VERSION ""

NS_ :

BS_:

BU_: MPAD CVADAS ADCAM ORC EVCU2 EPS ECM CVPAM CADM BSM2 BSM

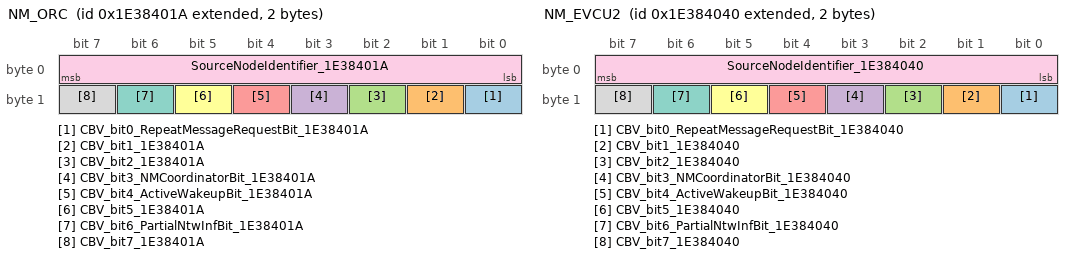
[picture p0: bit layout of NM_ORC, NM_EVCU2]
BO_ 2654486554 NM_ORC: 2 ORC
 SG_ CBV_bit0_RepeatMessageRequestBit_1E38401A : 8|1@0+ (1,0) [0|1] "" CVADAS,ADCAM,MPAD,EVCU2,BSM2,CVPAM,CADM,BSM,EPS,ECM
 SG_ CBV_bit1_1E38401A : 9|1@0+ (1,0) [0|1] "" CVADAS,ADCAM,MPAD,EVCU2,BSM2,CVPAM,CADM,BSM,EPS,ECM
 SG_ CBV_bit2_1E38401A : 10|1@0+ (1,0) [0|1] "" CVADAS,ADCAM,MPAD,EVCU2,BSM2,CVPAM,CADM,BSM,EPS,ECM
 SG_ CBV_bit3_NMCoordinatorBit_1E38401A : 11|1@0+ (1,0) [0|1] "" CVADAS,ADCAM,MPAD,EVCU2,BSM2,CVPAM,CADM,BSM,EPS,ECM
 SG_ CBV_bit4_ActiveWakeupBit_1E38401A : 12|1@0+ (1,0) [0|1] "" CVADAS,ADCAM,MPAD,EVCU2,BSM2,CVPAM,CADM,BSM,EPS,ECM
 SG_ CBV_bit5_1E38401A : 13|1@0+ (1,0) [0|1] "" CVADAS,ADCAM,MPAD,EVCU2,BSM2,CVPAM,CADM,BSM,EPS,ECM
 SG_ CBV_bit6_PartialNtwInfBit_1E38401A : 14|1@0+ (1,0) [0|1] "" CVADAS,ADCAM,MPAD,EVCU2,BSM2,CVPAM,CADM,BSM,EPS,ECM
 SG_ CBV_bit7_1E38401A : 15|1@0+ (1,0) [0|1] "" CVADAS,ADCAM,MPAD,EVCU2,BSM2,CVPAM,CADM,BSM,EPS,ECM
 SG_ SourceNodeIdentifier_1E38401A : 7|8@0+ (1,0) [0|255] "-"  CVADAS,ADCAM,MPAD,EVCU2,BSM2,CVPAM,CADM,BSM,EPS,ECM

BO_ 292 BATTERY_HV_STATUS1: 64 EVCU2
 SG_ BPCM_HV_Trac_Bus_Sts : 36|3@0+ (1,0) [0|7] "" ORC
 SG_ BPCM_HV_Trac_Main_Contac_Sts : 181|3@0+ (1,0) [0|7] "" Vector__XXX
 SG_ BPCM_HV_InternalVoltage : 133|14@0+ (0.1,90.9) [90.9|1729.2] "V"  ORC
 SG_ BPCM_HV_SOC : 33|10@0+ (0.1,0) [0|102.3] "%"  BSM

BO_ 204 AXLE_TORQUE_FD_1: 48 EVCU2
 SG_ Front_AxleTorque_Max : 71|16@0+ (2,-65534) [-65534|65536] "Nm"  BSM
 SG_ Front_AxleTorque_Min : 87|16@0+ (2,-65534) [-65534|65536] "Nm"  BSM
 SG_ Axle_Torque_DrvReqMod : 55|16@0+ (2,-65534) [-65534|65536] "Nm"  ADCAM,MPAD,CADM,BSM
 SG_ Axle_TorqueStatic_D_TTC : 39|16@0+ (2,-65534) [-65534|65536] "Nm"  ADCAM,MPAD,CADM,BSM
 SG_ Total_AxleTorque_Max : 7|16@0+ (2,-65534) [-65534|65536] "Nm"  ADCAM,MPAD,CADM
 SG_ Total_AxleTorque_Min : 23|16@0+ (2,-65534) [-65534|65536] "Nm"  ADCAM,MPAD,CADM,BSM
 SG_ Front_Axle_Est_Regen_Torq : 149|14@0+ (2,0) [0|32764] "Nm"  BSM
 SG_ CRC_AXLE_TORQUE_FD_1 : 319|8@0+ (1,0) [0|255] "-"  ADCAM,CADM,BSM
 SG_ MessageCounter_AXLE_TORQUE_FD_1 : 307|4@0+ (1,0) [0|15] "-"  ADCAM,CADM,BSM
 SG_ Rear_AxleTorque_Min : 119|16@0+ (2,-65534) [-65534|65536] "Nm"  BSM
 SG_ Rear_AxleTorque_Max : 103|16@0+ (2,-65534) [-65534|65536] "Nm"  BSM
 SG_ Rear_Axle_Regen_Capacity : 197|14@0+ (2,0) [0|32764] "Nm"  BSM
 SG_ Rear_Axle_Est_Regen_Torq : 181|14@0+ (2,0) [0|32764] "Nm"  BSM
 SG_ Front_Axle_Regen_Capacity : 165|14@0+ (2,0) [0|32764] "Nm"  BSM

BO_ 205 BRAKE_FD_6: 64 BSM
 SG_ FrontAxle_Rq_BSM : 63|16@0+ (2,-65534) [-65534|65536] "Nm"  EVCU2
 SG_ DriverRequested_AxleTrq_BSM : 159|16@0+ (2,-65534) [-65534|65536] "Nm"  EVCU2,CVPAM,ECM
 SG_ TotalAxle_Rq_BSM : 95|16@0+ (2,-65534) [-65534|65536] "Nm"  ECM
 SG_ Cmnd_TotBrkFrict_AxleTorq : 126|15@0+ (2,0) [0|65532] "Nm"  EVCU2
 SG_ DriverReq_AxleTrq_Enabled_BSM : 175|4@0+ (1,0) [0|15] "" CVADAS,EVCU2,ECM
 SG_ DrvrIntd_TotalBrk_AxleTorq : 142|15@0+ (2,0) [0|65532] "Nm"  EVCU2
 SG_ TotalAxle_Max_Rq_BSM : 51|1@0+ (1,0) [0|1] "" ECM
 SG_ TotalAxle_Min_Rq_BSM : 50|1@0+ (1,0) [0|1] "" ECM
 SG_ FrontAxle_Max_Rq_BSM : 55|1@0+ (1,0) [0|1] "" EVCU2
 SG_ FrontAxle_Min_Rq_BSM : 54|1@0+ (1,0) [0|1] "" EVCU2
 SG_ MessageCounter_BRAKE_FD_6 : 435|4@0+ (1,0) [0|15] "-"  EVCU2,ECM
 SG_ CRC_BRAKE_FD_6 : 447|8@0+ (1,0) [0|255] "-"  EVCU2,ECM
 SG_ RearAxle_Rq_BSM : 79|16@0+ (2,-65534) [-65534|65536] "Nm"  EVCU2
 SG_ RearAxle_Min_Rq_BSM : 52|1@0+ (1,0) [0|1] "" EVCU2
 SG_ RearAxle_Max_Rq_BSM : 53|1@0+ (1,0) [0|1] "" EVCU2

BO_ 1472 TRSCM_FD_1: 32 CVADAS
 SG_ CRC_TRSCM1 : 191|8@0+ (1,0) [0|255] "-"  BSM,EPS,ECM
 SG_ MessageCounter_TRSCM1 : 179|4@0+ (1,0) [0|15] "-"  BSM,EPS,ECM
 SG_ THA_EPB_Req : 95|2@0+ (1,0) [0|3] "" BSM
 SG_ THA_Speed_Limit : 85|5@0+ (1,0) [0|31] "" EVCU2,BSM,EPS,ECM
 SG_ THA_SpeedLimit_Req : 52|2@0+ (1,0) [0|3] "" EVCU2,BSM,ECM
 SG_ THA_STAT : 55|3@0+ (1,0) [0|6] "" EVCU2,BSM,EPS,ECM
 SG_ TRSC_SpeedLimit_Req : 15|4@0+ (1,0) [0|14] "" BSM,ECM
 SG_ TRSC_STAT : 7|3@0+ (1,0) [0|6] "" BSM,EPS,ECM
 SG_ TRSC_VehicleStop_Req : 36|2@0+ (1,0) [0|2] "" BSM
 SG_ TRSC_SteeringTorqueReq : 11|2@0+ (1,0) [0|2] "" EPS
 SG_ TRSC_SteeringTorqueInfo : 31|11@0+ (0.0078125,-8) [-8|7.9921875] "" EPS
 SG_ TRSC_SteeringDamping : 23|8@0+ (0.78125,0) [0|199.21875] "%"  EPS
 SG_ THA_SteeringTorqueReq : 87|2@0+ (1,0) [0|3] "" EPS
 SG_ THA_SteeringTorqueInfo : 63|11@0+ (0.0078125,-8) [-8|7.9921875] "" EPS
 SG_ THA_SteeringDamping : 79|8@0+ (0.78125,0) [0|199.21875] "%"  EPS

BO_ 2654486592 NM_EVCU2: 2 EVCU2
 SG_ CBV_bit0_RepeatMessageRequestBit_1E384040 : 8|1@0+ (1,0) [0|1] "" CVADAS,ADCAM,MPAD,BSM2,CVPAM,CADM,BSM,ORC,EPS,ECM
 SG_ CBV_bit1_1E384040 : 9|1@0+ (1,0) [0|1] "" CVADAS,ADCAM,MPAD,BSM2,CVPAM,CADM,BSM,ORC,EPS,ECM
 SG_ CBV_bit2_1E384040 : 10|1@0+ (1,0) [0|1] "" CVADAS,ADCAM,MPAD,BSM2,CVPAM,CADM,BSM,ORC,EPS,ECM
 SG_ CBV_bit3_NMCoordinatorBit_1E384040 : 11|1@0+ (1,0) [0|1] "" CVADAS,ADCAM,MPAD,BSM2,CVPAM,CADM,BSM,ORC,EPS,ECM
 SG_ CBV_bit4_ActiveWakeupBit_1E384040 : 12|1@0+ (1,0) [0|1] "" CVADAS,ADCAM,MPAD,BSM2,CVPAM,CADM,BSM,ORC,EPS,ECM
 SG_ CBV_bit5_1E384040 : 13|1@0+ (1,0) [0|1] "" CVADAS,ADCAM,MPAD,BSM2,CVPAM,CADM,BSM,ORC,EPS,ECM
 SG_ CBV_bit6_PartialNtwInfBit_1E384040 : 14|1@0+ (1,0) [0|1] "" CVADAS,ADCAM,MPAD,BSM2,CVPAM,CADM,BSM,ORC,EPS,ECM
 SG_ CBV_bit7_1E384040 : 15|1@0+ (1,0) [0|1] "" CVADAS,ADCAM,MPAD,BSM2,CVPAM,CADM,BSM,ORC,EPS,ECM
 SG_ SourceNodeIdentifier_1E384040 : 7|8@0+ (1,0) [0|255] "-"  CVADAS,ADCAM,MPAD,BSM2,CVPAM,CADM,BSM,ORC,EPS,ECM

BO_ 263 PT_SYSTEM_FD_1: 64 EVCU2
 SG_ CRC_PT_SYSTEM_FD_1 : 447|8@0+ (1,0) [0|255] "-"  ADCAM,MPAD,CADM,BSM,EPS,ECM
 SG_ GasPedalPosition_PT : 31|8@0+ (0.392,0) [0|99.96] "%"  BSM
 SG_ GasPedalPositionFailSts_PT : 145|1@0+ (1,0) [0|1] "" ADCAM,CADM,BSM
 SG_ MessageCounter_PT_SYSTEM_FD_1 : 435|4@0+ (1,0) [0|15] "-"  ADCAM,MPAD,CADM,BSM,EPS,ECM
 SG_ DriveReady_PT : 166|1@0+ (1,0) [0|1] "" BSM,EPS
 SG_ GearEngaged_PT : 132|4@0+ (1,0) [0|15] "" ADCAM,BSM2,BSM,EPS
 SG_ GearEngagedForDisplay_PT : 12|5@0+ (1,0) [0|31] "" CVADAS,ADCAM,EPS
 SG_ PowertrainPrplsnActv_PT : 146|1@0+ (1,0) [0|1] "" CVADAS,ADCAM,MPAD,CADM,BSM,EPS
 SG_ TargetGear_PT : 55|4@0+ (1,0) [0|15] "" EPS
 SG_ ShiftLeverPosition_PT : 51|4@0+ (1,0) [0|15] "" ADCAM,CVPAM,BSM,EPS
 SG_ PdlPosActual_PT : 39|8@0+ (0.4,0) [0|102] "%"  CVADAS,ADCAM,MPAD,BSM2,CVPAM,CADM,BSM
 SG_ SpeedLimitSts_PT : 140|3@0+ (1,0) [0|7] "" Vector__XXX
 SG_ ISASts_PT : 149|1@0+ (1,0) [0|1] "" Vector__XXX
 SG_ EVCU2_THA_Resp : 220|2@0+ (1,0) [0|3] "" CVADAS

BO_ 1580 HYBRID_POWERTRAIN6: 32 EVCU2
 SG_ Motor2_RPM : 23|16@0+ (1,-32768) [-32768|32767] "RPM"  ORC
 SG_ Motor1_RPM : 7|16@0+ (1,-32768) [-32768|32767] "RPM"  ORC

BO_ 299 ADAS_FD_INFO3: 32 ADCAM
 SG_ ACC_Axle_Torque_Enabled : 180|1@0+ (1,0) [0|1] "" BSM
 SG_ ACC_Axle_Torque : 7|16@0+ (2,-65534) [-65534|65536] "Nm"  BSM
 SG_ MessageCounter_ADAS_FD_INFO3 : 179|4@0+ (1,0) [0|15] "-"  MPAD,BSM
 SG_ CRC_ADAS_FD_INFO3 : 191|8@0+ (1,0) [0|255] "-"  MPAD,BSM

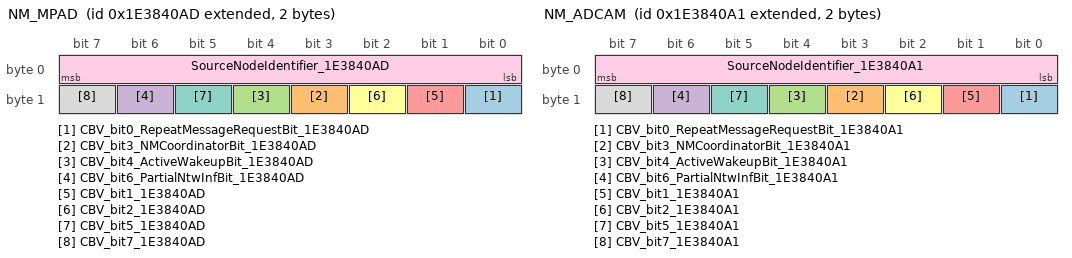
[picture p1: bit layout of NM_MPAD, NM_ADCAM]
BO_ 2654486701 NM_MPAD: 2 MPAD
 SG_ CBV_bit0_RepeatMessageRequestBit_1E3840AD : 8|1@0+ (1,0) [0|1] "-"  CVADAS,ADCAM,EVCU2,BSM2,BSM,ORC,EPS
 SG_ CBV_bit3_NMCoordinatorBit_1E3840AD : 11|1@0+ (1,0) [0|1] "-"  CVADAS,ADCAM,EVCU2,BSM2,BSM,ORC,EPS
 SG_ CBV_bit4_ActiveWakeupBit_1E3840AD : 12|1@0+ (1,0) [0|1] "-"  CVADAS,ADCAM,EVCU2,BSM2,BSM,ORC,EPS
 SG_ CBV_bit6_PartialNtwInfBit_1E3840AD : 14|1@0+ (1,0) [0|1] "-"  CVADAS,ADCAM,EVCU2,BSM2,BSM,ORC,EPS
 SG_ CBV_bit1_1E3840AD : 9|1@0+ (1,0) [0|1] "" CVADAS,ADCAM,EVCU2,BSM2,BSM,ORC,EPS
 SG_ CBV_bit2_1E3840AD : 10|1@0+ (1,0) [0|1] "" CVADAS,ADCAM,EVCU2,BSM2,BSM,ORC,EPS
 SG_ CBV_bit5_1E3840AD : 13|1@0+ (1,0) [0|1] "" CVADAS,ADCAM,EVCU2,BSM2,BSM,ORC,EPS
 SG_ CBV_bit7_1E3840AD : 15|1@0+ (1,0) [0|1] "" CVADAS,ADCAM,EVCU2,BSM2,BSM,ORC,EPS
 SG_ SourceNodeIdentifier_1E3840AD : 7|8@0+ (1,0) [0|255] "-"  CVADAS,ADCAM,EVCU2,BSM2,BSM,ORC,EPS

BO_ 2654486689 NM_ADCAM: 2 ADCAM
 SG_ CBV_bit0_RepeatMessageRequestBit_1E3840A1 : 8|1@0+ (1,0) [0|1] "-"  CVADAS,MPAD,EVCU2,BSM2,BSM,ORC,EPS,ECM
 SG_ CBV_bit3_NMCoordinatorBit_1E3840A1 : 11|1@0+ (1,0) [0|1] "-"  CVADAS,MPAD,EVCU2,BSM2,BSM,ORC,EPS,ECM
 SG_ CBV_bit4_ActiveWakeupBit_1E3840A1 : 12|1@0+ (1,0) [0|1] "-"  CVADAS,MPAD,EVCU2,BSM2,BSM,ORC,EPS,ECM
 SG_ CBV_bit6_PartialNtwInfBit_1E3840A1 : 14|1@0+ (1,0) [0|1] "-"  CVADAS,MPAD,EVCU2,BSM2,BSM,ORC,EPS,ECM
 SG_ CBV_bit1_1E3840A1 : 9|1@0+ (1,0) [0|1] "" CVADAS,MPAD,EVCU2,BSM2,BSM,ORC,EPS,ECM
 SG_ CBV_bit2_1E3840A1 : 10|1@0+ (1,0) [0|1] "" CVADAS,MPAD,EVCU2,BSM2,BSM,ORC,EPS,ECM
 SG_ CBV_bit5_1E3840A1 : 13|1@0+ (1,0) [0|1] "" CVADAS,MPAD,EVCU2,BSM2,BSM,ORC,EPS,ECM
 SG_ CBV_bit7_1E3840A1 : 15|1@0+ (1,0) [0|1] "" CVADAS,MPAD,EVCU2,BSM2,BSM,ORC,EPS,ECM
 SG_ SourceNodeIdentifier_1E3840A1 : 7|8@0+ (1,0) [0|255] "-"  CVADAS,MPAD,EVCU2,BSM2,BSM,ORC,EPS,ECM

BO_ 210 ADAS_FD_INFO3_VIP: 32 ADCAM
 SG_ ACC_Axle_Torque_VIP : 7|16@0+ (2,-65534) [-65534|65536] "Nm"  MPAD

BO_ 209 ADAS_FD_INFO_VIP: 32 ADCAM
 SG_ Intervention_VIP : 163|12@0+ (0.01,-16) [-16|24.95] "m/s2"  MPAD
 SG_ AEB_Type_VIP : 167|4@0+ (1,0) [0|15] "No_Unit"  MPAD
 SG_ ACC_Systemsts_VIP : 183|4@0+ (1,0) [0|15] "No_Unit"  MPAD
 SG_ ACC_Engine_Torque_Enabled_VIP : 111|1@0+ (1,0) [0|1] "No_Unit"  MPAD
 SG_ TorqueOverlaySteeringReq_VIP : 130|11@0+ (0.0048828125,-5) [-5|4.9951171875] "No_Unit"  MPAD
 SG_ SteeringVibration_Type_VIP : 67|4@0+ (1,0) [0|15] "No_Unit"  MPAD
 SG_ SteeringVibration_Rq_VIP : 135|1@0+ (1,0) [0|1] "No_Unit"  MPAD
 SG_ Prefill_Req_VIP : 91|1@0+ (1,0) [0|1] "No_Unit"  MPAD
 SG_ PEB_SystemSts_VIP : 90|1@0+ (1,0) [0|1] "No_Unit"  MPAD
 SG_ Object_Dist_VIP : 127|8@0+ (1,0) [0|255] "m"  MPAD
 SG_ LKA_LAT_CTRL_RequestSts_VIP : 108|2@0+ (1,0) [0|3] "No_Unit"  MPAD
 SG_ LC_Jerk_VIP : 104|1@0+ (1,0) [0|1] "No_Unit"  MPAD
 SG_ GrMax_Rq_ACC_VIP : 150|4@0+ (1,0) [0|15] "No_Unit"  MPAD
 SG_ DDD_SystemSts_VIP : 103|1@0+ (1,0) [0|1] "No_Unit"  MPAD
 SG_ DDD_Setting_Avail_VIP : 102|1@0+ (1,0) [0|1] "No_Unit"  MPAD
 SG_ CIPV_Fused_VIP : 101|1@0+ (1,0) [0|1] "No_Unit"  MPAD
 SG_ Brake_Jerk_Req_VIP : 100|1@0+ (1,0) [0|1] "No_Unit"  MPAD
 SG_ AEB_Systemsts_VIP : 99|2@0+ (1,0) [0|3] "No_Unit"  MPAD
 SG_ AEB_Sensitivity_Setting_VIP : 1|2@0+ (1,0) [0|3] "No_Unit"  MPAD
 SG_ ACC_DsrSpeedKPH_VIP : 119|8@0+ (1,0) [0|255] "km/h"  MPAD
 SG_ MessageCounter_ADAS_FD_INFO_VIP : 179|4@0+ (1,0) [0|15] "No_Unit"  MPAD
 SG_ CRC_ADAS_FD_INFO_VIP : 191|8@0+ (1,0) [0|255] "No_Unit"  MPAD

BO_ 616 ADAS_FD_HMI_VIP: 32 ADCAM
 SG_ Set_Speed_MPH_VIP : 15|8@0+ (1,0) [0|255] "mph"  MPAD
 SG_ Set_Speed_KPH_VIP : 7|8@0+ (1,0) [0|255] "kph"  MPAD
 SG_ RR_Chime_RqSts_VIP : 99|1@0+ (1,0) [0|1] "No_Unit"  MPAD
 SG_ PEB_Setting_Avail_VIP : 78|1@0+ (1,0) [0|1] "No_Unit"  MPAD
 SG_ LR_Chime_RqSts_VIP : 100|1@0+ (1,0) [0|1] "No_Unit"  MPAD
 SG_ LKA_FailSts_VIP : 84|1@0+ (1,0) [0|1] "No_Unit"  MPAD
 SG_ LKA_Blind_VIP : 86|1@0+ (1,0) [0|1] "No_Unit"  MPAD
 SG_ ICA_Blind_VIP : 55|1@0+ (1,0) [0|1] "No_Unit"  MPAD
 SG_ FCW_Setting_Avail_VIP : 77|1@0+ (1,0) [0|1] "No_Unit"  MPAD
 SG_ DDD_FailSts_VIP : 96|1@0+ (1,0) [0|1] "No_Unit"  MPAD
 SG_ DDD_DispPopupSts_VIP : 39|2@0+ (1,0) [0|3] "No_Unit"  MPAD
 SG_ BSS_TrailerSts_VIP : 175|3@0+ (1,0) [0|7] "No_Unit"  MPAD
 SG_ BSS_SRV_RQSts_VIP : 88|1@0+ (1,0) [0|1] "No_Unit"  MPAD
 SG_ BSS_DispPopoupSts_VIP : 132|3@0+ (1,0) [0|7] "No_Unit"  MPAD
 SG_ BSS_CFG_STATSts_VIP : 103|2@0+ (1,0) [0|3] "No_Unit"  MPAD
 SG_ BSS_Blind_RQSts_VIP : 101|1@0+ (1,0) [0|1] "No_Unit"  MPAD
 SG_ BlindSpotRightWarn_VIP : 171|2@0+ (1,0) [0|3] "No_Unit"  MPAD
 SG_ BlindSpotLeftWarn_VIP : 105|2@0+ (1,0) [0|3] "No_unit"  MPAD
 SG_ AEB_Limited_VIP : 72|1@0+ (1,0) [0|1] "No_Unit"  MPAD
 SG_ AEB_Limit_Fail_VIP : 74|1@0+ (1,0) [0|1] "No_Unit"  MPAD
 SG_ AEB_FailSts_VIP : 83|1@0+ (1,0) [0|1] "No_Unit"  MPAD
 SG_ AEB_DispPopupSts_VIP : 37|6@0+ (1,0) [0|63] "No_Unit"  MPAD
 SG_ AEB_Blind_VIP : 76|1@0+ (1,0) [0|1] "No_Unit"  MPAD
 SG_ MessageCounter_ADAS_FD_HMI_VIP : 179|4@0+ (1,0) [0|15] "No_Unit"  MPAD
 SG_ CRC_ADAS_FD_HMI_VIP : 191|8@0+ (1,0) [0|255] "No_Unit"  MPAD

BO_ 213 VIP_INFO_FD: 32 MPAD
 SG_ ACCFSafe_D5 : 7|8@0+ (1,0) [0|255] "No_Unit"  ADCAM
 SG_ AEB_Type_Brk_D5 : 11|4@0+ (1,0) [0|15] "No_Unit"  ADCAM
 SG_ DASEngReqPos_D5 : 20|1@0+ (1,0) [0|1] "No_Unit"  ADCAM
 SG_ LKA_LAT_CTRL_ResponseSts_D5 : 13|2@0+ (1,0) [0|3] "No_Unit"  ADCAM
 SG_ RRCC_Cancel_Req_D5 : 15|2@0+ (1,0) [0|3] "No_Unit"  ADCAM
 SG_ MessageCounter_VIP_INFO_FD : 179|4@0+ (1,0) [0|15] "No_Unit"  ADCAM
 SG_ CRC_VIP_INFO_FD : 191|8@0+ (1,0) [0|255] "No_Unit"  ADCAM

BO_ 97 GT_MASTER_FD: 16 MPAD
 SG_ SyncTime : 39|32@0+ (1,0) [0|0] "" CVADAS,BSM2,BSM,ORC
 SG_ OfsTimeSec : 71|32@0+ (1,0) [0|0] "sec"  CVADAS,BSM2,BSM,ORC
 SG_ OfsTimeNSec : 103|32@0+ (1,0) [0|0] "" CVADAS,BSM2,BSM,ORC
 SG_ GTS_Type : 7|8@0+ (1,0) [0|255] "" CVADAS,BSM2,BSM,ORC
 SG_ GTS_SC : 19|4@0+ (1,0) [0|15] "" CVADAS,BSM2,BSM,ORC
 SG_ GTS_D : 23|4@0+ (1,0) [0|16] "" CVADAS,BSM2,BSM,ORC
 SG_ GTS_CRC : 15|8@0+ (1,0) [0|255] "" CVADAS,BSM2,BSM,ORC
 SG_ GTS_Byte3 : 31|8@0+ (1,0) [0|255] "" CVADAS,BSM2,BSM,ORC

BO_ 734 ADAS_FD_LANES_2: 64 CVADAS
 SG_ Segment_8_Y2 : 369|10@0+ (0.01,-5) [-5|5.23] "m"  CADM
 SG_ Segment_8_Y1 : 201|10@0+ (0.01,-5) [-5|5.23] "m"  CADM
 SG_ Segment_8_X2 : 290|11@0+ (0.03,-21) [-21|40.41] "m"  CADM
 SG_ Segment_8_X1 : 122|11@0+ (0.03,-21) [-21|40.41] "m"  CADM
 SG_ Segment_8_ID : 43|4@0+ (1,0) [0|15] "" CADM
 SG_ Segment_8_Confidence : 411|4@0+ (0.1,0) [0|1.5] "" CADM
 SG_ Segment_7_Y2 : 363|10@0+ (0.01,-5) [-5|5.23] "m"  CADM
 SG_ Segment_7_Y1 : 195|10@0+ (0.01,-5) [-5|5.23] "m"  CADM
 SG_ Segment_7_X2 : 285|11@0+ (0.03,-21) [-21|40.41] "m"  CADM
 SG_ Segment_7_X1 : 117|11@0+ (0.03,-21) [-21|40.41] "m"  CADM
 SG_ Segment_7_ID : 47|4@0+ (1,0) [0|15] "" CADM
 SG_ Segment_7_Confidence : 415|4@0+ (0.1,0) [0|1.5] "" CADM
 SG_ Segment_6_Y2 : 357|10@0+ (0.01,-5) [-5|5.23] "m"  CADM
 SG_ Segment_6_Y1 : 189|10@0+ (0.01,-5) [-5|5.23] "m"  CADM
 SG_ Segment_6_X2 : 264|11@0+ (0.03,-21) [-21|40.41] "m"  CADM
 SG_ Segment_6_X1 : 96|11@0+ (0.03,-21) [-21|40.41] "m"  CADM
 SG_ Segment_6_ID : 35|4@0+ (1,0) [0|15] "" CADM
 SG_ Segment_6_Confidence : 403|4@0+ (0.1,0) [0|1.5] "" CADM
 SG_ Segment_5_Y2 : 351|10@0+ (0.01,-5) [-5|5.23] "m"  CADM
 SG_ Segment_5_Y1 : 183|10@0+ (0.01,-5) [-5|5.23] "m"  CADM
 SG_ Segment_5_X2 : 259|11@0+ (0.03,-21) [-21|40.41] "m"  CADM
 SG_ Segment_5_X1 : 91|11@0+ (0.03,-21) [-21|40.41] "m"  CADM
 SG_ Segment_5_ID : 39|4@0+ (1,0) [0|15] "" CADM
 SG_ Segment_5_Confidence : 407|4@0+ (0.1,0) [0|1.5] "" CADM
 SG_ Segment_4_Y2 : 329|10@0+ (0.01,-5) [-5|5.23] "m"  CADM
 SG_ Segment_4_Y1 : 161|10@0+ (0.01,-5) [-5|5.23] "m"  CADM
 SG_ Segment_4_X2 : 254|11@0+ (0.03,-21) [-21|40.41] "m"  CADM
 SG_ Segment_4_X1 : 86|11@0+ (0.03,-21) [-21|40.41] "m"  CADM
 SG_ Segment_4_ID : 27|4@0+ (1,0) [0|15] "" CADM
 SG_ Segment_4_Confidence : 395|4@0+ (0.1,0) [0|1.5] "" CADM
 SG_ Segment_3_Y2 : 323|10@0+ (0.01,-5) [-5|5.23] "m"  CADM
 SG_ Segment_3_Y1 : 155|10@0+ (0.01,-5) [-5|5.23] "m"  CADM
 SG_ Segment_3_X2 : 233|11@0+ (0.03,-21) [-21|40.41] "m"  CADM
 SG_ Segment_3_X1 : 65|11@0+ (0.03,-21) [-21|40.41] "m"  CADM
 SG_ Segment_3_ID : 31|4@0+ (1,0) [0|15] "" CADM
 SG_ Segment_3_Confidence : 399|4@0+ (0.1,0) [0|1.5] "" CADM
 SG_ Segment_2_Y2 : 317|10@0+ (0.01,-5) [-5|5.23] "m"  CADM
 SG_ Segment_2_Y1 : 149|10@0+ (0.01,-5) [-5|5.23] "m"  CADM
 SG_ Segment_2_X2 : 228|11@0+ (0.03,-21) [-21|40.41] "m"  CADM
 SG_ Segment_2_X1 : 60|11@0+ (0.03,-21) [-21|40.41] "m"  CADM
 SG_ Segment_2_ID : 19|4@0+ (1,0) [0|15] "" CADM
 SG_ Segment_2_Confidence : 387|4@0+ (0.1,0) [0|1.5] "" CADM
 SG_ Segment_1_Y2 : 311|10@0+ (0.01,-5) [-5|5.23] "m"  CADM
 SG_ Segment_1_Y1 : 143|10@0+ (0.01,-5) [-5|5.23] "m"  CADM
 SG_ Segment_1_X2 : 223|11@0+ (0.03,-21) [-21|40.41] "m"  CADM
 SG_ Segment_1_X1 : 55|11@0+ (0.03,-21) [-21|40.41] "m"  CADM
 SG_ Segment_1_ID : 23|4@0+ (1,0) [0|15] "" CADM
 SG_ Segment_1_Confidence : 391|4@0+ (0.1,0) [0|1.5] "" CADM
 SG_ MessageCounter_ADAS_FD_LANES_2 : 435|4@0+ (1,0) [0|15] "-"  CADM
 SG_ MAC_ADAS_FD_LANES_2 : 471|48@0+ (1,0) [0|0] "-"  CADM
 SG_ Frame_Index_Lanes_2 : 7|16@0+ (1,0) [0|65535] "" CADM
 SG_ CRC_ADAS_FD_LANES_2 : 447|8@0+ (1,0) [0|255] "-"  CADM
 SG_ Cntr_ADAS_FD_LANES_2 : 455|16@0+ (1,0) [0|65535] "-"  CADM
 SG_ Reserved_for_functional_safety_2DE : 431|12@0+ (0,0) [0|0] "" CADM

BO_ 730 ADAS_FD_LANES_1: 64 CVADAS
 SG_ MessageCounter_ADAS_FD_LANES_1 : 435|4@0+ (1,0) [0|15] "-"  CADM
 SG_ MAC_ADAS_FD_LANES_1 : 471|48@0+ (1,0) [0|0] "-"  CADM
 SG_ Line_4_Type : 179|4@0+ (1,0) [0|15] "" CADM
 SG_ Line_4_Start_Range : 294|7@0+ (0.5,-25) [-25|38.5] "m"  CADM
 SG_ Line_4_Offset : 209|10@0+ (0.01,-5) [-5|5.23] "m"  CADM
 SG_ Line_4_Heading : 249|10@0+ (0.0009765625,-0.357) [-0.357|0.6420234375] "rad"  CADM
 SG_ Line_4_End_Range : 326|7@0+ (0.5,-25) [-25|38.5] "m"  CADM
 SG_ Line_4_Curvature_Rate : 143|16@0+ (3.7252902985E-09,-0.000122) [-0.000122|0.0001221368997121975] "" CADM
 SG_ Line_4_Curvature : 79|16@0+ (9.77E-07,-0.032) [-0.032|0.032027694999999995] "" CADM
 SG_ Line_4_Confidence : 163|4@0+ (0.1,0) [0|1.5] "" CADM
 SG_ Line_3_Type : 183|4@0+ (1,0) [0|15] "" CADM
 SG_ Line_3_Start_Range : 287|7@0+ (0.5,-25) [-25|38.5] "m"  CADM
 SG_ Line_3_Offset : 203|10@0+ (0.01,-5) [-5|5.23] "m"  CADM
 SG_ Line_3_Heading : 243|10@0+ (0.0009765625,-0.357) [-0.357|0.6420234375] "rad"  CADM
 SG_ Line_3_End_Range : 319|7@0+ (0.5,-25) [-25|38.5] "m"  CADM
 SG_ Line_3_Curvature_Rate : 127|16@0+ (3.7252902985E-09,-0.000122) [-0.000122|0.0001221368997121975] "" CADM
 SG_ Line_3_Curvature : 63|16@0+ (9.77E-07,-0.032) [-0.032|0.032027694999999995] "" CADM
 SG_ Line_3_Confidence : 167|4@0+ (0.1,0) [0|1.5] "" CADM
 SG_ Line_2_Type : 171|4@0+ (1,0) [0|15] "" CADM
 SG_ Line_2_Start_Range : 278|7@0+ (0.5,-25) [-25|38.5] "m"  CADM
 SG_ Line_2_Offset : 197|10@0+ (0.01,-5) [-5|5.23] "m"  CADM
 SG_ Line_2_Heading : 237|10@0+ (0.0009765625,-0.357) [-0.357|0.6420234375] "rad"  CADM
 SG_ Line_2_End_Range : 310|7@0+ (0.5,-25) [-25|38.5] "m"  CADM
 SG_ Line_2_Curvature_Rate : 111|16@0+ (3.7252902985E-09,-0.000122) [-0.000122|0.0001221368997121975] "" CADM
 SG_ Line_2_Curvature : 47|16@0+ (9.77E-07,-0.032) [-0.032|0.032027694999999995] "" CADM
 SG_ Line_2_Confidence : 155|4@0+ (0.1,0) [0|1.5] "" CADM
 SG_ Line_1_Type : 175|4@0+ (1,0) [0|15] "" CADM
 SG_ Line_1_Start_Range : 271|7@0+ (0.5,-25) [-25|38.5] "m"  CADM
 SG_ Line_1_Offset : 191|10@0+ (0.01,-5) [-5|5.23] "m"  CADM
 SG_ Line_1_Heading : 231|10@0+ (0.0009765625,-0.357) [-0.357|0.6420234375] "rad"  CADM
 SG_ Line_1_End_Range : 303|7@0+ (0.5,-25) [-25|38.5] "m"  CADM
 SG_ Line_1_Curvature_Rate : 95|16@0+ (3.7252902985E-09,-0.000122) [-0.000122|0.0001221368997121975] "" CADM
 SG_ Line_1_Curvature : 31|16@0+ (9.77E-07,-0.032) [-0.032|0.032027694999999995] "" CADM
 SG_ Line_1_Confidence : 159|4@0+ (0.1,0) [0|1.5] "" CADM
 SG_ Health_Lane_Detection : 19|2@0+ (1,0) [0|3] "" CADM
 SG_ Health_Front_Object_Detection : 17|2@0+ (1,0) [0|3] "" CADM
 SG_ Frame_Index_Lanes_1 : 7|16@0+ (1,0) [0|65535] "" CADM
 SG_ FOD_Confidence : 335|2@0+ (1,0) [0|3] "" CADM
 SG_ CRC_ADAS_FD_LANES_1 : 447|8@0+ (1,0) [0|255] "-"  CADM
 SG_ Cntr_ADAS_FD_LANES_1 : 455|16@0+ (1,0) [0|65535] "-"  CADM
 SG_ Camera_Status : 23|4@0+ (1,0) [0|15] "" CADM
 SG_ Reserved_for_functional_safety_2DA : 431|12@0+ (0,0) [0|0] "" CADM

BO_TX_BU_ 1472 : CVADAS,CVPAM;
BO_TX_BU_ 299 : ADCAM,MPAD,CADM;
CM_ SG_ 292 BPCM_HV_Trac_Main_Contac_Sts "Traction main contactor physical relay status";
CM_ SG_ 204 Front_AxleTorque_Max "Maximum front Axle torque";
CM_ SG_ 204 Front_AxleTorque_Min "Minimum front Axle torque";
CM_ SG_ 204 Axle_Torque_DrvReqMod "Driver requested Axle torque raw (no torque shaping)";
CM_ SG_ 204 Axle_TorqueStatic_D_TTC "Driver requested Axle torque (filtered/ torque shaped)";
CM_ SG_ 204 Total_AxleTorque_Max "Maximum total Axle torque";
CM_ SG_ 204 Total_AxleTorque_Min "Minimum total Axle torque";
CM_ SG_ 204 Front_Axle_Est_Regen_Torq "Estimated regen Braking Torque at the Front axle";
CM_ SG_ 204 CRC_AXLE_TORQUE_FD_1 "CRC according to SAE J1850 standard at each frame transmission.";
CM_ SG_ 204 MessageCounter_AXLE_TORQUE_FD_1 "This signal is a counter used for safety checks strategies. This counter is incremented of 1 (one) unit at each frame transmission.";
CM_ SG_ 205 FrontAxle_Rq_BSM "Front axle traction control torque request";
CM_ SG_ 205 DriverRequested_AxleTrq_BSM "Virtual driver torque request from BSM";
CM_ SG_ 205 TotalAxle_Rq_BSM "Combined axle traction torque request";
CM_ SG_ 205 Cmnd_TotBrkFrict_AxleTorq "Commanded Total Brake Friction torque in Axle domain";
CM_ SG_ 205 DriverReq_AxleTrq_Enabled_BSM "It indicates the request to enable virtual driver torque interface for BSM driver functions";
CM_ SG_ 205 DrvrIntd_TotalBrk_AxleTorq "Total Brake Torque in Axle domain";
CM_ SG_ 205 TotalAxle_Max_Rq_BSM "Combined axle traction torque max limit flag. Active = [1]";
CM_ SG_ 205 TotalAxle_Min_Rq_BSM "Combined axle traction torque min limit flag. Active = [1]";
CM_ SG_ 205 FrontAxle_Max_Rq_BSM "Front axle traction torque max limit flag. Active = [1]";
CM_ SG_ 205 FrontAxle_Min_Rq_BSM "Front axle traction torque min limit flag. Active = [1]";
CM_ SG_ 205 MessageCounter_BRAKE_FD_6 "This signal is a counter used for safety checks strategies. This counter is incremented of 1 (one) unit at each frame transmission.";
CM_ SG_ 205 CRC_BRAKE_FD_6 "CRC according to SAE J1850 standard at each frame transmission.";
CM_ SG_ 1472 CRC_TRSCM1 "CRC according to SAE J1850 standard at each frame transmission.";
CM_ SG_ 1472 MessageCounter_TRSCM1 "This signal is a counter used for safety checks strategies. This counter is incremented of 1 (one) unit at each frame transmission.";
CM_ SG_ 1472 THA_EPB_Req "THA EPB securement request";
CM_ SG_ 1472 THA_Speed_Limit "THA Speed Limiter Threshold";
CM_ SG_ 1472 THA_SpeedLimit_Req "THA requested speed limit";
CM_ SG_ 1472 THA_STAT "Current trailer hitch assist maneuver state";
CM_ SG_ 1472 TRSC_SpeedLimit_Req "TRSC ECM Speed limit request";
CM_ SG_ 1472 TRSC_STAT "Trailer Reverse steering status signal";
CM_ SG_ 1472 TRSC_VehicleStop_Req "TRSC break activation request";
CM_ SG_ 263 CRC_PT_SYSTEM_FD_1 "CRC according to SAE J1850 standard at each frame transmission.";
CM_ SG_ 263 GasPedalPosition_PT "Gas Pedal Position in percentage";
CM_ SG_ 263 GasPedalPositionFailSts_PT "Gas Pedal Position Failure Status";
CM_ SG_ 263 MessageCounter_PT_SYSTEM_FD_1 "This signal is a counter used for safety checks strategies. This counter is incremented of 1 (one) unit at each frame transmission.";
CM_ SG_ 263 DriveReady_PT "Drive Ready allowed status";
CM_ SG_ 263 GearEngaged_PT "Current engaged gear";
CM_ SG_ 263 GearEngagedForDisplay_PT "Transmission Gear Engaged signal for the instrument cluster display";
CM_ SG_ 263 PowertrainPrplsnActv_PT "Powertrain Propulsion System Status";
CM_ SG_ 292 BPCM_HV_InternalVoltage "Battery internal voltage.";
CM_ SG_ 292 BPCM_HV_SOC "State of Charge";
CM_ SG_ 263 TargetGear_PT "Intended Gear that the transmission will shift to.";
CM_ SG_ 263 ShiftLeverPosition_PT "Shift Lever Position";
CM_ SG_ 263 PdlPosActual_PT "Actual Pedal Position";
CM_ SG_ 205 RearAxle_Rq_BSM "Rear axle traction control torque request";
CM_ SG_ 205 RearAxle_Min_Rq_BSM "Rear axle traction torque min limit  flag. Active = [1]";
CM_ SG_ 205 RearAxle_Max_Rq_BSM "Rear axle traction torque max limit  flag. Active = [1]";
CM_ SG_ 204 Rear_AxleTorque_Min "Minimum rear Axle torque";
CM_ SG_ 204 Rear_AxleTorque_Max "Maximum rear Axle torque";
CM_ SG_ 204 Rear_Axle_Regen_Capacity "Regenerative Braking rear Axle Torque Capability";
CM_ SG_ 204 Rear_Axle_Est_Regen_Torq "Estimated regen Braking Torque at the Rear axle";
CM_ SG_ 299 ACC_Axle_Torque_Enabled "An enable bit that axle torque commands should be followed";
CM_ SG_ 299 ACC_Axle_Torque "ACC requested Axle Torque";
CM_ SG_ 263 SpeedLimitSts_PT "Speed limiter status";
CM_ SG_ 263 ISASts_PT "Intelligent Speed Assist status";
CM_ SG_ 210 ACC_Axle_Torque_VIP "ACC requested Axle Torque";
CM_ SG_ 209 Intervention_VIP "Request to set target acceleration/deceleration for any feature";
CM_ SG_ 209 AEB_Type_VIP "AEB Type";
CM_ SG_ 209 ACC_Systemsts_VIP "ACC System Status";
CM_ SG_ 209 ACC_Engine_Torque_Enabled_VIP "An enable bit that Torque commands should be followed";
CM_ SG_ 616 Set_Speed_MPH_VIP "Speed shown by IPC, which ACC is controlling in MPH";
CM_ SG_ 616 Set_Speed_KPH_VIP "Speed shown by IPC, which ACC is controlling in KPH";
CM_ SG_ 1472 TRSC_SteeringTorqueReq "TRSC steering torque overlay activation request";
CM_ SG_ 1472 TRSC_SteeringTorqueInfo "TRSC Steering Torque";
CM_ SG_ 1472 TRSC_SteeringDamping "TRSC Steering damping percentage";
CM_ SG_ 1472 THA_SteeringTorqueReq "Trailer Hitch Assist steering torque request";
CM_ SG_ 1472 THA_SteeringTorqueInfo "THA Steering Torque";
CM_ SG_ 1472 THA_SteeringDamping "THA Steering Damping";
CM_ SG_ 1580 Motor2_RPM "Motor 2 speed";
CM_ SG_ 1580 Motor1_RPM "Motor 1 speed";
CM_ SG_ 299 MessageCounter_ADAS_FD_INFO3 "This signal is a counter used for safety checks strategies. This counter is incremented of 1 (one) unit at each frame transmission.";
CM_ SG_ 299 CRC_ADAS_FD_INFO3 "CRC according to SAE J1850 standard at each frame transmission.";
CM_ SG_ 97 GTS_Type "Global Time Sync type of frame";
CM_ SG_ 97 GTS_SC "Sequence Counter";
CM_ SG_ 97 GTS_CRC "Global Time Sync CRC";
CM_ SG_ 209 TorqueOverlaySteeringReq_VIP "TorqueOverlaySteeringReq";
CM_ SG_ 209 SteeringVibration_Type_VIP "Type of Steering Wheel Vibration Request";
CM_ SG_ 209 SteeringVibration_Rq_VIP "Request to activate Steering Wheel Vibration";
CM_ SG_ 209 Prefill_Req_VIP "Prefill command of Brake System by DASM";
CM_ SG_ 209 PEB_SystemSts_VIP "PEB System Status";
CM_ SG_ 209 Object_Dist_VIP "It indicates the distance to the recognized object";
CM_ SG_ 209 LKA_LAT_CTRL_RequestSts_VIP "LKA_LAT_CTRL_RequestSts";
CM_ SG_ 209 LC_Jerk_VIP "Lane Centering request for brake jerk";
CM_ SG_ 209 GrMax_Rq_ACC_VIP "Used to request Max Gear from TCM";
CM_ SG_ 209 DDD_SystemSts_VIP "DDD System Status";
CM_ SG_ 209 DDD_Setting_Avail_VIP "DDD_Setting Av Status";
CM_ SG_ 209 CIPV_Fused_VIP "Closest in-path vehicle is fused True = 1";
CM_ SG_ 209 Brake_Jerk_Req_VIP "Request from DASM to perform Jerk Warning";
CM_ SG_ 209 AEB_Systemsts_VIP "AEB System Status";
CM_ SG_ 209 AEB_Sensitivity_Setting_VIP "AEB sensitivity status";
CM_ SG_ 209 ACC_DsrSpeedKPH_VIP "Desired speed in kilometers per hour";
CM_ SG_ 616 RR_Chime_RqSts_VIP "BSM right rear chime on request";
CM_ SG_ 616 PEB_Setting_Avail_VIP "PEB setting availability";
CM_ SG_ 616 LR_Chime_RqSts_VIP "BSM Left rear chime on request";
CM_ SG_ 616 LKA_FailSts_VIP "LKA_FailSts";
CM_ SG_ 616 LKA_Blind_VIP "LKA_Blind";
CM_ SG_ 616 ICA_Blind_VIP "This signal is used to indicate the presence of an occlusion of the ICA feature";
CM_ SG_ 616 FCW_Setting_Avail_VIP "FCW setting availability";
CM_ SG_ 616 DDD_FailSts_VIP "DDD Fail Sts CADM2";
CM_ SG_ 616 DDD_DispPopupSts_VIP "DDD Disp Pop Up";
CM_ SG_ 616 BSS_SRV_RQSts_VIP "BSS service warning request";
CM_ SG_ 616 BSS_CFG_STATSts_VIP "Blind Spot configuration status";
CM_ SG_ 616 BSS_Blind_RQSts_VIP "Sensor blinded request from BSS";
CM_ SG_ 616 BlindSpotRightWarn_VIP "BlindSpotRightWarn";
CM_ SG_ 616 BlindSpotLeftWarn_VIP "BlindSpotLeftWarn";
CM_ SG_ 616 AEB_Limited_VIP "AEB_Limited";
CM_ SG_ 616 AEB_Limit_Fail_VIP "AEB_Limit_Fail";
CM_ SG_ 616 AEB_FailSts_VIP "AEB_FailSts";
CM_ SG_ 616 AEB_DispPopupSts_VIP "AEB Dips Pop Up";
CM_ SG_ 616 AEB_Blind_VIP "AEB_Blind";
CM_ SG_ 213 ACCFSafe_D5 "0";
CM_ SG_ 213 AEB_Type_Brk_D5 "AEB type brake signal";
CM_ SG_ 213 DASEngReqPos_D5 "ACC allowed to request engine torque";
CM_ SG_ 213 LKA_LAT_CTRL_ResponseSts_D5 "LKA LAT CTRL Response Sts";
CM_ SG_ 2654486554 CBV_bit0_RepeatMessageRequestBit_1E38401A "Repeat Message Request Bit";
CM_ SG_ 2654486554 CBV_bit3_NMCoordinatorBit_1E38401A "NM Coordinator Sleep Bit";
CM_ SG_ 2654486554 CBV_bit4_ActiveWakeupBit_1E38401A "Active Wakeup Bit";
CM_ SG_ 2654486554 CBV_bit6_PartialNtwInfBit_1E38401A "Partial Network Information Bit (PNI)";
CM_ SG_ 2654486554 SourceNodeIdentifier_1E38401A "Source Node Identifier";
CM_ SG_ 2654486701 CBV_bit0_RepeatMessageRequestBit_1E3840AD "Repeat Message Request Bit";
CM_ SG_ 2654486701 CBV_bit3_NMCoordinatorBit_1E3840AD "NM Coordinator Sleep Bit";
CM_ SG_ 2654486701 CBV_bit4_ActiveWakeupBit_1E3840AD "Active Wakeup Bit";
CM_ SG_ 2654486701 CBV_bit6_PartialNtwInfBit_1E3840AD "Partial Network Information Bit (PNI)";
CM_ SG_ 2654486701 SourceNodeIdentifier_1E3840AD "Source Node Identifier";
CM_ SG_ 2654486689 CBV_bit0_RepeatMessageRequestBit_1E3840A1 "Repeat Message Request Bit";
CM_ SG_ 2654486689 CBV_bit3_NMCoordinatorBit_1E3840A1 "NM Coordinator Sleep Bit";
CM_ SG_ 2654486689 CBV_bit4_ActiveWakeupBit_1E3840A1 "Active Wakeup Bit";
CM_ SG_ 2654486689 CBV_bit6_PartialNtwInfBit_1E3840A1 "Partial Network Information Bit (PNI)";
CM_ SG_ 2654486689 SourceNodeIdentifier_1E3840A1 "Source Node Identifier";
CM_ SG_ 204 Front_Axle_Regen_Capacity "Regenerative Braking front Axle Torque Capability";
CM_ SG_ 263 EVCU2_THA_Resp "EVCU2 speed limiting availability response for trailer hitch assist";
CM_ SG_ 734 Segment_8_Y2 "Line segment 8 end point lateral position";
CM_ SG_ 734 Segment_8_Y1 "Line segment 8 start point lateral position";
CM_ SG_ 734 Segment_8_X2 "Line segment 8 end point longitudinal position";
CM_ SG_ 734 Segment_8_X1 "Line segment 8 start point longitudinal position";
CM_ SG_ 734 Segment_8_ID "ID value of line segment 8";
CM_ SG_ 734 Segment_8_Confidence "Line segment 8 confidence";
CM_ SG_ 734 Segment_7_Y2 "Line segment 7 end point lateral position";
CM_ SG_ 734 Segment_7_Y1 "Line segment 7 start point lateral position";
CM_ SG_ 734 Segment_7_X2 "Line segment 7 end point longitudinal position";
CM_ SG_ 734 Segment_7_X1 "Line segment 7 start point longitudinal position";
CM_ SG_ 734 Segment_7_ID "ID value of line segment 7";
CM_ SG_ 734 Segment_7_Confidence "Line segment 7 confidence";
CM_ SG_ 734 Segment_6_Y2 "Line segment 6 end point lateral position";
CM_ SG_ 734 Segment_6_Y1 "Line segment 6 start point lateral position";
CM_ SG_ 734 Segment_6_X2 "Line segment 6 end point longitudinal position";
CM_ SG_ 734 Segment_6_X1 "Line segment 6 start point longitudinal position";
CM_ SG_ 734 Segment_6_ID "ID value of line segment 6";
CM_ SG_ 734 Segment_6_Confidence "Line segment 6 confidence";
CM_ SG_ 734 Segment_5_Y2 "Line segment 5 end point lateral position";
CM_ SG_ 734 Segment_5_Y1 "Line segment 5 start point lateral position";
CM_ SG_ 734 Segment_5_X2 "Line segment 5 end point longitudinal position";
CM_ SG_ 734 Segment_5_X1 "Line segment 5 start point longitudinal position";
CM_ SG_ 734 Segment_5_ID "ID value of line segment 5";
CM_ SG_ 734 Segment_5_Confidence "Line segment 5 confidence";
CM_ SG_ 734 Segment_4_Y2 "Line segment 4 end point lateral position";
CM_ SG_ 734 Segment_4_Y1 "Line segment 4 start point lateral position";
CM_ SG_ 734 Segment_4_X2 "Line segment 4 end point longitudinal position";
CM_ SG_ 734 Segment_4_X1 "Line segment 4 start point longitudinal position";
CM_ SG_ 734 Segment_4_ID "ID value of line segment 4";
CM_ SG_ 734 Segment_4_Confidence "Line segment 4 confidence";
CM_ SG_ 734 Segment_3_Y2 "Line segment 3 end point lateral position";
CM_ SG_ 734 Segment_3_Y1 "Line segment 3 start point lateral position";
CM_ SG_ 734 Segment_3_X2 "Line segment 3 end point longitudinal position";
CM_ SG_ 734 Segment_3_X1 "Line segment 3 start point longitudinal position";
CM_ SG_ 734 Segment_3_ID "ID value of line segment 3";
CM_ SG_ 734 Segment_3_Confidence "Line segment 3 confidence";
CM_ SG_ 734 Segment_2_Y2 "Line segment 2 end point lateral position";
CM_ SG_ 734 Segment_2_Y1 "Line segment 2 start point lateral position";
CM_ SG_ 734 Segment_2_X2 "Line segment 2 end point longitudinal position";
CM_ SG_ 734 Segment_2_X1 "Line segment 2 start point longitudinal position";
CM_ SG_ 734 Segment_2_ID "ID value of line segment 2";
CM_ SG_ 734 Segment_2_Confidence "Line segment 2 confidence";
CM_ SG_ 734 Segment_1_Y2 "Line segment 1 end point lateral position";
CM_ SG_ 734 Segment_1_Y1 "Line segment 1 start point lateral position";
CM_ SG_ 734 Segment_1_X2 "Line segment 1 end point longitudinal position";
CM_ SG_ 734 Segment_1_X1 "Line segment 1 start point longitudinal position";
CM_ SG_ 734 Segment_1_ID "ID value of line segment 1";
CM_ SG_ 734 Segment_1_Confidence "Line segment 1 confidence";
CM_ SG_ 734 MessageCounter_ADAS_FD_LANES_2 "This signal is a counter used for safety checks strategies. This counter is incremented of 1 (one) unit at each frame transmission.";
CM_ SG_ 734 MAC_ADAS_FD_LANES_2 "-";
CM_ SG_ 734 Frame_Index_Lanes_2 "Frame index number for lanes_2 data";
CM_ SG_ 734 CRC_ADAS_FD_LANES_2 "CRC according to SAE J1850 standard at each frame transmission.";
CM_ SG_ 730 MessageCounter_ADAS_FD_LANES_1 "This signal is a counter used for safety checks strategies. This counter is incremented of 1 (one) unit at each frame transmission.";
CM_ SG_ 730 MAC_ADAS_FD_LANES_1 "-";
CM_ SG_ 730 Line_4_Type "Lane marker 4 type";
CM_ SG_ 730 Line_4_Start_Range "Lane marker 4 start range/view range";
CM_ SG_ 730 Line_4_Offset "Lane marker 4 offset distance";
CM_ SG_ 730 Line_4_Heading "Lane marker 4 heading angle (1st order)";
CM_ SG_ 730 Line_4_End_Range "Lane marker 4 end range/view range";
CM_ SG_ 730 Line_4_Curvature_Rate "Lane marker 4 curvature rate (3rd order)";
CM_ SG_ 730 Line_4_Curvature "Lane marker 4 curvature rate (2nd order)";
CM_ SG_ 730 Line_4_Confidence "Lane marker 4 confidence";
CM_ SG_ 730 Line_3_Type "Lane marker 3 type";
CM_ SG_ 730 Line_3_Start_Range "Lane marker 3 start range/view range";
CM_ SG_ 730 Line_3_Offset "Lane marker 3 offset distance";
CM_ SG_ 730 Line_3_Heading "Lane marker 3 heading angle (1st order)";
CM_ SG_ 730 Line_3_End_Range "Lane marker 3 end range/view range";
CM_ SG_ 730 Line_3_Curvature_Rate "Lane marker 3 curvature rate (3rd order)";
CM_ SG_ 730 Line_3_Curvature "Lane marker 3 curvature rate (2nd order)";
CM_ SG_ 730 Line_3_Confidence "Lane marker 3 confidence";
CM_ SG_ 730 Line_2_Type "Lane marker 2 type";
CM_ SG_ 730 Line_2_Start_Range "Lane marker 2 start range/view range";
CM_ SG_ 730 Line_2_Offset "Lane marker 2 offset distance";
CM_ SG_ 730 Line_2_Heading "Lane marker 2 heading angle (1st order)";
CM_ SG_ 730 Line_2_End_Range "Lane marker 2 end range/view range";
CM_ SG_ 730 Line_2_Curvature_Rate "Lane marker 2 curvature rate (3rd order)";
CM_ SG_ 730 Line_2_Curvature "Lane marker 2 curvature rate (2nd order)";
CM_ SG_ 730 Line_2_Confidence "Lane marker 2 confidence";
CM_ SG_ 730 Line_1_Type "Lane marker 1 type";
CM_ SG_ 730 Line_1_Start_Range "Lane marker 1 start range/view range";
CM_ SG_ 730 Line_1_Offset "Lane marker 1 offset distance";
CM_ SG_ 730 Line_1_Heading "Lane marker 1 heading angle (1st order)";
CM_ SG_ 730 Line_1_End_Range "Lane marker 1 end range/view range";
CM_ SG_ 730 Line_1_Curvature_Rate "Lane marker 1 curvature rate (3rd order)";
CM_ SG_ 730 Line_1_Curvature "Lane marker 1 curvature rate (2nd order)";
CM_ SG_ 730 Line_1_Confidence "Lane marker 1 confidence";
CM_ SG_ 730 Health_Lane_Detection "Health of the Lane Marker Detection system";
CM_ SG_ 730 Health_Front_Object_Detection "Health of the Front Object Detection system";
CM_ SG_ 730 Frame_Index_Lanes_1 "Frame index number for lanes_1 data";
CM_ SG_ 730 FOD_Confidence "Front Object Detection Confidence";
CM_ SG_ 730 CRC_ADAS_FD_LANES_1 "CRC according to SAE J1850 standard at each frame transmission.";
CM_ SG_ 730 Camera_Status "List of which cameras are active";
CM_ SG_ 616 MessageCounter_ADAS_FD_HMI_VIP "This signal is a counter used for safety checks strategies. This counter is incremented of 1 (one) unit at each frame transmission.";
CM_ SG_ 616 CRC_ADAS_FD_HMI_VIP "CRC according to SAE J1850 standard at each frame transmission.";
CM_ SG_ 213 MessageCounter_VIP_INFO_FD "This signal is a counter used for safety checks strategies. This counter is incremented of 1 (one) unit at each frame transmission.";
CM_ SG_ 213 CRC_VIP_INFO_FD "CRC according to SAE J1850 standard at each frame transmission.";
CM_ SG_ 209 MessageCounter_ADAS_FD_INFO_VIP "This signal is a counter used for safety checks strategies. This counter is incremented of 1 (one) unit at each frame transmission.";
CM_ SG_ 209 CRC_ADAS_FD_INFO_VIP "CRC according to SAE J1850 standard at each frame transmission.";
BA_DEF_ SG_ "GenSigTimeoutTime_MPAD" INT 0 65535;
BA_DEF_ SG_ "GenSigTimeoutTime_ADCAM" INT 0 65535;
BA_DEF_ SG_ "GenSigTimeoutTime_CVADAS" INT 0 65535;
BA_DEF_ SG_ "GenSigStartValue" INT 0 2147483647;
BA_DEF_ SG_ "GenSigInactiveValue" INT 0 2147483647;
BA_DEF_ SG_ "GenSigSendType" ENUM "NotUsed","OnWrite","OnWriteWithRepetition","OnChange","OnChangeWithRepetition","IfActive","IfActiveWithRepetition","NoSigSendType";
BA_DEF_ SG_ "SystemSignalLongSymbol" STRING ;
BA_DEF_ SG_ "GenSigTimeoutTime_BSM" INT 0 65535;
BA_DEF_ SG_ "GenSigTimeoutTime_BSM2" INT 0 65535;
BA_DEF_ SG_ "GenSigTimeoutTime_CADM" INT 0 65535;
BA_DEF_ SG_ "GenSigTimeoutTime_CVPAM" INT 0 65535;
BA_DEF_ SG_ "GenSigTimeoutTime_ECM" INT 0 65535;
BA_DEF_ SG_ "GenSigTimeoutTime_EPS" INT 0 65535;
BA_DEF_ SG_ "GenSigTimeoutTime_EVCU2" INT 0 65535;
BA_DEF_ SG_ "GenSigTimeoutTime_ORC" INT 0 65535;
BA_DEF_ BO_ "DiagRequest" ENUM "No","Yes";
BA_DEF_ BO_ "Type" ENUM "P","C","PE","COC","PE_Cntrl","E","E_Cntrl","OC","S","BAF","DC","EM","MM","ISO-TP","-";
BA_DEF_ BO_ "DiagResponse" ENUM "No","Yes";
BA_DEF_ BO_ "NmMessage" ENUM "No","Yes";
BA_DEF_ BO_ "GenMsgSendType" ENUM "Cyclic","NotUsed","NotUsed","NotUsed","NotUsed","NotUsed","NotUsed","NotUsed","NoMsgSendType";
BA_DEF_ BO_ "GenMsgNrOfRepetition" INT 0 255;
BA_DEF_ BO_ "GenMsgILSupport" ENUM "No","Yes";
BA_DEF_ BO_ "GenMsgStartDelayTime" INT 0 65535;
BA_DEF_ BO_ "GenMsgCycleTimeFast" INT 0 65535;
BA_DEF_ BO_ "GenMsgCycleTime" INT 0 65535;
BA_DEF_ BO_ "GenMsgDelayTime" INT 0 65535;
BA_DEF_ BO_ "NmAsrMessage" ENUM "No","Yes";
BA_DEF_ BO_ "DiagState" ENUM "No","Yes";
BA_DEF_ BO_ "DiagConnection" HEX 0 65535;
BA_DEF_ BO_ "VFrameFormat" ENUM "StandardCAN","ExtendedCAN","reserved","reserved","reserved","reserved","reserved","reserved","reserved","reserved","reserved","reserved","reserved","reserved","StandardCAN_FD","ExtendedCAN_FD";
BA_DEF_ BO_ "CANFD_BRS" ENUM "0","1";
BA_DEF_DEF_ "GenSigTimeoutTime_MPAD" 2500;
BA_DEF_DEF_ "GenSigTimeoutTime_ADCAM" 2500;
BA_DEF_DEF_ "GenSigTimeoutTime_CVADAS" 2500;
BA_DEF_DEF_ "GenSigStartValue" 0;
BA_DEF_DEF_ "GenSigInactiveValue" 0;
BA_DEF_DEF_ "GenSigSendType" "NoSigSendType";
BA_DEF_DEF_ "SystemSignalLongSymbol" "";
BA_DEF_DEF_ "GenSigTimeoutTime_BSM" 2500;
BA_DEF_DEF_ "GenSigTimeoutTime_BSM2" 2500;
BA_DEF_DEF_ "GenSigTimeoutTime_CADM" 2500;
BA_DEF_DEF_ "GenSigTimeoutTime_CVPAM" 2500;
BA_DEF_DEF_ "GenSigTimeoutTime_ECM" 2500;
BA_DEF_DEF_ "GenSigTimeoutTime_EPS" 2500;
BA_DEF_DEF_ "GenSigTimeoutTime_EVCU2" 2500;
BA_DEF_DEF_ "GenSigTimeoutTime_ORC" 2500;
BA_DEF_DEF_ "DiagRequest" "No";
BA_DEF_DEF_ "Type" "-";
BA_DEF_DEF_ "DiagResponse" "No";
BA_DEF_DEF_ "NmMessage" "No";
BA_DEF_DEF_ "GenMsgSendType" "NoMsgSendType";
BA_DEF_DEF_ "GenMsgNrOfRepetition" 0;
BA_DEF_DEF_ "GenMsgILSupport" "No";
BA_DEF_DEF_ "GenMsgStartDelayTime" 0;
BA_DEF_DEF_ "GenMsgCycleTimeFast" 0;
BA_DEF_DEF_ "GenMsgCycleTime" 0;
BA_DEF_DEF_ "GenMsgDelayTime" 0;
BA_DEF_DEF_ "NmAsrMessage" "No";
BA_DEF_DEF_ "DiagState" "No";
BA_DEF_DEF_ "DiagConnection" 0;
BA_DEF_DEF_ "VFrameFormat" "StandardCAN_FD";
BA_DEF_DEF_ "CANFD_BRS" "0";
BA_ "Type" BO_ 730 1;
BA_ "GenMsgSendType" BO_ 730 0;
BA_ "GenMsgILSupport" BO_ 730 1;
BA_ "GenMsgCycleTime" BO_ 730 40;
BA_ "CANFD_BRS" BO_ 730 1;
BA_ "Type" BO_ 734 1;
BA_ "GenMsgSendType" BO_ 734 0;
BA_ "GenMsgILSupport" BO_ 734 1;
BA_ "GenMsgCycleTime" BO_ 734 40;
BA_ "CANFD_BRS" BO_ 734 1;
BA_ "Type" BO_ 616 3;
BA_ "GenMsgSendType" BO_ 616 0;
BA_ "GenMsgILSupport" BO_ 616 1;
BA_ "GenMsgCycleTime" BO_ 616 100;
BA_ "GenMsgDelayTime" BO_ 616 20;
BA_ "CANFD_BRS" BO_ 616 1;
BA_ "Type" BO_ 209 1;
BA_ "GenMsgSendType" BO_ 209 0;
BA_ "GenMsgILSupport" BO_ 209 1;
BA_ "GenMsgCycleTime" BO_ 209 10;
BA_ "CANFD_BRS" BO_ 209 1;
BA_ "Type" BO_ 210 1;
BA_ "GenMsgSendType" BO_ 210 0;
BA_ "GenMsgILSupport" BO_ 210 1;
BA_ "GenMsgCycleTime" BO_ 210 10;
BA_ "CANFD_BRS" BO_ 210 1;
BA_ "Type" BO_ 97 8;
BA_ "GenMsgILSupport" BO_ 97 1;
BA_ "CANFD_BRS" BO_ 97 1;
BA_ "Type" BO_ 213 1;
BA_ "GenMsgSendType" BO_ 213 0;
BA_ "GenMsgILSupport" BO_ 213 1;
BA_ "GenMsgCycleTime" BO_ 213 10;
BA_ "CANFD_BRS" BO_ 213 1;
BA_ "Type" BO_ 2654486701 8;
BA_ "NmMessage" BO_ 2654486701 1;
BA_ "NmAsrMessage" BO_ 2654486701 1;
BA_ "VFrameFormat" BO_ 2654486701 15;
BA_ "CANFD_BRS" BO_ 2654486701 1;
BA_ "Type" BO_ 2654486689 8;
BA_ "NmMessage" BO_ 2654486689 1;
BA_ "NmAsrMessage" BO_ 2654486689 1;
BA_ "VFrameFormat" BO_ 2654486689 15;
BA_ "CANFD_BRS" BO_ 2654486689 1;
BA_ "Type" BO_ 204 1;
BA_ "GenMsgSendType" BO_ 204 0;
BA_ "GenMsgILSupport" BO_ 204 1;
BA_ "GenMsgCycleTime" BO_ 204 10;
BA_ "CANFD_BRS" BO_ 204 1;
BA_ "Type" BO_ 2654486554 8;
BA_ "NmMessage" BO_ 2654486554 1;
BA_ "NmAsrMessage" BO_ 2654486554 1;
BA_ "VFrameFormat" BO_ 2654486554 15;
BA_ "CANFD_BRS" BO_ 2654486554 1;
BA_ "Type" BO_ 205 1;
BA_ "GenMsgSendType" BO_ 205 0;
BA_ "GenMsgILSupport" BO_ 205 1;
BA_ "GenMsgCycleTime" BO_ 205 10;
BA_ "CANFD_BRS" BO_ 205 1;
BA_ "Type" BO_ 1580 1;
BA_ "GenMsgSendType" BO_ 1580 0;
BA_ "GenMsgILSupport" BO_ 1580 1;
BA_ "GenMsgCycleTime" BO_ 1580 500;
BA_ "CANFD_BRS" BO_ 1580 1;
BA_ "Type" BO_ 263 1;
BA_ "GenMsgSendType" BO_ 263 0;
BA_ "GenMsgILSupport" BO_ 263 1;
BA_ "GenMsgCycleTime" BO_ 263 10;
BA_ "CANFD_BRS" BO_ 263 1;
BA_ "Type" BO_ 2654486592 8;
BA_ "NmMessage" BO_ 2654486592 1;
BA_ "NmAsrMessage" BO_ 2654486592 1;
BA_ "VFrameFormat" BO_ 2654486592 15;
BA_ "CANFD_BRS" BO_ 2654486592 1;
BA_ "Type" BO_ 292 1;
BA_ "GenMsgSendType" BO_ 292 0;
BA_ "GenMsgILSupport" BO_ 292 1;
BA_ "GenMsgCycleTime" BO_ 292 10;
BA_ "CANFD_BRS" BO_ 292 1;
BA_ "Type" BO_ 299 1;
BA_ "GenMsgSendType" BO_ 299 0;
BA_ "GenMsgILSupport" BO_ 299 1;
BA_ "GenMsgCycleTime" BO_ 299 10;
BA_ "CANFD_BRS" BO_ 299 1;
BA_ "Type" BO_ 1472 3;
BA_ "GenMsgSendType" BO_ 1472 0;
BA_ "GenMsgILSupport" BO_ 1472 1;
BA_ "GenMsgCycleTime" BO_ 1472 1000;
BA_ "GenMsgDelayTime" BO_ 1472 20;
BA_ "CANFD_BRS" BO_ 1472 1;
BA_ "GenSigTimeoutTime_CVADAS" SG_ 730 Line_3_Type 0;
BA_ "GenSigTimeoutTime_BSM" SG_ 730 Line_3_Type 0;
BA_ "GenSigTimeoutTime_BSM2" SG_ 730 Line_3_Type 0;
BA_ "GenSigTimeoutTime_ECM" SG_ 730 Line_3_Type 0;
BA_ "GenSigTimeoutTime_EPS" SG_ 730 Line_3_Type 0;
BA_ "GenSigTimeoutTime_EVCU2" SG_ 730 Line_3_Type 0;
BA_ "GenSigTimeoutTime_ORC" SG_ 730 Line_3_Type 0;
BA_ "GenSigTimeoutTime_CVADAS" SG_ 730 Line_4_Confidence 0;
BA_ "GenSigTimeoutTime_BSM" SG_ 730 Line_4_Confidence 0;
BA_ "GenSigTimeoutTime_BSM2" SG_ 730 Line_4_Confidence 0;
BA_ "GenSigTimeoutTime_ECM" SG_ 730 Line_4_Confidence 0;
BA_ "GenSigTimeoutTime_EPS" SG_ 730 Line_4_Confidence 0;
BA_ "GenSigTimeoutTime_EVCU2" SG_ 730 Line_4_Confidence 0;
BA_ "GenSigTimeoutTime_ORC" SG_ 730 Line_4_Confidence 0;
BA_ "GenSigTimeoutTime_CVADAS" SG_ 730 Line_4_Curvature 0;
BA_ "GenSigTimeoutTime_BSM" SG_ 730 Line_4_Curvature 0;
BA_ "GenSigTimeoutTime_BSM2" SG_ 730 Line_4_Curvature 0;
BA_ "GenSigTimeoutTime_ECM" SG_ 730 Line_4_Curvature 0;
BA_ "GenSigTimeoutTime_EPS" SG_ 730 Line_4_Curvature 0;
BA_ "GenSigTimeoutTime_EVCU2" SG_ 730 Line_4_Curvature 0;
BA_ "GenSigTimeoutTime_ORC" SG_ 730 Line_4_Curvature 0;
BA_ "GenSigTimeoutTime_CVADAS" SG_ 730 Line_4_Curvature_Rate 0;
BA_ "GenSigTimeoutTime_BSM" SG_ 730 Line_4_Curvature_Rate 0;
BA_ "GenSigTimeoutTime_BSM2" SG_ 730 Line_4_Curvature_Rate 0;
BA_ "GenSigTimeoutTime_ECM" SG_ 730 Line_4_Curvature_Rate 0;
BA_ "GenSigTimeoutTime_EPS" SG_ 730 Line_4_Curvature_Rate 0;
BA_ "GenSigTimeoutTime_EVCU2" SG_ 730 Line_4_Curvature_Rate 0;
BA_ "GenSigTimeoutTime_ORC" SG_ 730 Line_4_Curvature_Rate 0;
BA_ "GenSigTimeoutTime_CVADAS" SG_ 730 Line_4_End_Range 0;
BA_ "GenSigTimeoutTime_BSM" SG_ 730 Line_4_End_Range 0;
BA_ "GenSigTimeoutTime_BSM2" SG_ 730 Line_4_End_Range 0;
BA_ "GenSigTimeoutTime_ECM" SG_ 730 Line_4_End_Range 0;
BA_ "GenSigTimeoutTime_EPS" SG_ 730 Line_4_End_Range 0;
BA_ "GenSigTimeoutTime_EVCU2" SG_ 730 Line_4_End_Range 0;
BA_ "GenSigTimeoutTime_ORC" SG_ 730 Line_4_End_Range 0;
BA_ "GenSigTimeoutTime_CVADAS" SG_ 730 Line_4_Heading 0;
BA_ "GenSigTimeoutTime_BSM" SG_ 730 Line_4_Heading 0;
BA_ "GenSigTimeoutTime_BSM2" SG_ 730 Line_4_Heading 0;
BA_ "GenSigTimeoutTime_ECM" SG_ 730 Line_4_Heading 0;
BA_ "GenSigTimeoutTime_EPS" SG_ 730 Line_4_Heading 0;
BA_ "GenSigTimeoutTime_EVCU2" SG_ 730 Line_4_Heading 0;
BA_ "GenSigTimeoutTime_ORC" SG_ 730 Line_4_Heading 0;
BA_ "GenSigTimeoutTime_CVADAS" SG_ 730 Line_3_Curvature 0;
BA_ "GenSigTimeoutTime_BSM" SG_ 730 Line_3_Curvature 0;
BA_ "GenSigTimeoutTime_BSM2" SG_ 730 Line_3_Curvature 0;
BA_ "GenSigTimeoutTime_ECM" SG_ 730 Line_3_Curvature 0;
BA_ "GenSigTimeoutTime_EPS" SG_ 730 Line_3_Curvature 0;
BA_ "GenSigTimeoutTime_EVCU2" SG_ 730 Line_3_Curvature 0;
BA_ "GenSigTimeoutTime_ORC" SG_ 730 Line_3_Curvature 0;
BA_ "GenSigTimeoutTime_CVADAS" SG_ 730 Line_3_Curvature_Rate 0;
BA_ "GenSigTimeoutTime_BSM" SG_ 730 Line_3_Curvature_Rate 0;
BA_ "GenSigTimeoutTime_BSM2" SG_ 730 Line_3_Curvature_Rate 0;
BA_ "GenSigTimeoutTime_ECM" SG_ 730 Line_3_Curvature_Rate 0;
BA_ "GenSigTimeoutTime_EPS" SG_ 730 Line_3_Curvature_Rate 0;
BA_ "GenSigTimeoutTime_EVCU2" SG_ 730 Line_3_Curvature_Rate 0;
BA_ "GenSigTimeoutTime_ORC" SG_ 730 Line_3_Curvature_Rate 0;
BA_ "GenSigTimeoutTime_CVADAS" SG_ 730 Line_3_End_Range 0;
BA_ "GenSigTimeoutTime_BSM" SG_ 730 Line_3_End_Range 0;
BA_ "GenSigTimeoutTime_BSM2" SG_ 730 Line_3_End_Range 0;
BA_ "GenSigTimeoutTime_ECM" SG_ 730 Line_3_End_Range 0;
BA_ "GenSigTimeoutTime_EPS" SG_ 730 Line_3_End_Range 0;
BA_ "GenSigTimeoutTime_EVCU2" SG_ 730 Line_3_End_Range 0;
BA_ "GenSigTimeoutTime_ORC" SG_ 730 Line_3_End_Range 0;
BA_ "GenSigTimeoutTime_CVADAS" SG_ 730 Line_3_Heading 0;
BA_ "GenSigTimeoutTime_BSM" SG_ 730 Line_3_Heading 0;
BA_ "GenSigTimeoutTime_BSM2" SG_ 730 Line_3_Heading 0;
BA_ "GenSigTimeoutTime_ECM" SG_ 730 Line_3_Heading 0;
BA_ "GenSigTimeoutTime_EPS" SG_ 730 Line_3_Heading 0;
BA_ "GenSigTimeoutTime_EVCU2" SG_ 730 Line_3_Heading 0;
BA_ "GenSigTimeoutTime_ORC" SG_ 730 Line_3_Heading 0;
BA_ "GenSigTimeoutTime_CVADAS" SG_ 730 Line_3_Offset 0;
BA_ "GenSigTimeoutTime_BSM" SG_ 730 Line_3_Offset 0;
BA_ "GenSigTimeoutTime_BSM2" SG_ 730 Line_3_Offset 0;
BA_ "GenSigTimeoutTime_ECM" SG_ 730 Line_3_Offset 0;
BA_ "GenSigTimeoutTime_EPS" SG_ 730 Line_3_Offset 0;
BA_ "GenSigTimeoutTime_EVCU2" SG_ 730 Line_3_Offset 0;
BA_ "GenSigTimeoutTime_ORC" SG_ 730 Line_3_Offset 0;
BA_ "GenSigTimeoutTime_CVADAS" SG_ 730 Line_3_Start_Range 0;
BA_ "GenSigTimeoutTime_BSM" SG_ 730 Line_3_Start_Range 0;
BA_ "GenSigTimeoutTime_BSM2" SG_ 730 Line_3_Start_Range 0;
BA_ "GenSigTimeoutTime_ECM" SG_ 730 Line_3_Start_Range 0;
BA_ "GenSigTimeoutTime_EPS" SG_ 730 Line_3_Start_Range 0;
BA_ "GenSigTimeoutTime_EVCU2" SG_ 730 Line_3_Start_Range 0;
BA_ "GenSigTimeoutTime_ORC" SG_ 730 Line_3_Start_Range 0;
BA_ "GenSigTimeoutTime_CVADAS" SG_ 730 Line_2_End_Range 0;
BA_ "GenSigTimeoutTime_BSM" SG_ 730 Line_2_End_Range 0;
BA_ "GenSigTimeoutTime_BSM2" SG_ 730 Line_2_End_Range 0;
BA_ "GenSigTimeoutTime_ECM" SG_ 730 Line_2_End_Range 0;
BA_ "GenSigTimeoutTime_EPS" SG_ 730 Line_2_End_Range 0;
BA_ "GenSigTimeoutTime_EVCU2" SG_ 730 Line_2_End_Range 0;
BA_ "GenSigTimeoutTime_ORC" SG_ 730 Line_2_End_Range 0;
BA_ "GenSigTimeoutTime_CVADAS" SG_ 730 Line_2_Heading 0;
BA_ "GenSigTimeoutTime_BSM" SG_ 730 Line_2_Heading 0;
BA_ "GenSigTimeoutTime_BSM2" SG_ 730 Line_2_Heading 0;
BA_ "GenSigTimeoutTime_ECM" SG_ 730 Line_2_Heading 0;
BA_ "GenSigTimeoutTime_EPS" SG_ 730 Line_2_Heading 0;
BA_ "GenSigTimeoutTime_EVCU2" SG_ 730 Line_2_Heading 0;
BA_ "GenSigTimeoutTime_ORC" SG_ 730 Line_2_Heading 0;
BA_ "GenSigTimeoutTime_CVADAS" SG_ 730 Line_2_Offset 0;
BA_ "GenSigTimeoutTime_BSM" SG_ 730 Line_2_Offset 0;
BA_ "GenSigTimeoutTime_BSM2" SG_ 730 Line_2_Offset 0;
BA_ "GenSigTimeoutTime_ECM" SG_ 730 Line_2_Offset 0;
BA_ "GenSigTimeoutTime_EPS" SG_ 730 Line_2_Offset 0;
BA_ "GenSigTimeoutTime_EVCU2" SG_ 730 Line_2_Offset 0;
BA_ "GenSigTimeoutTime_ORC" SG_ 730 Line_2_Offset 0;
BA_ "GenSigTimeoutTime_CVADAS" SG_ 730 Line_2_Start_Range 0;
BA_ "GenSigTimeoutTime_BSM" SG_ 730 Line_2_Start_Range 0;
BA_ "GenSigTimeoutTime_BSM2" SG_ 730 Line_2_Start_Range 0;
BA_ "GenSigTimeoutTime_ECM" SG_ 730 Line_2_Start_Range 0;
BA_ "GenSigTimeoutTime_EPS" SG_ 730 Line_2_Start_Range 0;
BA_ "GenSigTimeoutTime_EVCU2" SG_ 730 Line_2_Start_Range 0;
BA_ "GenSigTimeoutTime_ORC" SG_ 730 Line_2_Start_Range 0;
BA_ "GenSigTimeoutTime_CVADAS" SG_ 730 Line_2_Type 0;
BA_ "GenSigTimeoutTime_BSM" SG_ 730 Line_2_Type 0;
BA_ "GenSigTimeoutTime_BSM2" SG_ 730 Line_2_Type 0;
BA_ "GenSigTimeoutTime_ECM" SG_ 730 Line_2_Type 0;
BA_ "GenSigTimeoutTime_EPS" SG_ 730 Line_2_Type 0;
BA_ "GenSigTimeoutTime_EVCU2" SG_ 730 Line_2_Type 0;
BA_ "GenSigTimeoutTime_ORC" SG_ 730 Line_2_Type 0;
BA_ "GenSigTimeoutTime_CVADAS" SG_ 730 Line_3_Confidence 0;
BA_ "GenSigTimeoutTime_BSM" SG_ 730 Line_3_Confidence 0;
BA_ "GenSigTimeoutTime_BSM2" SG_ 730 Line_3_Confidence 0;
BA_ "GenSigTimeoutTime_ECM" SG_ 730 Line_3_Confidence 0;
BA_ "GenSigTimeoutTime_EPS" SG_ 730 Line_3_Confidence 0;
BA_ "GenSigTimeoutTime_EVCU2" SG_ 730 Line_3_Confidence 0;
BA_ "GenSigTimeoutTime_ORC" SG_ 730 Line_3_Confidence 0;
BA_ "GenSigTimeoutTime_CVADAS" SG_ 730 Line_1_Offset 0;
BA_ "GenSigTimeoutTime_BSM" SG_ 730 Line_1_Offset 0;
BA_ "GenSigTimeoutTime_BSM2" SG_ 730 Line_1_Offset 0;
BA_ "GenSigTimeoutTime_ECM" SG_ 730 Line_1_Offset 0;
BA_ "GenSigTimeoutTime_EPS" SG_ 730 Line_1_Offset 0;
BA_ "GenSigTimeoutTime_EVCU2" SG_ 730 Line_1_Offset 0;
BA_ "GenSigTimeoutTime_ORC" SG_ 730 Line_1_Offset 0;
BA_ "GenSigTimeoutTime_CVADAS" SG_ 730 Line_1_Start_Range 0;
BA_ "GenSigTimeoutTime_BSM" SG_ 730 Line_1_Start_Range 0;
BA_ "GenSigTimeoutTime_BSM2" SG_ 730 Line_1_Start_Range 0;
BA_ "GenSigTimeoutTime_ECM" SG_ 730 Line_1_Start_Range 0;
BA_ "GenSigTimeoutTime_EPS" SG_ 730 Line_1_Start_Range 0;
BA_ "GenSigTimeoutTime_EVCU2" SG_ 730 Line_1_Start_Range 0;
BA_ "GenSigTimeoutTime_ORC" SG_ 730 Line_1_Start_Range 0;
BA_ "GenSigTimeoutTime_CVADAS" SG_ 730 Line_1_Type 0;
BA_ "GenSigTimeoutTime_BSM" SG_ 730 Line_1_Type 0;
BA_ "GenSigTimeoutTime_BSM2" SG_ 730 Line_1_Type 0;
BA_ "GenSigTimeoutTime_ECM" SG_ 730 Line_1_Type 0;
BA_ "GenSigTimeoutTime_EPS" SG_ 730 Line_1_Type 0;
BA_ "GenSigTimeoutTime_EVCU2" SG_ 730 Line_1_Type 0;
BA_ "GenSigTimeoutTime_ORC" SG_ 730 Line_1_Type 0;
BA_ "GenSigTimeoutTime_CVADAS" SG_ 730 Line_2_Confidence 0;
BA_ "GenSigTimeoutTime_BSM" SG_ 730 Line_2_Confidence 0;
BA_ "GenSigTimeoutTime_BSM2" SG_ 730 Line_2_Confidence 0;
BA_ "GenSigTimeoutTime_ECM" SG_ 730 Line_2_Confidence 0;
BA_ "GenSigTimeoutTime_EPS" SG_ 730 Line_2_Confidence 0;
BA_ "GenSigTimeoutTime_EVCU2" SG_ 730 Line_2_Confidence 0;
BA_ "GenSigTimeoutTime_ORC" SG_ 730 Line_2_Confidence 0;
BA_ "GenSigTimeoutTime_CVADAS" SG_ 730 Line_2_Curvature 0;
BA_ "GenSigTimeoutTime_BSM" SG_ 730 Line_2_Curvature 0;
BA_ "GenSigTimeoutTime_BSM2" SG_ 730 Line_2_Curvature 0;
BA_ "GenSigTimeoutTime_ECM" SG_ 730 Line_2_Curvature 0;
BA_ "GenSigTimeoutTime_EPS" SG_ 730 Line_2_Curvature 0;
BA_ "GenSigTimeoutTime_EVCU2" SG_ 730 Line_2_Curvature 0;
BA_ "GenSigTimeoutTime_ORC" SG_ 730 Line_2_Curvature 0;
BA_ "GenSigTimeoutTime_CVADAS" SG_ 730 Line_2_Curvature_Rate 0;
BA_ "GenSigTimeoutTime_BSM" SG_ 730 Line_2_Curvature_Rate 0;
BA_ "GenSigTimeoutTime_BSM2" SG_ 730 Line_2_Curvature_Rate 0;
BA_ "GenSigTimeoutTime_ECM" SG_ 730 Line_2_Curvature_Rate 0;
BA_ "GenSigTimeoutTime_EPS" SG_ 730 Line_2_Curvature_Rate 0;
BA_ "GenSigTimeoutTime_EVCU2" SG_ 730 Line_2_Curvature_Rate 0;
BA_ "GenSigTimeoutTime_ORC" SG_ 730 Line_2_Curvature_Rate 0;
BA_ "GenSigTimeoutTime_CVADAS" SG_ 730 Health_Lane_Detection 0;
BA_ "GenSigTimeoutTime_BSM" SG_ 730 Health_Lane_Detection 0;
BA_ "GenSigTimeoutTime_BSM2" SG_ 730 Health_Lane_Detection 0;
BA_ "GenSigTimeoutTime_ECM" SG_ 730 Health_Lane_Detection 0;
BA_ "GenSigTimeoutTime_EPS" SG_ 730 Health_Lane_Detection 0;
BA_ "GenSigTimeoutTime_EVCU2" SG_ 730 Health_Lane_Detection 0;
BA_ "GenSigTimeoutTime_ORC" SG_ 730 Health_Lane_Detection 0;
BA_ "GenSigTimeoutTime_CVADAS" SG_ 730 Line_1_Confidence 0;
BA_ "GenSigTimeoutTime_BSM" SG_ 730 Line_1_Confidence 0;
BA_ "GenSigTimeoutTime_BSM2" SG_ 730 Line_1_Confidence 0;
BA_ "GenSigTimeoutTime_ECM" SG_ 730 Line_1_Confidence 0;
BA_ "GenSigTimeoutTime_EPS" SG_ 730 Line_1_Confidence 0;
BA_ "GenSigTimeoutTime_EVCU2" SG_ 730 Line_1_Confidence 0;
BA_ "GenSigTimeoutTime_ORC" SG_ 730 Line_1_Confidence 0;
BA_ "GenSigTimeoutTime_CVADAS" SG_ 730 Line_1_Curvature 0;
BA_ "GenSigTimeoutTime_BSM" SG_ 730 Line_1_Curvature 0;
BA_ "GenSigTimeoutTime_BSM2" SG_ 730 Line_1_Curvature 0;
BA_ "GenSigTimeoutTime_ECM" SG_ 730 Line_1_Curvature 0;
BA_ "GenSigTimeoutTime_EPS" SG_ 730 Line_1_Curvature 0;
BA_ "GenSigTimeoutTime_EVCU2" SG_ 730 Line_1_Curvature 0;
BA_ "GenSigTimeoutTime_ORC" SG_ 730 Line_1_Curvature 0;
BA_ "GenSigTimeoutTime_CVADAS" SG_ 730 Line_1_Curvature_Rate 0;
BA_ "GenSigTimeoutTime_BSM" SG_ 730 Line_1_Curvature_Rate 0;
BA_ "GenSigTimeoutTime_BSM2" SG_ 730 Line_1_Curvature_Rate 0;
BA_ "GenSigTimeoutTime_ECM" SG_ 730 Line_1_Curvature_Rate 0;
BA_ "GenSigTimeoutTime_EPS" SG_ 730 Line_1_Curvature_Rate 0;
BA_ "GenSigTimeoutTime_EVCU2" SG_ 730 Line_1_Curvature_Rate 0;
BA_ "GenSigTimeoutTime_ORC" SG_ 730 Line_1_Curvature_Rate 0;
BA_ "GenSigTimeoutTime_CVADAS" SG_ 730 Line_1_End_Range 0;
BA_ "GenSigTimeoutTime_BSM" SG_ 730 Line_1_End_Range 0;
BA_ "GenSigTimeoutTime_BSM2" SG_ 730 Line_1_End_Range 0;
BA_ "GenSigTimeoutTime_ECM" SG_ 730 Line_1_End_Range 0;
BA_ "GenSigTimeoutTime_EPS" SG_ 730 Line_1_End_Range 0;
BA_ "GenSigTimeoutTime_EVCU2" SG_ 730 Line_1_End_Range 0;
BA_ "GenSigTimeoutTime_ORC" SG_ 730 Line_1_End_Range 0;
BA_ "GenSigTimeoutTime_CVADAS" SG_ 730 Line_1_Heading 0;
BA_ "GenSigTimeoutTime_BSM" SG_ 730 Line_1_Heading 0;
BA_ "GenSigTimeoutTime_BSM2" SG_ 730 Line_1_Heading 0;
BA_ "GenSigTimeoutTime_ECM" SG_ 730 Line_1_Heading 0;
BA_ "GenSigTimeoutTime_EPS" SG_ 730 Line_1_Heading 0;
BA_ "GenSigTimeoutTime_EVCU2" SG_ 730 Line_1_Heading 0;
BA_ "GenSigTimeoutTime_ORC" SG_ 730 Line_1_Heading 0;
BA_ "GenSigTimeoutTime_CVADAS" SG_ 730 Camera_Status 0;
BA_ "GenSigTimeoutTime_BSM" SG_ 730 Camera_Status 0;
BA_ "GenSigTimeoutTime_BSM2" SG_ 730 Camera_Status 0;
BA_ "GenSigTimeoutTime_ECM" SG_ 730 Camera_Status 0;
BA_ "GenSigTimeoutTime_EPS" SG_ 730 Camera_Status 0;
BA_ "GenSigTimeoutTime_EVCU2" SG_ 730 Camera_Status 0;
BA_ "GenSigTimeoutTime_ORC" SG_ 730 Camera_Status 0;
BA_ "GenSigTimeoutTime_CVADAS" SG_ 730 Cntr_ADAS_FD_LANES_1 0;
BA_ "GenSigTimeoutTime_BSM" SG_ 730 Cntr_ADAS_FD_LANES_1 0;
BA_ "GenSigTimeoutTime_BSM2" SG_ 730 Cntr_ADAS_FD_LANES_1 0;
BA_ "GenSigTimeoutTime_ECM" SG_ 730 Cntr_ADAS_FD_LANES_1 0;
BA_ "GenSigTimeoutTime_EPS" SG_ 730 Cntr_ADAS_FD_LANES_1 0;
BA_ "GenSigTimeoutTime_EVCU2" SG_ 730 Cntr_ADAS_FD_LANES_1 0;
BA_ "GenSigTimeoutTime_ORC" SG_ 730 Cntr_ADAS_FD_LANES_1 0;
BA_ "GenSigTimeoutTime_CVADAS" SG_ 730 CRC_ADAS_FD_LANES_1 0;
BA_ "GenSigTimeoutTime_BSM" SG_ 730 CRC_ADAS_FD_LANES_1 0;
BA_ "GenSigTimeoutTime_BSM2" SG_ 730 CRC_ADAS_FD_LANES_1 0;
BA_ "GenSigTimeoutTime_ECM" SG_ 730 CRC_ADAS_FD_LANES_1 0;
BA_ "GenSigTimeoutTime_EPS" SG_ 730 CRC_ADAS_FD_LANES_1 0;
BA_ "GenSigTimeoutTime_EVCU2" SG_ 730 CRC_ADAS_FD_LANES_1 0;
BA_ "GenSigTimeoutTime_ORC" SG_ 730 CRC_ADAS_FD_LANES_1 0;
BA_ "GenSigTimeoutTime_CVADAS" SG_ 730 FOD_Confidence 0;
BA_ "GenSigTimeoutTime_BSM" SG_ 730 FOD_Confidence 0;
BA_ "GenSigTimeoutTime_BSM2" SG_ 730 FOD_Confidence 0;
BA_ "GenSigTimeoutTime_ECM" SG_ 730 FOD_Confidence 0;
BA_ "GenSigTimeoutTime_EPS" SG_ 730 FOD_Confidence 0;
BA_ "GenSigTimeoutTime_EVCU2" SG_ 730 FOD_Confidence 0;
BA_ "GenSigTimeoutTime_ORC" SG_ 730 FOD_Confidence 0;
BA_ "GenSigTimeoutTime_CVADAS" SG_ 730 Frame_Index_Lanes_1 0;
BA_ "GenSigTimeoutTime_BSM" SG_ 730 Frame_Index_Lanes_1 0;
BA_ "GenSigTimeoutTime_BSM2" SG_ 730 Frame_Index_Lanes_1 0;
BA_ "GenSigTimeoutTime_ECM" SG_ 730 Frame_Index_Lanes_1 0;
BA_ "GenSigTimeoutTime_EPS" SG_ 730 Frame_Index_Lanes_1 0;
BA_ "GenSigTimeoutTime_EVCU2" SG_ 730 Frame_Index_Lanes_1 0;
BA_ "GenSigTimeoutTime_ORC" SG_ 730 Frame_Index_Lanes_1 0;
BA_ "GenSigTimeoutTime_CVADAS" SG_ 730 Health_Front_Object_Detection 0;
BA_ "GenSigTimeoutTime_BSM" SG_ 730 Health_Front_Object_Detection 0;
BA_ "GenSigTimeoutTime_BSM2" SG_ 730 Health_Front_Object_Detection 0;
BA_ "GenSigTimeoutTime_ECM" SG_ 730 Health_Front_Object_Detection 0;
BA_ "GenSigTimeoutTime_EPS" SG_ 730 Health_Front_Object_Detection 0;
BA_ "GenSigTimeoutTime_EVCU2" SG_ 730 Health_Front_Object_Detection 0;
BA_ "GenSigTimeoutTime_ORC" SG_ 730 Health_Front_Object_Detection 0;
BA_ "GenSigTimeoutTime_CVADAS" SG_ 730 Line_4_Offset 0;
BA_ "GenSigTimeoutTime_BSM" SG_ 730 Line_4_Offset 0;
BA_ "GenSigTimeoutTime_BSM2" SG_ 730 Line_4_Offset 0;
BA_ "GenSigTimeoutTime_ECM" SG_ 730 Line_4_Offset 0;
BA_ "GenSigTimeoutTime_EPS" SG_ 730 Line_4_Offset 0;
BA_ "GenSigTimeoutTime_EVCU2" SG_ 730 Line_4_Offset 0;
BA_ "GenSigTimeoutTime_ORC" SG_ 730 Line_4_Offset 0;
BA_ "GenSigTimeoutTime_CVADAS" SG_ 730 Line_4_Start_Range 0;
BA_ "GenSigTimeoutTime_BSM" SG_ 730 Line_4_Start_Range 0;
BA_ "GenSigTimeoutTime_BSM2" SG_ 730 Line_4_Start_Range 0;
BA_ "GenSigTimeoutTime_ECM" SG_ 730 Line_4_Start_Range 0;
BA_ "GenSigTimeoutTime_EPS" SG_ 730 Line_4_Start_Range 0;
BA_ "GenSigTimeoutTime_EVCU2" SG_ 730 Line_4_Start_Range 0;
BA_ "GenSigTimeoutTime_ORC" SG_ 730 Line_4_Start_Range 0;
BA_ "GenSigTimeoutTime_CVADAS" SG_ 730 Line_4_Type 0;
BA_ "GenSigTimeoutTime_BSM" SG_ 730 Line_4_Type 0;
BA_ "GenSigTimeoutTime_BSM2" SG_ 730 Line_4_Type 0;
BA_ "GenSigTimeoutTime_ECM" SG_ 730 Line_4_Type 0;
BA_ "GenSigTimeoutTime_EPS" SG_ 730 Line_4_Type 0;
BA_ "GenSigTimeoutTime_EVCU2" SG_ 730 Line_4_Type 0;
BA_ "GenSigTimeoutTime_ORC" SG_ 730 Line_4_Type 0;
BA_ "GenSigTimeoutTime_CVADAS" SG_ 730 MAC_ADAS_FD_LANES_1 0;
BA_ "GenSigTimeoutTime_BSM" SG_ 730 MAC_ADAS_FD_LANES_1 0;
BA_ "GenSigTimeoutTime_BSM2" SG_ 730 MAC_ADAS_FD_LANES_1 0;
BA_ "GenSigTimeoutTime_ECM" SG_ 730 MAC_ADAS_FD_LANES_1 0;
BA_ "GenSigTimeoutTime_EPS" SG_ 730 MAC_ADAS_FD_LANES_1 0;
BA_ "GenSigTimeoutTime_EVCU2" SG_ 730 MAC_ADAS_FD_LANES_1 0;
BA_ "GenSigTimeoutTime_ORC" SG_ 730 MAC_ADAS_FD_LANES_1 0;
BA_ "GenSigTimeoutTime_CVADAS" SG_ 730 MessageCounter_ADAS_FD_LANES_1 0;
BA_ "GenSigTimeoutTime_BSM" SG_ 730 MessageCounter_ADAS_FD_LANES_1 0;
BA_ "GenSigTimeoutTime_BSM2" SG_ 730 MessageCounter_ADAS_FD_LANES_1 0;
BA_ "GenSigTimeoutTime_ECM" SG_ 730 MessageCounter_ADAS_FD_LANES_1 0;
BA_ "GenSigTimeoutTime_EPS" SG_ 730 MessageCounter_ADAS_FD_LANES_1 0;
BA_ "GenSigTimeoutTime_EVCU2" SG_ 730 MessageCounter_ADAS_FD_LANES_1 0;
BA_ "GenSigTimeoutTime_ORC" SG_ 730 MessageCounter_ADAS_FD_LANES_1 0;
BA_ "GenSigTimeoutTime_CVADAS" SG_ 730 Reserved_for_functional_safety_2DA 0;
BA_ "GenSigTimeoutTime_BSM" SG_ 730 Reserved_for_functional_safety_2DA 0;
BA_ "GenSigTimeoutTime_BSM2" SG_ 730 Reserved_for_functional_safety_2DA 0;
BA_ "GenSigTimeoutTime_ECM" SG_ 730 Reserved_for_functional_safety_2DA 0;
BA_ "GenSigTimeoutTime_EPS" SG_ 730 Reserved_for_functional_safety_2DA 0;
BA_ "GenSigTimeoutTime_EVCU2" SG_ 730 Reserved_for_functional_safety_2DA 0;
BA_ "GenSigTimeoutTime_ORC" SG_ 730 Reserved_for_functional_safety_2DA 0;
BA_ "GenSigTimeoutTime_CVADAS" SG_ 734 Segment_7_Confidence 0;
BA_ "GenSigTimeoutTime_BSM" SG_ 734 Segment_7_Confidence 0;
BA_ "GenSigTimeoutTime_BSM2" SG_ 734 Segment_7_Confidence 0;
BA_ "GenSigTimeoutTime_ECM" SG_ 734 Segment_7_Confidence 0;
BA_ "GenSigTimeoutTime_EPS" SG_ 734 Segment_7_Confidence 0;
BA_ "GenSigTimeoutTime_EVCU2" SG_ 734 Segment_7_Confidence 0;
BA_ "GenSigTimeoutTime_ORC" SG_ 734 Segment_7_Confidence 0;
BA_ "GenSigTimeoutTime_CVADAS" SG_ 734 Segment_7_ID 0;
BA_ "GenSigTimeoutTime_BSM" SG_ 734 Segment_7_ID 0;
BA_ "GenSigTimeoutTime_BSM2" SG_ 734 Segment_7_ID 0;
BA_ "GenSigTimeoutTime_ECM" SG_ 734 Segment_7_ID 0;
BA_ "GenSigTimeoutTime_EPS" SG_ 734 Segment_7_ID 0;
BA_ "GenSigTimeoutTime_EVCU2" SG_ 734 Segment_7_ID 0;
BA_ "GenSigTimeoutTime_ORC" SG_ 734 Segment_7_ID 0;
BA_ "GenSigTimeoutTime_CVADAS" SG_ 734 Segment_7_X1 0;
BA_ "GenSigTimeoutTime_BSM" SG_ 734 Segment_7_X1 0;
BA_ "GenSigTimeoutTime_BSM2" SG_ 734 Segment_7_X1 0;
BA_ "GenSigTimeoutTime_ECM" SG_ 734 Segment_7_X1 0;
BA_ "GenSigTimeoutTime_EPS" SG_ 734 Segment_7_X1 0;
BA_ "GenSigTimeoutTime_EVCU2" SG_ 734 Segment_7_X1 0;
BA_ "GenSigTimeoutTime_ORC" SG_ 734 Segment_7_X1 0;
BA_ "GenSigTimeoutTime_CVADAS" SG_ 734 Segment_7_X2 0;
BA_ "GenSigTimeoutTime_BSM" SG_ 734 Segment_7_X2 0;
BA_ "GenSigTimeoutTime_BSM2" SG_ 734 Segment_7_X2 0;
BA_ "GenSigTimeoutTime_ECM" SG_ 734 Segment_7_X2 0;
BA_ "GenSigTimeoutTime_EPS" SG_ 734 Segment_7_X2 0;
BA_ "GenSigTimeoutTime_EVCU2" SG_ 734 Segment_7_X2 0;
BA_ "GenSigTimeoutTime_ORC" SG_ 734 Segment_7_X2 0;
BA_ "GenSigTimeoutTime_CVADAS" SG_ 734 Segment_7_Y1 0;
BA_ "GenSigTimeoutTime_BSM" SG_ 734 Segment_7_Y1 0;
BA_ "GenSigTimeoutTime_BSM2" SG_ 734 Segment_7_Y1 0;
BA_ "GenSigTimeoutTime_ECM" SG_ 734 Segment_7_Y1 0;
BA_ "GenSigTimeoutTime_EPS" SG_ 734 Segment_7_Y1 0;
BA_ "GenSigTimeoutTime_EVCU2" SG_ 734 Segment_7_Y1 0;
BA_ "GenSigTimeoutTime_ORC" SG_ 734 Segment_7_Y1 0;
BA_ "GenSigTimeoutTime_CVADAS" SG_ 734 Segment_7_Y2 0;
BA_ "GenSigTimeoutTime_BSM" SG_ 734 Segment_7_Y2 0;
BA_ "GenSigTimeoutTime_BSM2" SG_ 734 Segment_7_Y2 0;
BA_ "GenSigTimeoutTime_ECM" SG_ 734 Segment_7_Y2 0;
BA_ "GenSigTimeoutTime_EPS" SG_ 734 Segment_7_Y2 0;
BA_ "GenSigTimeoutTime_EVCU2" SG_ 734 Segment_7_Y2 0;
BA_ "GenSigTimeoutTime_ORC" SG_ 734 Segment_7_Y2 0;
BA_ "GenSigTimeoutTime_CVADAS" SG_ 734 Segment_6_Confidence 0;
BA_ "GenSigTimeoutTime_BSM" SG_ 734 Segment_6_Confidence 0;
BA_ "GenSigTimeoutTime_BSM2" SG_ 734 Segment_6_Confidence 0;
BA_ "GenSigTimeoutTime_ECM" SG_ 734 Segment_6_Confidence 0;
BA_ "GenSigTimeoutTime_EPS" SG_ 734 Segment_6_Confidence 0;
BA_ "GenSigTimeoutTime_EVCU2" SG_ 734 Segment_6_Confidence 0;
BA_ "GenSigTimeoutTime_ORC" SG_ 734 Segment_6_Confidence 0;
BA_ "GenSigTimeoutTime_CVADAS" SG_ 734 Segment_6_ID 0;
BA_ "GenSigTimeoutTime_BSM" SG_ 734 Segment_6_ID 0;
BA_ "GenSigTimeoutTime_BSM2" SG_ 734 Segment_6_ID 0;
BA_ "GenSigTimeoutTime_ECM" SG_ 734 Segment_6_ID 0;
BA_ "GenSigTimeoutTime_EPS" SG_ 734 Segment_6_ID 0;
BA_ "GenSigTimeoutTime_EVCU2" SG_ 734 Segment_6_ID 0;
BA_ "GenSigTimeoutTime_ORC" SG_ 734 Segment_6_ID 0;
BA_ "GenSigTimeoutTime_CVADAS" SG_ 734 Segment_6_X1 0;
BA_ "GenSigTimeoutTime_BSM" SG_ 734 Segment_6_X1 0;
BA_ "GenSigTimeoutTime_BSM2" SG_ 734 Segment_6_X1 0;
BA_ "GenSigTimeoutTime_ECM" SG_ 734 Segment_6_X1 0;
BA_ "GenSigTimeoutTime_EPS" SG_ 734 Segment_6_X1 0;
BA_ "GenSigTimeoutTime_EVCU2" SG_ 734 Segment_6_X1 0;
BA_ "GenSigTimeoutTime_ORC" SG_ 734 Segment_6_X1 0;
BA_ "GenSigTimeoutTime_CVADAS" SG_ 734 Segment_6_X2 0;
BA_ "GenSigTimeoutTime_BSM" SG_ 734 Segment_6_X2 0;
BA_ "GenSigTimeoutTime_BSM2" SG_ 734 Segment_6_X2 0;
BA_ "GenSigTimeoutTime_ECM" SG_ 734 Segment_6_X2 0;
BA_ "GenSigTimeoutTime_EPS" SG_ 734 Segment_6_X2 0;
BA_ "GenSigTimeoutTime_EVCU2" SG_ 734 Segment_6_X2 0;
BA_ "GenSigTimeoutTime_ORC" SG_ 734 Segment_6_X2 0;
BA_ "GenSigTimeoutTime_CVADAS" SG_ 734 Segment_6_Y1 0;
BA_ "GenSigTimeoutTime_BSM" SG_ 734 Segment_6_Y1 0;
BA_ "GenSigTimeoutTime_BSM2" SG_ 734 Segment_6_Y1 0;
BA_ "GenSigTimeoutTime_ECM" SG_ 734 Segment_6_Y1 0;
BA_ "GenSigTimeoutTime_EPS" SG_ 734 Segment_6_Y1 0;
BA_ "GenSigTimeoutTime_EVCU2" SG_ 734 Segment_6_Y1 0;
BA_ "GenSigTimeoutTime_ORC" SG_ 734 Segment_6_Y1 0;
BA_ "GenSigTimeoutTime_CVADAS" SG_ 734 Segment_6_Y2 0;
BA_ "GenSigTimeoutTime_BSM" SG_ 734 Segment_6_Y2 0;
BA_ "GenSigTimeoutTime_BSM2" SG_ 734 Segment_6_Y2 0;
BA_ "GenSigTimeoutTime_ECM" SG_ 734 Segment_6_Y2 0;
BA_ "GenSigTimeoutTime_EPS" SG_ 734 Segment_6_Y2 0;
BA_ "GenSigTimeoutTime_EVCU2" SG_ 734 Segment_6_Y2 0;
BA_ "GenSigTimeoutTime_ORC" SG_ 734 Segment_6_Y2 0;
BA_ "GenSigTimeoutTime_CVADAS" SG_ 734 Segment_5_Confidence 0;
BA_ "GenSigTimeoutTime_BSM" SG_ 734 Segment_5_Confidence 0;
BA_ "GenSigTimeoutTime_BSM2" SG_ 734 Segment_5_Confidence 0;
BA_ "GenSigTimeoutTime_ECM" SG_ 734 Segment_5_Confidence 0;
BA_ "GenSigTimeoutTime_EPS" SG_ 734 Segment_5_Confidence 0;
BA_ "GenSigTimeoutTime_EVCU2" SG_ 734 Segment_5_Confidence 0;
BA_ "GenSigTimeoutTime_ORC" SG_ 734 Segment_5_Confidence 0;
BA_ "GenSigTimeoutTime_CVADAS" SG_ 734 Segment_5_ID 0;
BA_ "GenSigTimeoutTime_BSM" SG_ 734 Segment_5_ID 0;
BA_ "GenSigTimeoutTime_BSM2" SG_ 734 Segment_5_ID 0;
BA_ "GenSigTimeoutTime_ECM" SG_ 734 Segment_5_ID 0;
BA_ "GenSigTimeoutTime_EPS" SG_ 734 Segment_5_ID 0;
BA_ "GenSigTimeoutTime_EVCU2" SG_ 734 Segment_5_ID 0;
BA_ "GenSigTimeoutTime_ORC" SG_ 734 Segment_5_ID 0;
BA_ "GenSigTimeoutTime_CVADAS" SG_ 734 Segment_5_X1 0;
BA_ "GenSigTimeoutTime_BSM" SG_ 734 Segment_5_X1 0;
BA_ "GenSigTimeoutTime_BSM2" SG_ 734 Segment_5_X1 0;
BA_ "GenSigTimeoutTime_ECM" SG_ 734 Segment_5_X1 0;
BA_ "GenSigTimeoutTime_EPS" SG_ 734 Segment_5_X1 0;
BA_ "GenSigTimeoutTime_EVCU2" SG_ 734 Segment_5_X1 0;
BA_ "GenSigTimeoutTime_ORC" SG_ 734 Segment_5_X1 0;
BA_ "GenSigTimeoutTime_CVADAS" SG_ 734 Segment_5_X2 0;
BA_ "GenSigTimeoutTime_BSM" SG_ 734 Segment_5_X2 0;
BA_ "GenSigTimeoutTime_BSM2" SG_ 734 Segment_5_X2 0;
BA_ "GenSigTimeoutTime_ECM" SG_ 734 Segment_5_X2 0;
BA_ "GenSigTimeoutTime_EPS" SG_ 734 Segment_5_X2 0;
BA_ "GenSigTimeoutTime_EVCU2" SG_ 734 Segment_5_X2 0;
BA_ "GenSigTimeoutTime_ORC" SG_ 734 Segment_5_X2 0;
BA_ "GenSigTimeoutTime_CVADAS" SG_ 734 Segment_5_Y1 0;
BA_ "GenSigTimeoutTime_BSM" SG_ 734 Segment_5_Y1 0;
BA_ "GenSigTimeoutTime_BSM2" SG_ 734 Segment_5_Y1 0;
BA_ "GenSigTimeoutTime_ECM" SG_ 734 Segment_5_Y1 0;
BA_ "GenSigTimeoutTime_EPS" SG_ 734 Segment_5_Y1 0;
BA_ "GenSigTimeoutTime_EVCU2" SG_ 734 Segment_5_Y1 0;
BA_ "GenSigTimeoutTime_ORC" SG_ 734 Segment_5_Y1 0;
BA_ "GenSigTimeoutTime_CVADAS" SG_ 734 Segment_5_Y2 0;
BA_ "GenSigTimeoutTime_BSM" SG_ 734 Segment_5_Y2 0;
BA_ "GenSigTimeoutTime_BSM2" SG_ 734 Segment_5_Y2 0;
BA_ "GenSigTimeoutTime_ECM" SG_ 734 Segment_5_Y2 0;
BA_ "GenSigTimeoutTime_EPS" SG_ 734 Segment_5_Y2 0;
BA_ "GenSigTimeoutTime_EVCU2" SG_ 734 Segment_5_Y2 0;
BA_ "GenSigTimeoutTime_ORC" SG_ 734 Segment_5_Y2 0;
BA_ "GenSigTimeoutTime_CVADAS" SG_ 734 Segment_4_Confidence 0;
BA_ "GenSigTimeoutTime_BSM" SG_ 734 Segment_4_Confidence 0;
BA_ "GenSigTimeoutTime_BSM2" SG_ 734 Segment_4_Confidence 0;
BA_ "GenSigTimeoutTime_ECM" SG_ 734 Segment_4_Confidence 0;
BA_ "GenSigTimeoutTime_EPS" SG_ 734 Segment_4_Confidence 0;
BA_ "GenSigTimeoutTime_EVCU2" SG_ 734 Segment_4_Confidence 0;
BA_ "GenSigTimeoutTime_ORC" SG_ 734 Segment_4_Confidence 0;
BA_ "GenSigTimeoutTime_CVADAS" SG_ 734 Segment_4_ID 0;
BA_ "GenSigTimeoutTime_BSM" SG_ 734 Segment_4_ID 0;
BA_ "GenSigTimeoutTime_BSM2" SG_ 734 Segment_4_ID 0;
BA_ "GenSigTimeoutTime_ECM" SG_ 734 Segment_4_ID 0;
BA_ "GenSigTimeoutTime_EPS" SG_ 734 Segment_4_ID 0;
BA_ "GenSigTimeoutTime_EVCU2" SG_ 734 Segment_4_ID 0;
BA_ "GenSigTimeoutTime_ORC" SG_ 734 Segment_4_ID 0;
BA_ "GenSigTimeoutTime_CVADAS" SG_ 734 Segment_4_X1 0;
BA_ "GenSigTimeoutTime_BSM" SG_ 734 Segment_4_X1 0;
BA_ "GenSigTimeoutTime_BSM2" SG_ 734 Segment_4_X1 0;
BA_ "GenSigTimeoutTime_ECM" SG_ 734 Segment_4_X1 0;
BA_ "GenSigTimeoutTime_EPS" SG_ 734 Segment_4_X1 0;
BA_ "GenSigTimeoutTime_EVCU2" SG_ 734 Segment_4_X1 0;
BA_ "GenSigTimeoutTime_ORC" SG_ 734 Segment_4_X1 0;
BA_ "GenSigTimeoutTime_CVADAS" SG_ 734 Segment_4_X2 0;
BA_ "GenSigTimeoutTime_BSM" SG_ 734 Segment_4_X2 0;
BA_ "GenSigTimeoutTime_BSM2" SG_ 734 Segment_4_X2 0;
BA_ "GenSigTimeoutTime_ECM" SG_ 734 Segment_4_X2 0;
BA_ "GenSigTimeoutTime_EPS" SG_ 734 Segment_4_X2 0;
BA_ "GenSigTimeoutTime_EVCU2" SG_ 734 Segment_4_X2 0;
BA_ "GenSigTimeoutTime_ORC" SG_ 734 Segment_4_X2 0;
BA_ "GenSigTimeoutTime_CVADAS" SG_ 734 Segment_4_Y1 0;
BA_ "GenSigTimeoutTime_BSM" SG_ 734 Segment_4_Y1 0;
BA_ "GenSigTimeoutTime_BSM2" SG_ 734 Segment_4_Y1 0;
BA_ "GenSigTimeoutTime_ECM" SG_ 734 Segment_4_Y1 0;
BA_ "GenSigTimeoutTime_EPS" SG_ 734 Segment_4_Y1 0;
BA_ "GenSigTimeoutTime_EVCU2" SG_ 734 Segment_4_Y1 0;
BA_ "GenSigTimeoutTime_ORC" SG_ 734 Segment_4_Y1 0;
BA_ "GenSigTimeoutTime_CVADAS" SG_ 734 Segment_4_Y2 0;
BA_ "GenSigTimeoutTime_BSM" SG_ 734 Segment_4_Y2 0;
BA_ "GenSigTimeoutTime_BSM2" SG_ 734 Segment_4_Y2 0;
BA_ "GenSigTimeoutTime_ECM" SG_ 734 Segment_4_Y2 0;
BA_ "GenSigTimeoutTime_EPS" SG_ 734 Segment_4_Y2 0;
BA_ "GenSigTimeoutTime_EVCU2" SG_ 734 Segment_4_Y2 0;
BA_ "GenSigTimeoutTime_ORC" SG_ 734 Segment_4_Y2 0;
BA_ "GenSigTimeoutTime_CVADAS" SG_ 734 Segment_3_Confidence 0;
BA_ "GenSigTimeoutTime_BSM" SG_ 734 Segment_3_Confidence 0;
BA_ "GenSigTimeoutTime_BSM2" SG_ 734 Segment_3_Confidence 0;
BA_ "GenSigTimeoutTime_ECM" SG_ 734 Segment_3_Confidence 0;
BA_ "GenSigTimeoutTime_EPS" SG_ 734 Segment_3_Confidence 0;
BA_ "GenSigTimeoutTime_EVCU2" SG_ 734 Segment_3_Confidence 0;
BA_ "GenSigTimeoutTime_ORC" SG_ 734 Segment_3_Confidence 0;
BA_ "GenSigTimeoutTime_CVADAS" SG_ 734 Segment_3_ID 0;
BA_ "GenSigTimeoutTime_BSM" SG_ 734 Segment_3_ID 0;
BA_ "GenSigTimeoutTime_BSM2" SG_ 734 Segment_3_ID 0;
BA_ "GenSigTimeoutTime_ECM" SG_ 734 Segment_3_ID 0;
BA_ "GenSigTimeoutTime_EPS" SG_ 734 Segment_3_ID 0;
BA_ "GenSigTimeoutTime_EVCU2" SG_ 734 Segment_3_ID 0;
BA_ "GenSigTimeoutTime_ORC" SG_ 734 Segment_3_ID 0;
BA_ "GenSigTimeoutTime_CVADAS" SG_ 734 Segment_3_X1 0;
BA_ "GenSigTimeoutTime_BSM" SG_ 734 Segment_3_X1 0;
BA_ "GenSigTimeoutTime_BSM2" SG_ 734 Segment_3_X1 0;
BA_ "GenSigTimeoutTime_ECM" SG_ 734 Segment_3_X1 0;
BA_ "GenSigTimeoutTime_EPS" SG_ 734 Segment_3_X1 0;
BA_ "GenSigTimeoutTime_EVCU2" SG_ 734 Segment_3_X1 0;
BA_ "GenSigTimeoutTime_ORC" SG_ 734 Segment_3_X1 0;
BA_ "GenSigTimeoutTime_CVADAS" SG_ 734 Segment_3_X2 0;
BA_ "GenSigTimeoutTime_BSM" SG_ 734 Segment_3_X2 0;
BA_ "GenSigTimeoutTime_BSM2" SG_ 734 Segment_3_X2 0;
BA_ "GenSigTimeoutTime_ECM" SG_ 734 Segment_3_X2 0;
BA_ "GenSigTimeoutTime_EPS" SG_ 734 Segment_3_X2 0;
BA_ "GenSigTimeoutTime_EVCU2" SG_ 734 Segment_3_X2 0;
BA_ "GenSigTimeoutTime_ORC" SG_ 734 Segment_3_X2 0;
BA_ "GenSigTimeoutTime_CVADAS" SG_ 734 Segment_3_Y1 0;
BA_ "GenSigTimeoutTime_BSM" SG_ 734 Segment_3_Y1 0;
BA_ "GenSigTimeoutTime_BSM2" SG_ 734 Segment_3_Y1 0;
BA_ "GenSigTimeoutTime_ECM" SG_ 734 Segment_3_Y1 0;
BA_ "GenSigTimeoutTime_EPS" SG_ 734 Segment_3_Y1 0;
BA_ "GenSigTimeoutTime_EVCU2" SG_ 734 Segment_3_Y1 0;
BA_ "GenSigTimeoutTime_ORC" SG_ 734 Segment_3_Y1 0;
BA_ "GenSigTimeoutTime_CVADAS" SG_ 734 Segment_3_Y2 0;
BA_ "GenSigTimeoutTime_BSM" SG_ 734 Segment_3_Y2 0;
BA_ "GenSigTimeoutTime_BSM2" SG_ 734 Segment_3_Y2 0;
BA_ "GenSigTimeoutTime_ECM" SG_ 734 Segment_3_Y2 0;
BA_ "GenSigTimeoutTime_EPS" SG_ 734 Segment_3_Y2 0;
BA_ "GenSigTimeoutTime_EVCU2" SG_ 734 Segment_3_Y2 0;
BA_ "GenSigTimeoutTime_ORC" SG_ 734 Segment_3_Y2 0;
BA_ "GenSigTimeoutTime_CVADAS" SG_ 734 Segment_2_Confidence 0;
BA_ "GenSigTimeoutTime_BSM" SG_ 734 Segment_2_Confidence 0;
BA_ "GenSigTimeoutTime_BSM2" SG_ 734 Segment_2_Confidence 0;
BA_ "GenSigTimeoutTime_ECM" SG_ 734 Segment_2_Confidence 0;
BA_ "GenSigTimeoutTime_EPS" SG_ 734 Segment_2_Confidence 0;
BA_ "GenSigTimeoutTime_EVCU2" SG_ 734 Segment_2_Confidence 0;
BA_ "GenSigTimeoutTime_ORC" SG_ 734 Segment_2_Confidence 0;
BA_ "GenSigTimeoutTime_CVADAS" SG_ 734 Segment_2_ID 0;
BA_ "GenSigTimeoutTime_BSM" SG_ 734 Segment_2_ID 0;
BA_ "GenSigTimeoutTime_BSM2" SG_ 734 Segment_2_ID 0;
BA_ "GenSigTimeoutTime_ECM" SG_ 734 Segment_2_ID 0;
BA_ "GenSigTimeoutTime_EPS" SG_ 734 Segment_2_ID 0;
BA_ "GenSigTimeoutTime_EVCU2" SG_ 734 Segment_2_ID 0;
BA_ "GenSigTimeoutTime_ORC" SG_ 734 Segment_2_ID 0;
BA_ "GenSigTimeoutTime_CVADAS" SG_ 734 Segment_2_X1 0;
BA_ "GenSigTimeoutTime_BSM" SG_ 734 Segment_2_X1 0;
BA_ "GenSigTimeoutTime_BSM2" SG_ 734 Segment_2_X1 0;
BA_ "GenSigTimeoutTime_ECM" SG_ 734 Segment_2_X1 0;
BA_ "GenSigTimeoutTime_EPS" SG_ 734 Segment_2_X1 0;
BA_ "GenSigTimeoutTime_EVCU2" SG_ 734 Segment_2_X1 0;
BA_ "GenSigTimeoutTime_ORC" SG_ 734 Segment_2_X1 0;
BA_ "GenSigTimeoutTime_CVADAS" SG_ 734 Segment_2_X2 0;
BA_ "GenSigTimeoutTime_BSM" SG_ 734 Segment_2_X2 0;
BA_ "GenSigTimeoutTime_BSM2" SG_ 734 Segment_2_X2 0;
BA_ "GenSigTimeoutTime_ECM" SG_ 734 Segment_2_X2 0;
BA_ "GenSigTimeoutTime_EPS" SG_ 734 Segment_2_X2 0;
BA_ "GenSigTimeoutTime_EVCU2" SG_ 734 Segment_2_X2 0;
BA_ "GenSigTimeoutTime_ORC" SG_ 734 Segment_2_X2 0;
BA_ "GenSigTimeoutTime_CVADAS" SG_ 734 Segment_2_Y1 0;
BA_ "GenSigTimeoutTime_BSM" SG_ 734 Segment_2_Y1 0;
BA_ "GenSigTimeoutTime_BSM2" SG_ 734 Segment_2_Y1 0;
BA_ "GenSigTimeoutTime_ECM" SG_ 734 Segment_2_Y1 0;
BA_ "GenSigTimeoutTime_EPS" SG_ 734 Segment_2_Y1 0;
BA_ "GenSigTimeoutTime_EVCU2" SG_ 734 Segment_2_Y1 0;
BA_ "GenSigTimeoutTime_ORC" SG_ 734 Segment_2_Y1 0;
BA_ "GenSigTimeoutTime_CVADAS" SG_ 734 Segment_2_Y2 0;
BA_ "GenSigTimeoutTime_BSM" SG_ 734 Segment_2_Y2 0;
BA_ "GenSigTimeoutTime_BSM2" SG_ 734 Segment_2_Y2 0;
BA_ "GenSigTimeoutTime_ECM" SG_ 734 Segment_2_Y2 0;
BA_ "GenSigTimeoutTime_EPS" SG_ 734 Segment_2_Y2 0;
BA_ "GenSigTimeoutTime_EVCU2" SG_ 734 Segment_2_Y2 0;
BA_ "GenSigTimeoutTime_ORC" SG_ 734 Segment_2_Y2 0;
BA_ "GenSigTimeoutTime_CVADAS" SG_ 734 Segment_1_Confidence 0;
BA_ "GenSigTimeoutTime_BSM" SG_ 734 Segment_1_Confidence 0;
BA_ "GenSigTimeoutTime_BSM2" SG_ 734 Segment_1_Confidence 0;
BA_ "GenSigTimeoutTime_ECM" SG_ 734 Segment_1_Confidence 0;
BA_ "GenSigTimeoutTime_EPS" SG_ 734 Segment_1_Confidence 0;
BA_ "GenSigTimeoutTime_EVCU2" SG_ 734 Segment_1_Confidence 0;
BA_ "GenSigTimeoutTime_ORC" SG_ 734 Segment_1_Confidence 0;
BA_ "GenSigTimeoutTime_CVADAS" SG_ 734 Segment_1_ID 0;
BA_ "GenSigTimeoutTime_BSM" SG_ 734 Segment_1_ID 0;
BA_ "GenSigTimeoutTime_BSM2" SG_ 734 Segment_1_ID 0;
BA_ "GenSigTimeoutTime_ECM" SG_ 734 Segment_1_ID 0;
BA_ "GenSigTimeoutTime_EPS" SG_ 734 Segment_1_ID 0;
BA_ "GenSigTimeoutTime_EVCU2" SG_ 734 Segment_1_ID 0;
BA_ "GenSigTimeoutTime_ORC" SG_ 734 Segment_1_ID 0;
BA_ "GenSigTimeoutTime_CVADAS" SG_ 734 Segment_1_X1 0;
BA_ "GenSigTimeoutTime_BSM" SG_ 734 Segment_1_X1 0;
BA_ "GenSigTimeoutTime_BSM2" SG_ 734 Segment_1_X1 0;
BA_ "GenSigTimeoutTime_ECM" SG_ 734 Segment_1_X1 0;
BA_ "GenSigTimeoutTime_EPS" SG_ 734 Segment_1_X1 0;
BA_ "GenSigTimeoutTime_EVCU2" SG_ 734 Segment_1_X1 0;
BA_ "GenSigTimeoutTime_ORC" SG_ 734 Segment_1_X1 0;
BA_ "GenSigTimeoutTime_CVADAS" SG_ 734 Segment_1_X2 0;
BA_ "GenSigTimeoutTime_BSM" SG_ 734 Segment_1_X2 0;
BA_ "GenSigTimeoutTime_BSM2" SG_ 734 Segment_1_X2 0;
BA_ "GenSigTimeoutTime_ECM" SG_ 734 Segment_1_X2 0;
BA_ "GenSigTimeoutTime_EPS" SG_ 734 Segment_1_X2 0;
BA_ "GenSigTimeoutTime_EVCU2" SG_ 734 Segment_1_X2 0;
BA_ "GenSigTimeoutTime_ORC" SG_ 734 Segment_1_X2 0;
BA_ "GenSigTimeoutTime_CVADAS" SG_ 734 Segment_1_Y1 0;
BA_ "GenSigTimeoutTime_BSM" SG_ 734 Segment_1_Y1 0;
BA_ "GenSigTimeoutTime_BSM2" SG_ 734 Segment_1_Y1 0;
BA_ "GenSigTimeoutTime_ECM" SG_ 734 Segment_1_Y1 0;
BA_ "GenSigTimeoutTime_EPS" SG_ 734 Segment_1_Y1 0;
BA_ "GenSigTimeoutTime_EVCU2" SG_ 734 Segment_1_Y1 0;
BA_ "GenSigTimeoutTime_ORC" SG_ 734 Segment_1_Y1 0;
BA_ "GenSigTimeoutTime_CVADAS" SG_ 734 Segment_1_Y2 0;
BA_ "GenSigTimeoutTime_BSM" SG_ 734 Segment_1_Y2 0;
BA_ "GenSigTimeoutTime_BSM2" SG_ 734 Segment_1_Y2 0;
BA_ "GenSigTimeoutTime_ECM" SG_ 734 Segment_1_Y2 0;
BA_ "GenSigTimeoutTime_EPS" SG_ 734 Segment_1_Y2 0;
BA_ "GenSigTimeoutTime_EVCU2" SG_ 734 Segment_1_Y2 0;
BA_ "GenSigTimeoutTime_ORC" SG_ 734 Segment_1_Y2 0;
BA_ "GenSigTimeoutTime_CVADAS" SG_ 734 Cntr_ADAS_FD_LANES_2 0;
BA_ "GenSigTimeoutTime_BSM" SG_ 734 Cntr_ADAS_FD_LANES_2 0;
BA_ "GenSigTimeoutTime_BSM2" SG_ 734 Cntr_ADAS_FD_LANES_2 0;
BA_ "GenSigTimeoutTime_ECM" SG_ 734 Cntr_ADAS_FD_LANES_2 0;
BA_ "GenSigTimeoutTime_EPS" SG_ 734 Cntr_ADAS_FD_LANES_2 0;
BA_ "GenSigTimeoutTime_EVCU2" SG_ 734 Cntr_ADAS_FD_LANES_2 0;
BA_ "GenSigTimeoutTime_ORC" SG_ 734 Cntr_ADAS_FD_LANES_2 0;
BA_ "GenSigTimeoutTime_CVADAS" SG_ 734 CRC_ADAS_FD_LANES_2 0;
BA_ "GenSigTimeoutTime_BSM" SG_ 734 CRC_ADAS_FD_LANES_2 0;
BA_ "GenSigTimeoutTime_BSM2" SG_ 734 CRC_ADAS_FD_LANES_2 0;
BA_ "GenSigTimeoutTime_ECM" SG_ 734 CRC_ADAS_FD_LANES_2 0;
BA_ "GenSigTimeoutTime_EPS" SG_ 734 CRC_ADAS_FD_LANES_2 0;
BA_ "GenSigTimeoutTime_EVCU2" SG_ 734 CRC_ADAS_FD_LANES_2 0;
BA_ "GenSigTimeoutTime_ORC" SG_ 734 CRC_ADAS_FD_LANES_2 0;
BA_ "GenSigTimeoutTime_CVADAS" SG_ 734 Frame_Index_Lanes_2 0;
BA_ "GenSigTimeoutTime_BSM" SG_ 734 Frame_Index_Lanes_2 0;
BA_ "GenSigTimeoutTime_BSM2" SG_ 734 Frame_Index_Lanes_2 0;
BA_ "GenSigTimeoutTime_ECM" SG_ 734 Frame_Index_Lanes_2 0;
BA_ "GenSigTimeoutTime_EPS" SG_ 734 Frame_Index_Lanes_2 0;
BA_ "GenSigTimeoutTime_EVCU2" SG_ 734 Frame_Index_Lanes_2 0;
BA_ "GenSigTimeoutTime_ORC" SG_ 734 Frame_Index_Lanes_2 0;
BA_ "GenSigTimeoutTime_CVADAS" SG_ 734 MAC_ADAS_FD_LANES_2 0;
BA_ "GenSigTimeoutTime_BSM" SG_ 734 MAC_ADAS_FD_LANES_2 0;
BA_ "GenSigTimeoutTime_BSM2" SG_ 734 MAC_ADAS_FD_LANES_2 0;
BA_ "GenSigTimeoutTime_ECM" SG_ 734 MAC_ADAS_FD_LANES_2 0;
BA_ "GenSigTimeoutTime_EPS" SG_ 734 MAC_ADAS_FD_LANES_2 0;
BA_ "GenSigTimeoutTime_EVCU2" SG_ 734 MAC_ADAS_FD_LANES_2 0;
BA_ "GenSigTimeoutTime_ORC" SG_ 734 MAC_ADAS_FD_LANES_2 0;
BA_ "GenSigTimeoutTime_CVADAS" SG_ 734 MessageCounter_ADAS_FD_LANES_2 0;
BA_ "GenSigTimeoutTime_BSM" SG_ 734 MessageCounter_ADAS_FD_LANES_2 0;
BA_ "GenSigTimeoutTime_BSM2" SG_ 734 MessageCounter_ADAS_FD_LANES_2 0;
BA_ "GenSigTimeoutTime_ECM" SG_ 734 MessageCounter_ADAS_FD_LANES_2 0;
BA_ "GenSigTimeoutTime_EPS" SG_ 734 MessageCounter_ADAS_FD_LANES_2 0;
BA_ "GenSigTimeoutTime_EVCU2" SG_ 734 MessageCounter_ADAS_FD_LANES_2 0;
BA_ "GenSigTimeoutTime_ORC" SG_ 734 MessageCounter_ADAS_FD_LANES_2 0;
BA_ "GenSigTimeoutTime_CVADAS" SG_ 734 Reserved_for_functional_safety_2DE 0;
BA_ "GenSigTimeoutTime_BSM" SG_ 734 Reserved_for_functional_safety_2DE 0;
BA_ "GenSigTimeoutTime_BSM2" SG_ 734 Reserved_for_functional_safety_2DE 0;
BA_ "GenSigTimeoutTime_ECM" SG_ 734 Reserved_for_functional_safety_2DE 0;
BA_ "GenSigTimeoutTime_EPS" SG_ 734 Reserved_for_functional_safety_2DE 0;
BA_ "GenSigTimeoutTime_EVCU2" SG_ 734 Reserved_for_functional_safety_2DE 0;
BA_ "GenSigTimeoutTime_ORC" SG_ 734 Reserved_for_functional_safety_2DE 0;
BA_ "GenSigTimeoutTime_CVADAS" SG_ 734 Segment_8_Confidence 0;
BA_ "GenSigTimeoutTime_BSM" SG_ 734 Segment_8_Confidence 0;
BA_ "GenSigTimeoutTime_BSM2" SG_ 734 Segment_8_Confidence 0;
BA_ "GenSigTimeoutTime_ECM" SG_ 734 Segment_8_Confidence 0;
BA_ "GenSigTimeoutTime_EPS" SG_ 734 Segment_8_Confidence 0;
BA_ "GenSigTimeoutTime_EVCU2" SG_ 734 Segment_8_Confidence 0;
BA_ "GenSigTimeoutTime_ORC" SG_ 734 Segment_8_Confidence 0;
BA_ "GenSigTimeoutTime_CVADAS" SG_ 734 Segment_8_ID 0;
BA_ "GenSigTimeoutTime_BSM" SG_ 734 Segment_8_ID 0;
BA_ "GenSigTimeoutTime_BSM2" SG_ 734 Segment_8_ID 0;
BA_ "GenSigTimeoutTime_ECM" SG_ 734 Segment_8_ID 0;
BA_ "GenSigTimeoutTime_EPS" SG_ 734 Segment_8_ID 0;
BA_ "GenSigTimeoutTime_EVCU2" SG_ 734 Segment_8_ID 0;
BA_ "GenSigTimeoutTime_ORC" SG_ 734 Segment_8_ID 0;
BA_ "GenSigTimeoutTime_CVADAS" SG_ 734 Segment_8_X1 0;
BA_ "GenSigTimeoutTime_BSM" SG_ 734 Segment_8_X1 0;
BA_ "GenSigTimeoutTime_BSM2" SG_ 734 Segment_8_X1 0;
BA_ "GenSigTimeoutTime_ECM" SG_ 734 Segment_8_X1 0;
BA_ "GenSigTimeoutTime_EPS" SG_ 734 Segment_8_X1 0;
BA_ "GenSigTimeoutTime_EVCU2" SG_ 734 Segment_8_X1 0;
BA_ "GenSigTimeoutTime_ORC" SG_ 734 Segment_8_X1 0;
BA_ "GenSigTimeoutTime_CVADAS" SG_ 734 Segment_8_X2 0;
BA_ "GenSigTimeoutTime_BSM" SG_ 734 Segment_8_X2 0;
BA_ "GenSigTimeoutTime_BSM2" SG_ 734 Segment_8_X2 0;
BA_ "GenSigTimeoutTime_ECM" SG_ 734 Segment_8_X2 0;
BA_ "GenSigTimeoutTime_EPS" SG_ 734 Segment_8_X2 0;
BA_ "GenSigTimeoutTime_EVCU2" SG_ 734 Segment_8_X2 0;
BA_ "GenSigTimeoutTime_ORC" SG_ 734 Segment_8_X2 0;
BA_ "GenSigTimeoutTime_CVADAS" SG_ 734 Segment_8_Y1 0;
BA_ "GenSigTimeoutTime_BSM" SG_ 734 Segment_8_Y1 0;
BA_ "GenSigTimeoutTime_BSM2" SG_ 734 Segment_8_Y1 0;
BA_ "GenSigTimeoutTime_ECM" SG_ 734 Segment_8_Y1 0;
BA_ "GenSigTimeoutTime_EPS" SG_ 734 Segment_8_Y1 0;
BA_ "GenSigTimeoutTime_EVCU2" SG_ 734 Segment_8_Y1 0;
BA_ "GenSigTimeoutTime_ORC" SG_ 734 Segment_8_Y1 0;
BA_ "GenSigTimeoutTime_CVADAS" SG_ 734 Segment_8_Y2 0;
BA_ "GenSigTimeoutTime_BSM" SG_ 734 Segment_8_Y2 0;
BA_ "GenSigTimeoutTime_BSM2" SG_ 734 Segment_8_Y2 0;
BA_ "GenSigTimeoutTime_ECM" SG_ 734 Segment_8_Y2 0;
BA_ "GenSigTimeoutTime_EPS" SG_ 734 Segment_8_Y2 0;
BA_ "GenSigTimeoutTime_EVCU2" SG_ 734 Segment_8_Y2 0;
BA_ "GenSigTimeoutTime_ORC" SG_ 734 Segment_8_Y2 0;
BA_ "GenSigTimeoutTime_ADCAM" SG_ 616 BSS_TrailerSts_VIP 0;
BA_ "GenSigTimeoutTime_CVADAS" SG_ 616 BSS_TrailerSts_VIP 0;
BA_ "GenSigSendType" SG_ 616 BSS_TrailerSts_VIP 3;
BA_ "GenSigTimeoutTime_BSM" SG_ 616 BSS_TrailerSts_VIP 0;
BA_ "GenSigTimeoutTime_BSM2" SG_ 616 BSS_TrailerSts_VIP 0;
BA_ "GenSigTimeoutTime_EPS" SG_ 616 BSS_TrailerSts_VIP 0;
BA_ "GenSigTimeoutTime_EVCU2" SG_ 616 BSS_TrailerSts_VIP 0;
BA_ "GenSigTimeoutTime_ORC" SG_ 616 BSS_TrailerSts_VIP 0;
BA_ "GenSigTimeoutTime_ADCAM" SG_ 616 DDD_DispPopupSts_VIP 0;
BA_ "GenSigTimeoutTime_CVADAS" SG_ 616 DDD_DispPopupSts_VIP 0;
BA_ "GenSigSendType" SG_ 616 DDD_DispPopupSts_VIP 3;
BA_ "GenSigTimeoutTime_BSM" SG_ 616 DDD_DispPopupSts_VIP 0;
BA_ "GenSigTimeoutTime_BSM2" SG_ 616 DDD_DispPopupSts_VIP 0;
BA_ "GenSigTimeoutTime_EPS" SG_ 616 DDD_DispPopupSts_VIP 0;
BA_ "GenSigTimeoutTime_EVCU2" SG_ 616 DDD_DispPopupSts_VIP 0;
BA_ "GenSigTimeoutTime_ORC" SG_ 616 DDD_DispPopupSts_VIP 0;
BA_ "GenSigTimeoutTime_ADCAM" SG_ 616 DDD_FailSts_VIP 0;
BA_ "GenSigTimeoutTime_CVADAS" SG_ 616 DDD_FailSts_VIP 0;
BA_ "GenSigSendType" SG_ 616 DDD_FailSts_VIP 3;
BA_ "GenSigTimeoutTime_BSM" SG_ 616 DDD_FailSts_VIP 0;
BA_ "GenSigTimeoutTime_BSM2" SG_ 616 DDD_FailSts_VIP 0;
BA_ "GenSigTimeoutTime_EPS" SG_ 616 DDD_FailSts_VIP 0;
BA_ "GenSigTimeoutTime_EVCU2" SG_ 616 DDD_FailSts_VIP 0;
BA_ "GenSigTimeoutTime_ORC" SG_ 616 DDD_FailSts_VIP 0;
BA_ "GenSigTimeoutTime_ADCAM" SG_ 616 FCW_Setting_Avail_VIP 0;
BA_ "GenSigTimeoutTime_CVADAS" SG_ 616 FCW_Setting_Avail_VIP 0;
BA_ "GenSigSendType" SG_ 616 FCW_Setting_Avail_VIP 3;
BA_ "GenSigTimeoutTime_BSM" SG_ 616 FCW_Setting_Avail_VIP 0;
BA_ "GenSigTimeoutTime_BSM2" SG_ 616 FCW_Setting_Avail_VIP 0;
BA_ "GenSigTimeoutTime_EPS" SG_ 616 FCW_Setting_Avail_VIP 0;
BA_ "GenSigTimeoutTime_EVCU2" SG_ 616 FCW_Setting_Avail_VIP 0;
BA_ "GenSigTimeoutTime_ORC" SG_ 616 FCW_Setting_Avail_VIP 0;
BA_ "GenSigTimeoutTime_ADCAM" SG_ 616 ICA_Blind_VIP 0;
BA_ "GenSigTimeoutTime_CVADAS" SG_ 616 ICA_Blind_VIP 0;
BA_ "GenSigSendType" SG_ 616 ICA_Blind_VIP 3;
BA_ "GenSigTimeoutTime_BSM" SG_ 616 ICA_Blind_VIP 0;
BA_ "GenSigTimeoutTime_BSM2" SG_ 616 ICA_Blind_VIP 0;
BA_ "GenSigTimeoutTime_EPS" SG_ 616 ICA_Blind_VIP 0;
BA_ "GenSigTimeoutTime_EVCU2" SG_ 616 ICA_Blind_VIP 0;
BA_ "GenSigTimeoutTime_ORC" SG_ 616 ICA_Blind_VIP 0;
BA_ "GenSigTimeoutTime_ADCAM" SG_ 616 LKA_Blind_VIP 0;
BA_ "GenSigTimeoutTime_CVADAS" SG_ 616 LKA_Blind_VIP 0;
BA_ "GenSigSendType" SG_ 616 LKA_Blind_VIP 3;
BA_ "GenSigTimeoutTime_BSM" SG_ 616 LKA_Blind_VIP 0;
BA_ "GenSigTimeoutTime_BSM2" SG_ 616 LKA_Blind_VIP 0;
BA_ "GenSigTimeoutTime_EPS" SG_ 616 LKA_Blind_VIP 0;
BA_ "GenSigTimeoutTime_EVCU2" SG_ 616 LKA_Blind_VIP 0;
BA_ "GenSigTimeoutTime_ORC" SG_ 616 LKA_Blind_VIP 0;
BA_ "GenSigTimeoutTime_ADCAM" SG_ 616 BlindSpotLeftWarn_VIP 0;
BA_ "GenSigTimeoutTime_CVADAS" SG_ 616 BlindSpotLeftWarn_VIP 0;
BA_ "GenSigSendType" SG_ 616 BlindSpotLeftWarn_VIP 3;
BA_ "GenSigTimeoutTime_BSM" SG_ 616 BlindSpotLeftWarn_VIP 0;
BA_ "GenSigTimeoutTime_BSM2" SG_ 616 BlindSpotLeftWarn_VIP 0;
BA_ "GenSigTimeoutTime_EPS" SG_ 616 BlindSpotLeftWarn_VIP 0;
BA_ "GenSigTimeoutTime_EVCU2" SG_ 616 BlindSpotLeftWarn_VIP 0;
BA_ "GenSigTimeoutTime_ORC" SG_ 616 BlindSpotLeftWarn_VIP 0;
BA_ "GenSigTimeoutTime_ADCAM" SG_ 616 BlindSpotRightWarn_VIP 0;
BA_ "GenSigTimeoutTime_CVADAS" SG_ 616 BlindSpotRightWarn_VIP 0;
BA_ "GenSigSendType" SG_ 616 BlindSpotRightWarn_VIP 3;
BA_ "GenSigTimeoutTime_BSM" SG_ 616 BlindSpotRightWarn_VIP 0;
BA_ "GenSigTimeoutTime_BSM2" SG_ 616 BlindSpotRightWarn_VIP 0;
BA_ "GenSigTimeoutTime_EPS" SG_ 616 BlindSpotRightWarn_VIP 0;
BA_ "GenSigTimeoutTime_EVCU2" SG_ 616 BlindSpotRightWarn_VIP 0;
BA_ "GenSigTimeoutTime_ORC" SG_ 616 BlindSpotRightWarn_VIP 0;
BA_ "GenSigTimeoutTime_ADCAM" SG_ 616 BSS_Blind_RQSts_VIP 0;
BA_ "GenSigTimeoutTime_CVADAS" SG_ 616 BSS_Blind_RQSts_VIP 0;
BA_ "GenSigSendType" SG_ 616 BSS_Blind_RQSts_VIP 3;
BA_ "GenSigTimeoutTime_BSM" SG_ 616 BSS_Blind_RQSts_VIP 0;
BA_ "GenSigTimeoutTime_BSM2" SG_ 616 BSS_Blind_RQSts_VIP 0;
BA_ "GenSigTimeoutTime_EPS" SG_ 616 BSS_Blind_RQSts_VIP 0;
BA_ "GenSigTimeoutTime_EVCU2" SG_ 616 BSS_Blind_RQSts_VIP 0;
BA_ "GenSigTimeoutTime_ORC" SG_ 616 BSS_Blind_RQSts_VIP 0;
BA_ "GenSigTimeoutTime_ADCAM" SG_ 616 BSS_CFG_STATSts_VIP 0;
BA_ "GenSigTimeoutTime_CVADAS" SG_ 616 BSS_CFG_STATSts_VIP 0;
BA_ "GenSigSendType" SG_ 616 BSS_CFG_STATSts_VIP 3;
BA_ "GenSigTimeoutTime_BSM" SG_ 616 BSS_CFG_STATSts_VIP 0;
BA_ "GenSigTimeoutTime_BSM2" SG_ 616 BSS_CFG_STATSts_VIP 0;
BA_ "GenSigTimeoutTime_EPS" SG_ 616 BSS_CFG_STATSts_VIP 0;
BA_ "GenSigTimeoutTime_EVCU2" SG_ 616 BSS_CFG_STATSts_VIP 0;
BA_ "GenSigTimeoutTime_ORC" SG_ 616 BSS_CFG_STATSts_VIP 0;
BA_ "GenSigTimeoutTime_ADCAM" SG_ 616 BSS_DispPopoupSts_VIP 0;
BA_ "GenSigTimeoutTime_CVADAS" SG_ 616 BSS_DispPopoupSts_VIP 0;
BA_ "GenSigSendType" SG_ 616 BSS_DispPopoupSts_VIP 3;
BA_ "GenSigTimeoutTime_BSM" SG_ 616 BSS_DispPopoupSts_VIP 0;
BA_ "GenSigTimeoutTime_BSM2" SG_ 616 BSS_DispPopoupSts_VIP 0;
BA_ "GenSigTimeoutTime_EPS" SG_ 616 BSS_DispPopoupSts_VIP 0;
BA_ "GenSigTimeoutTime_EVCU2" SG_ 616 BSS_DispPopoupSts_VIP 0;
BA_ "GenSigTimeoutTime_ORC" SG_ 616 BSS_DispPopoupSts_VIP 0;
BA_ "GenSigTimeoutTime_ADCAM" SG_ 616 BSS_SRV_RQSts_VIP 0;
BA_ "GenSigTimeoutTime_CVADAS" SG_ 616 BSS_SRV_RQSts_VIP 0;
BA_ "GenSigSendType" SG_ 616 BSS_SRV_RQSts_VIP 3;
BA_ "GenSigTimeoutTime_BSM" SG_ 616 BSS_SRV_RQSts_VIP 0;
BA_ "GenSigTimeoutTime_BSM2" SG_ 616 BSS_SRV_RQSts_VIP 0;
BA_ "GenSigTimeoutTime_EPS" SG_ 616 BSS_SRV_RQSts_VIP 0;
BA_ "GenSigTimeoutTime_EVCU2" SG_ 616 BSS_SRV_RQSts_VIP 0;
BA_ "GenSigTimeoutTime_ORC" SG_ 616 BSS_SRV_RQSts_VIP 0;
BA_ "GenSigTimeoutTime_ADCAM" SG_ 616 MessageCounter_ADAS_FD_HMI_VIP 0;
BA_ "GenSigTimeoutTime_CVADAS" SG_ 616 MessageCounter_ADAS_FD_HMI_VIP 0;
BA_ "GenSigTimeoutTime_BSM" SG_ 616 MessageCounter_ADAS_FD_HMI_VIP 0;
BA_ "GenSigTimeoutTime_BSM2" SG_ 616 MessageCounter_ADAS_FD_HMI_VIP 0;
BA_ "GenSigTimeoutTime_EPS" SG_ 616 MessageCounter_ADAS_FD_HMI_VIP 0;
BA_ "GenSigTimeoutTime_EVCU2" SG_ 616 MessageCounter_ADAS_FD_HMI_VIP 0;
BA_ "GenSigTimeoutTime_ORC" SG_ 616 MessageCounter_ADAS_FD_HMI_VIP 0;
BA_ "GenSigTimeoutTime_ADCAM" SG_ 616 AEB_Blind_VIP 0;
BA_ "GenSigTimeoutTime_CVADAS" SG_ 616 AEB_Blind_VIP 0;
BA_ "GenSigSendType" SG_ 616 AEB_Blind_VIP 3;
BA_ "GenSigTimeoutTime_BSM" SG_ 616 AEB_Blind_VIP 0;
BA_ "GenSigTimeoutTime_BSM2" SG_ 616 AEB_Blind_VIP 0;
BA_ "GenSigTimeoutTime_EPS" SG_ 616 AEB_Blind_VIP 0;
BA_ "GenSigTimeoutTime_EVCU2" SG_ 616 AEB_Blind_VIP 0;
BA_ "GenSigTimeoutTime_ORC" SG_ 616 AEB_Blind_VIP 0;
BA_ "GenSigTimeoutTime_ADCAM" SG_ 616 AEB_DispPopupSts_VIP 0;
BA_ "GenSigTimeoutTime_CVADAS" SG_ 616 AEB_DispPopupSts_VIP 0;
BA_ "GenSigSendType" SG_ 616 AEB_DispPopupSts_VIP 3;
BA_ "GenSigTimeoutTime_BSM" SG_ 616 AEB_DispPopupSts_VIP 0;
BA_ "GenSigTimeoutTime_BSM2" SG_ 616 AEB_DispPopupSts_VIP 0;
BA_ "GenSigTimeoutTime_EPS" SG_ 616 AEB_DispPopupSts_VIP 0;
BA_ "GenSigTimeoutTime_EVCU2" SG_ 616 AEB_DispPopupSts_VIP 0;
BA_ "GenSigTimeoutTime_ORC" SG_ 616 AEB_DispPopupSts_VIP 0;
BA_ "GenSigTimeoutTime_ADCAM" SG_ 616 AEB_FailSts_VIP 0;
BA_ "GenSigTimeoutTime_CVADAS" SG_ 616 AEB_FailSts_VIP 0;
BA_ "GenSigSendType" SG_ 616 AEB_FailSts_VIP 3;
BA_ "GenSigTimeoutTime_BSM" SG_ 616 AEB_FailSts_VIP 0;
BA_ "GenSigTimeoutTime_BSM2" SG_ 616 AEB_FailSts_VIP 0;
BA_ "GenSigTimeoutTime_EPS" SG_ 616 AEB_FailSts_VIP 0;
BA_ "GenSigTimeoutTime_EVCU2" SG_ 616 AEB_FailSts_VIP 0;
BA_ "GenSigTimeoutTime_ORC" SG_ 616 AEB_FailSts_VIP 0;
BA_ "GenSigTimeoutTime_ADCAM" SG_ 616 AEB_Limit_Fail_VIP 0;
BA_ "GenSigTimeoutTime_CVADAS" SG_ 616 AEB_Limit_Fail_VIP 0;
BA_ "GenSigSendType" SG_ 616 AEB_Limit_Fail_VIP 3;
BA_ "GenSigTimeoutTime_BSM" SG_ 616 AEB_Limit_Fail_VIP 0;
BA_ "GenSigTimeoutTime_BSM2" SG_ 616 AEB_Limit_Fail_VIP 0;
BA_ "GenSigTimeoutTime_EPS" SG_ 616 AEB_Limit_Fail_VIP 0;
BA_ "GenSigTimeoutTime_EVCU2" SG_ 616 AEB_Limit_Fail_VIP 0;
BA_ "GenSigTimeoutTime_ORC" SG_ 616 AEB_Limit_Fail_VIP 0;
BA_ "GenSigTimeoutTime_ADCAM" SG_ 616 AEB_Limited_VIP 0;
BA_ "GenSigTimeoutTime_CVADAS" SG_ 616 AEB_Limited_VIP 0;
BA_ "GenSigSendType" SG_ 616 AEB_Limited_VIP 3;
BA_ "GenSigTimeoutTime_BSM" SG_ 616 AEB_Limited_VIP 0;
BA_ "GenSigTimeoutTime_BSM2" SG_ 616 AEB_Limited_VIP 0;
BA_ "GenSigTimeoutTime_EPS" SG_ 616 AEB_Limited_VIP 0;
BA_ "GenSigTimeoutTime_EVCU2" SG_ 616 AEB_Limited_VIP 0;
BA_ "GenSigTimeoutTime_ORC" SG_ 616 AEB_Limited_VIP 0;
BA_ "GenSigTimeoutTime_ADCAM" SG_ 616 CRC_ADAS_FD_HMI_VIP 0;
BA_ "GenSigTimeoutTime_CVADAS" SG_ 616 CRC_ADAS_FD_HMI_VIP 0;
BA_ "GenSigTimeoutTime_BSM" SG_ 616 CRC_ADAS_FD_HMI_VIP 0;
BA_ "GenSigTimeoutTime_BSM2" SG_ 616 CRC_ADAS_FD_HMI_VIP 0;
BA_ "GenSigTimeoutTime_EPS" SG_ 616 CRC_ADAS_FD_HMI_VIP 0;
BA_ "GenSigTimeoutTime_EVCU2" SG_ 616 CRC_ADAS_FD_HMI_VIP 0;
BA_ "GenSigTimeoutTime_ORC" SG_ 616 CRC_ADAS_FD_HMI_VIP 0;
BA_ "GenSigTimeoutTime_ADCAM" SG_ 616 LKA_FailSts_VIP 0;
BA_ "GenSigTimeoutTime_CVADAS" SG_ 616 LKA_FailSts_VIP 0;
BA_ "GenSigSendType" SG_ 616 LKA_FailSts_VIP 3;
BA_ "GenSigTimeoutTime_BSM" SG_ 616 LKA_FailSts_VIP 0;
BA_ "GenSigTimeoutTime_BSM2" SG_ 616 LKA_FailSts_VIP 0;
BA_ "GenSigTimeoutTime_EPS" SG_ 616 LKA_FailSts_VIP 0;
BA_ "GenSigTimeoutTime_EVCU2" SG_ 616 LKA_FailSts_VIP 0;
BA_ "GenSigTimeoutTime_ORC" SG_ 616 LKA_FailSts_VIP 0;
BA_ "GenSigTimeoutTime_ADCAM" SG_ 616 LR_Chime_RqSts_VIP 0;
BA_ "GenSigTimeoutTime_CVADAS" SG_ 616 LR_Chime_RqSts_VIP 0;
BA_ "GenSigSendType" SG_ 616 LR_Chime_RqSts_VIP 3;
BA_ "GenSigTimeoutTime_BSM" SG_ 616 LR_Chime_RqSts_VIP 0;
BA_ "GenSigTimeoutTime_BSM2" SG_ 616 LR_Chime_RqSts_VIP 0;
BA_ "GenSigTimeoutTime_EPS" SG_ 616 LR_Chime_RqSts_VIP 0;
BA_ "GenSigTimeoutTime_EVCU2" SG_ 616 LR_Chime_RqSts_VIP 0;
BA_ "GenSigTimeoutTime_ORC" SG_ 616 LR_Chime_RqSts_VIP 0;
BA_ "GenSigTimeoutTime_ADCAM" SG_ 616 PEB_Setting_Avail_VIP 0;
BA_ "GenSigTimeoutTime_CVADAS" SG_ 616 PEB_Setting_Avail_VIP 0;
BA_ "GenSigSendType" SG_ 616 PEB_Setting_Avail_VIP 3;
BA_ "GenSigTimeoutTime_BSM" SG_ 616 PEB_Setting_Avail_VIP 0;
BA_ "GenSigTimeoutTime_BSM2" SG_ 616 PEB_Setting_Avail_VIP 0;
BA_ "GenSigTimeoutTime_EPS" SG_ 616 PEB_Setting_Avail_VIP 0;
BA_ "GenSigTimeoutTime_EVCU2" SG_ 616 PEB_Setting_Avail_VIP 0;
BA_ "GenSigTimeoutTime_ORC" SG_ 616 PEB_Setting_Avail_VIP 0;
BA_ "GenSigTimeoutTime_ADCAM" SG_ 616 RR_Chime_RqSts_VIP 0;
BA_ "GenSigTimeoutTime_CVADAS" SG_ 616 RR_Chime_RqSts_VIP 0;
BA_ "GenSigSendType" SG_ 616 RR_Chime_RqSts_VIP 3;
BA_ "GenSigTimeoutTime_BSM" SG_ 616 RR_Chime_RqSts_VIP 0;
BA_ "GenSigTimeoutTime_BSM2" SG_ 616 RR_Chime_RqSts_VIP 0;
BA_ "GenSigTimeoutTime_EPS" SG_ 616 RR_Chime_RqSts_VIP 0;
BA_ "GenSigTimeoutTime_EVCU2" SG_ 616 RR_Chime_RqSts_VIP 0;
BA_ "GenSigTimeoutTime_ORC" SG_ 616 RR_Chime_RqSts_VIP 0;
BA_ "GenSigTimeoutTime_ADCAM" SG_ 616 Set_Speed_KPH_VIP 0;
BA_ "GenSigTimeoutTime_CVADAS" SG_ 616 Set_Speed_KPH_VIP 0;
BA_ "GenSigSendType" SG_ 616 Set_Speed_KPH_VIP 3;
BA_ "GenSigTimeoutTime_BSM" SG_ 616 Set_Speed_KPH_VIP 0;
BA_ "GenSigTimeoutTime_BSM2" SG_ 616 Set_Speed_KPH_VIP 0;
BA_ "GenSigTimeoutTime_EPS" SG_ 616 Set_Speed_KPH_VIP 0;
BA_ "GenSigTimeoutTime_EVCU2" SG_ 616 Set_Speed_KPH_VIP 0;
BA_ "GenSigTimeoutTime_ORC" SG_ 616 Set_Speed_KPH_VIP 0;
BA_ "GenSigTimeoutTime_ADCAM" SG_ 616 Set_Speed_MPH_VIP 0;
BA_ "GenSigTimeoutTime_CVADAS" SG_ 616 Set_Speed_MPH_VIP 0;
BA_ "GenSigSendType" SG_ 616 Set_Speed_MPH_VIP 3;
BA_ "GenSigTimeoutTime_BSM" SG_ 616 Set_Speed_MPH_VIP 0;
BA_ "GenSigTimeoutTime_BSM2" SG_ 616 Set_Speed_MPH_VIP 0;
BA_ "GenSigTimeoutTime_EPS" SG_ 616 Set_Speed_MPH_VIP 0;
BA_ "GenSigTimeoutTime_EVCU2" SG_ 616 Set_Speed_MPH_VIP 0;
BA_ "GenSigTimeoutTime_ORC" SG_ 616 Set_Speed_MPH_VIP 0;
BA_ "GenSigTimeoutTime_ADCAM" SG_ 209 LC_Jerk_VIP 0;
BA_ "GenSigTimeoutTime_CVADAS" SG_ 209 LC_Jerk_VIP 0;
BA_ "GenSigTimeoutTime_BSM" SG_ 209 LC_Jerk_VIP 0;
BA_ "GenSigTimeoutTime_BSM2" SG_ 209 LC_Jerk_VIP 0;
BA_ "GenSigTimeoutTime_EPS" SG_ 209 LC_Jerk_VIP 0;
BA_ "GenSigTimeoutTime_EVCU2" SG_ 209 LC_Jerk_VIP 0;
BA_ "GenSigTimeoutTime_ORC" SG_ 209 LC_Jerk_VIP 0;
BA_ "GenSigTimeoutTime_ADCAM" SG_ 209 LKA_LAT_CTRL_RequestSts_VIP 0;
BA_ "GenSigTimeoutTime_CVADAS" SG_ 209 LKA_LAT_CTRL_RequestSts_VIP 0;
BA_ "GenSigTimeoutTime_BSM" SG_ 209 LKA_LAT_CTRL_RequestSts_VIP 0;
BA_ "GenSigTimeoutTime_BSM2" SG_ 209 LKA_LAT_CTRL_RequestSts_VIP 0;
BA_ "GenSigTimeoutTime_EPS" SG_ 209 LKA_LAT_CTRL_RequestSts_VIP 0;
BA_ "GenSigTimeoutTime_EVCU2" SG_ 209 LKA_LAT_CTRL_RequestSts_VIP 0;
BA_ "GenSigTimeoutTime_ORC" SG_ 209 LKA_LAT_CTRL_RequestSts_VIP 0;
BA_ "GenSigTimeoutTime_ADCAM" SG_ 209 Object_Dist_VIP 0;
BA_ "GenSigTimeoutTime_CVADAS" SG_ 209 Object_Dist_VIP 0;
BA_ "GenSigStartValue" SG_ 209 Object_Dist_VIP 255;
BA_ "GenSigTimeoutTime_BSM" SG_ 209 Object_Dist_VIP 0;
BA_ "GenSigTimeoutTime_BSM2" SG_ 209 Object_Dist_VIP 0;
BA_ "GenSigTimeoutTime_EPS" SG_ 209 Object_Dist_VIP 0;
BA_ "GenSigTimeoutTime_EVCU2" SG_ 209 Object_Dist_VIP 0;
BA_ "GenSigTimeoutTime_ORC" SG_ 209 Object_Dist_VIP 0;
BA_ "GenSigTimeoutTime_ADCAM" SG_ 209 PEB_SystemSts_VIP 0;
BA_ "GenSigTimeoutTime_CVADAS" SG_ 209 PEB_SystemSts_VIP 0;
BA_ "GenSigTimeoutTime_BSM" SG_ 209 PEB_SystemSts_VIP 0;
BA_ "GenSigTimeoutTime_BSM2" SG_ 209 PEB_SystemSts_VIP 0;
BA_ "GenSigTimeoutTime_EPS" SG_ 209 PEB_SystemSts_VIP 0;
BA_ "GenSigTimeoutTime_EVCU2" SG_ 209 PEB_SystemSts_VIP 0;
BA_ "GenSigTimeoutTime_ORC" SG_ 209 PEB_SystemSts_VIP 0;
BA_ "GenSigTimeoutTime_ADCAM" SG_ 209 Prefill_Req_VIP 0;
BA_ "GenSigTimeoutTime_CVADAS" SG_ 209 Prefill_Req_VIP 0;
BA_ "GenSigTimeoutTime_BSM" SG_ 209 Prefill_Req_VIP 0;
BA_ "GenSigTimeoutTime_BSM2" SG_ 209 Prefill_Req_VIP 0;
BA_ "GenSigTimeoutTime_EPS" SG_ 209 Prefill_Req_VIP 0;
BA_ "GenSigTimeoutTime_EVCU2" SG_ 209 Prefill_Req_VIP 0;
BA_ "GenSigTimeoutTime_ORC" SG_ 209 Prefill_Req_VIP 0;
BA_ "GenSigTimeoutTime_ADCAM" SG_ 209 SteeringVibration_Rq_VIP 0;
BA_ "GenSigTimeoutTime_CVADAS" SG_ 209 SteeringVibration_Rq_VIP 0;
BA_ "GenSigTimeoutTime_BSM" SG_ 209 SteeringVibration_Rq_VIP 0;
BA_ "GenSigTimeoutTime_BSM2" SG_ 209 SteeringVibration_Rq_VIP 0;
BA_ "GenSigTimeoutTime_EPS" SG_ 209 SteeringVibration_Rq_VIP 0;
BA_ "GenSigTimeoutTime_EVCU2" SG_ 209 SteeringVibration_Rq_VIP 0;
BA_ "GenSigTimeoutTime_ORC" SG_ 209 SteeringVibration_Rq_VIP 0;
BA_ "GenSigTimeoutTime_ADCAM" SG_ 209 AEB_Systemsts_VIP 0;
BA_ "GenSigTimeoutTime_CVADAS" SG_ 209 AEB_Systemsts_VIP 0;
BA_ "GenSigTimeoutTime_BSM" SG_ 209 AEB_Systemsts_VIP 0;
BA_ "GenSigTimeoutTime_BSM2" SG_ 209 AEB_Systemsts_VIP 0;
BA_ "GenSigTimeoutTime_EPS" SG_ 209 AEB_Systemsts_VIP 0;
BA_ "GenSigTimeoutTime_EVCU2" SG_ 209 AEB_Systemsts_VIP 0;
BA_ "GenSigTimeoutTime_ORC" SG_ 209 AEB_Systemsts_VIP 0;
BA_ "GenSigTimeoutTime_ADCAM" SG_ 209 Brake_Jerk_Req_VIP 0;
BA_ "GenSigTimeoutTime_CVADAS" SG_ 209 Brake_Jerk_Req_VIP 0;
BA_ "GenSigTimeoutTime_BSM" SG_ 209 Brake_Jerk_Req_VIP 0;
BA_ "GenSigTimeoutTime_BSM2" SG_ 209 Brake_Jerk_Req_VIP 0;
BA_ "GenSigTimeoutTime_EPS" SG_ 209 Brake_Jerk_Req_VIP 0;
BA_ "GenSigTimeoutTime_EVCU2" SG_ 209 Brake_Jerk_Req_VIP 0;
BA_ "GenSigTimeoutTime_ORC" SG_ 209 Brake_Jerk_Req_VIP 0;
BA_ "GenSigTimeoutTime_ADCAM" SG_ 209 CIPV_Fused_VIP 0;
BA_ "GenSigTimeoutTime_CVADAS" SG_ 209 CIPV_Fused_VIP 0;
BA_ "GenSigTimeoutTime_BSM" SG_ 209 CIPV_Fused_VIP 0;
BA_ "GenSigTimeoutTime_BSM2" SG_ 209 CIPV_Fused_VIP 0;
BA_ "GenSigTimeoutTime_EPS" SG_ 209 CIPV_Fused_VIP 0;
BA_ "GenSigTimeoutTime_EVCU2" SG_ 209 CIPV_Fused_VIP 0;
BA_ "GenSigTimeoutTime_ORC" SG_ 209 CIPV_Fused_VIP 0;
BA_ "GenSigTimeoutTime_ADCAM" SG_ 209 DDD_Setting_Avail_VIP 0;
BA_ "GenSigTimeoutTime_CVADAS" SG_ 209 DDD_Setting_Avail_VIP 0;
BA_ "GenSigTimeoutTime_BSM" SG_ 209 DDD_Setting_Avail_VIP 0;
BA_ "GenSigTimeoutTime_BSM2" SG_ 209 DDD_Setting_Avail_VIP 0;
BA_ "GenSigTimeoutTime_EPS" SG_ 209 DDD_Setting_Avail_VIP 0;
BA_ "GenSigTimeoutTime_EVCU2" SG_ 209 DDD_Setting_Avail_VIP 0;
BA_ "GenSigTimeoutTime_ORC" SG_ 209 DDD_Setting_Avail_VIP 0;
BA_ "GenSigTimeoutTime_ADCAM" SG_ 209 DDD_SystemSts_VIP 0;
BA_ "GenSigTimeoutTime_CVADAS" SG_ 209 DDD_SystemSts_VIP 0;
BA_ "GenSigTimeoutTime_BSM" SG_ 209 DDD_SystemSts_VIP 0;
BA_ "GenSigTimeoutTime_BSM2" SG_ 209 DDD_SystemSts_VIP 0;
BA_ "GenSigTimeoutTime_EPS" SG_ 209 DDD_SystemSts_VIP 0;
BA_ "GenSigTimeoutTime_EVCU2" SG_ 209 DDD_SystemSts_VIP 0;
BA_ "GenSigTimeoutTime_ORC" SG_ 209 DDD_SystemSts_VIP 0;
BA_ "GenSigTimeoutTime_ADCAM" SG_ 209 GrMax_Rq_ACC_VIP 0;
BA_ "GenSigTimeoutTime_CVADAS" SG_ 209 GrMax_Rq_ACC_VIP 0;
BA_ "GenSigTimeoutTime_BSM" SG_ 209 GrMax_Rq_ACC_VIP 0;
BA_ "GenSigTimeoutTime_BSM2" SG_ 209 GrMax_Rq_ACC_VIP 0;
BA_ "GenSigTimeoutTime_EPS" SG_ 209 GrMax_Rq_ACC_VIP 0;
BA_ "GenSigTimeoutTime_EVCU2" SG_ 209 GrMax_Rq_ACC_VIP 0;
BA_ "GenSigTimeoutTime_ORC" SG_ 209 GrMax_Rq_ACC_VIP 0;
BA_ "GenSigTimeoutTime_ADCAM" SG_ 209 CRC_ADAS_FD_INFO_VIP 0;
BA_ "GenSigTimeoutTime_CVADAS" SG_ 209 CRC_ADAS_FD_INFO_VIP 0;
BA_ "GenSigTimeoutTime_BSM" SG_ 209 CRC_ADAS_FD_INFO_VIP 0;
BA_ "GenSigTimeoutTime_BSM2" SG_ 209 CRC_ADAS_FD_INFO_VIP 0;
BA_ "GenSigTimeoutTime_EPS" SG_ 209 CRC_ADAS_FD_INFO_VIP 0;
BA_ "GenSigTimeoutTime_EVCU2" SG_ 209 CRC_ADAS_FD_INFO_VIP 0;
BA_ "GenSigTimeoutTime_ORC" SG_ 209 CRC_ADAS_FD_INFO_VIP 0;
BA_ "GenSigTimeoutTime_ADCAM" SG_ 209 MessageCounter_ADAS_FD_INFO_VIP 0;
BA_ "GenSigTimeoutTime_CVADAS" SG_ 209 MessageCounter_ADAS_FD_INFO_VIP 0;
BA_ "GenSigTimeoutTime_BSM" SG_ 209 MessageCounter_ADAS_FD_INFO_VIP 0;
BA_ "GenSigTimeoutTime_BSM2" SG_ 209 MessageCounter_ADAS_FD_INFO_VIP 0;
BA_ "GenSigTimeoutTime_EPS" SG_ 209 MessageCounter_ADAS_FD_INFO_VIP 0;
BA_ "GenSigTimeoutTime_EVCU2" SG_ 209 MessageCounter_ADAS_FD_INFO_VIP 0;
BA_ "GenSigTimeoutTime_ORC" SG_ 209 MessageCounter_ADAS_FD_INFO_VIP 0;
BA_ "GenSigTimeoutTime_ADCAM" SG_ 209 ACC_DsrSpeedKPH_VIP 0;
BA_ "GenSigTimeoutTime_CVADAS" SG_ 209 ACC_DsrSpeedKPH_VIP 0;
BA_ "GenSigStartValue" SG_ 209 ACC_DsrSpeedKPH_VIP 255;
BA_ "GenSigTimeoutTime_BSM" SG_ 209 ACC_DsrSpeedKPH_VIP 0;
BA_ "GenSigTimeoutTime_BSM2" SG_ 209 ACC_DsrSpeedKPH_VIP 0;
BA_ "GenSigTimeoutTime_EPS" SG_ 209 ACC_DsrSpeedKPH_VIP 0;
BA_ "GenSigTimeoutTime_EVCU2" SG_ 209 ACC_DsrSpeedKPH_VIP 0;
BA_ "GenSigTimeoutTime_ORC" SG_ 209 ACC_DsrSpeedKPH_VIP 0;
BA_ "GenSigTimeoutTime_ADCAM" SG_ 209 AEB_Sensitivity_Setting_VIP 0;
BA_ "GenSigTimeoutTime_CVADAS" SG_ 209 AEB_Sensitivity_Setting_VIP 0;
BA_ "GenSigTimeoutTime_BSM" SG_ 209 AEB_Sensitivity_Setting_VIP 0;
BA_ "GenSigTimeoutTime_BSM2" SG_ 209 AEB_Sensitivity_Setting_VIP 0;
BA_ "GenSigTimeoutTime_EPS" SG_ 209 AEB_Sensitivity_Setting_VIP 0;
BA_ "GenSigTimeoutTime_EVCU2" SG_ 209 AEB_Sensitivity_Setting_VIP 0;
BA_ "GenSigTimeoutTime_ORC" SG_ 209 AEB_Sensitivity_Setting_VIP 0;
BA_ "GenSigTimeoutTime_ADCAM" SG_ 209 SteeringVibration_Type_VIP 0;
BA_ "GenSigTimeoutTime_CVADAS" SG_ 209 SteeringVibration_Type_VIP 0;
BA_ "GenSigTimeoutTime_BSM" SG_ 209 SteeringVibration_Type_VIP 0;
BA_ "GenSigTimeoutTime_BSM2" SG_ 209 SteeringVibration_Type_VIP 0;
BA_ "GenSigTimeoutTime_EPS" SG_ 209 SteeringVibration_Type_VIP 0;
BA_ "GenSigTimeoutTime_EVCU2" SG_ 209 SteeringVibration_Type_VIP 0;
BA_ "GenSigTimeoutTime_ORC" SG_ 209 SteeringVibration_Type_VIP 0;
BA_ "GenSigTimeoutTime_ADCAM" SG_ 209 TorqueOverlaySteeringReq_VIP 0;
BA_ "GenSigTimeoutTime_CVADAS" SG_ 209 TorqueOverlaySteeringReq_VIP 0;
BA_ "GenSigStartValue" SG_ 209 TorqueOverlaySteeringReq_VIP 1024;
BA_ "GenSigTimeoutTime_BSM" SG_ 209 TorqueOverlaySteeringReq_VIP 0;
BA_ "GenSigTimeoutTime_BSM2" SG_ 209 TorqueOverlaySteeringReq_VIP 0;
BA_ "GenSigTimeoutTime_EPS" SG_ 209 TorqueOverlaySteeringReq_VIP 0;
BA_ "GenSigTimeoutTime_EVCU2" SG_ 209 TorqueOverlaySteeringReq_VIP 0;
BA_ "GenSigTimeoutTime_ORC" SG_ 209 TorqueOverlaySteeringReq_VIP 0;
BA_ "GenSigTimeoutTime_ADCAM" SG_ 209 ACC_Engine_Torque_Enabled_VIP 0;
BA_ "GenSigTimeoutTime_CVADAS" SG_ 209 ACC_Engine_Torque_Enabled_VIP 0;
BA_ "GenSigTimeoutTime_BSM" SG_ 209 ACC_Engine_Torque_Enabled_VIP 0;
BA_ "GenSigTimeoutTime_BSM2" SG_ 209 ACC_Engine_Torque_Enabled_VIP 0;
BA_ "GenSigTimeoutTime_EPS" SG_ 209 ACC_Engine_Torque_Enabled_VIP 0;
BA_ "GenSigTimeoutTime_EVCU2" SG_ 209 ACC_Engine_Torque_Enabled_VIP 0;
BA_ "GenSigTimeoutTime_ORC" SG_ 209 ACC_Engine_Torque_Enabled_VIP 0;
BA_ "GenSigTimeoutTime_ADCAM" SG_ 209 ACC_Systemsts_VIP 0;
BA_ "GenSigTimeoutTime_CVADAS" SG_ 209 ACC_Systemsts_VIP 0;
BA_ "GenSigTimeoutTime_BSM" SG_ 209 ACC_Systemsts_VIP 0;
BA_ "GenSigTimeoutTime_BSM2" SG_ 209 ACC_Systemsts_VIP 0;
BA_ "GenSigTimeoutTime_EPS" SG_ 209 ACC_Systemsts_VIP 0;
BA_ "GenSigTimeoutTime_EVCU2" SG_ 209 ACC_Systemsts_VIP 0;
BA_ "GenSigTimeoutTime_ORC" SG_ 209 ACC_Systemsts_VIP 0;
BA_ "GenSigTimeoutTime_ADCAM" SG_ 209 AEB_Type_VIP 0;
BA_ "GenSigTimeoutTime_CVADAS" SG_ 209 AEB_Type_VIP 0;
BA_ "GenSigTimeoutTime_BSM" SG_ 209 AEB_Type_VIP 0;
BA_ "GenSigTimeoutTime_BSM2" SG_ 209 AEB_Type_VIP 0;
BA_ "GenSigTimeoutTime_EPS" SG_ 209 AEB_Type_VIP 0;
BA_ "GenSigTimeoutTime_EVCU2" SG_ 209 AEB_Type_VIP 0;
BA_ "GenSigTimeoutTime_ORC" SG_ 209 AEB_Type_VIP 0;
BA_ "GenSigTimeoutTime_ADCAM" SG_ 209 Intervention_VIP 0;
BA_ "GenSigTimeoutTime_CVADAS" SG_ 209 Intervention_VIP 0;
BA_ "GenSigStartValue" SG_ 209 Intervention_VIP 4095;
BA_ "GenSigTimeoutTime_BSM" SG_ 209 Intervention_VIP 0;
BA_ "GenSigTimeoutTime_BSM2" SG_ 209 Intervention_VIP 0;
BA_ "GenSigTimeoutTime_EPS" SG_ 209 Intervention_VIP 0;
BA_ "GenSigTimeoutTime_EVCU2" SG_ 209 Intervention_VIP 0;
BA_ "GenSigTimeoutTime_ORC" SG_ 209 Intervention_VIP 0;
BA_ "GenSigTimeoutTime_ADCAM" SG_ 210 ACC_Axle_Torque_VIP 0;
BA_ "GenSigTimeoutTime_CVADAS" SG_ 210 ACC_Axle_Torque_VIP 0;
BA_ "GenSigStartValue" SG_ 210 ACC_Axle_Torque_VIP 32768;
BA_ "GenSigTimeoutTime_BSM" SG_ 210 ACC_Axle_Torque_VIP 0;
BA_ "GenSigTimeoutTime_BSM2" SG_ 210 ACC_Axle_Torque_VIP 0;
BA_ "GenSigTimeoutTime_EPS" SG_ 210 ACC_Axle_Torque_VIP 0;
BA_ "GenSigTimeoutTime_EVCU2" SG_ 210 ACC_Axle_Torque_VIP 0;
BA_ "GenSigTimeoutTime_ORC" SG_ 210 ACC_Axle_Torque_VIP 0;
BA_ "GenSigTimeoutTime_MPAD" SG_ 97 GTS_Byte3 0;
BA_ "GenSigTimeoutTime_ADCAM" SG_ 97 GTS_Byte3 0;
BA_ "GenSigTimeoutTime_EPS" SG_ 97 GTS_Byte3 0;
BA_ "GenSigTimeoutTime_EVCU2" SG_ 97 GTS_Byte3 0;
BA_ "GenSigTimeoutTime_MPAD" SG_ 97 GTS_CRC 0;
BA_ "GenSigTimeoutTime_ADCAM" SG_ 97 GTS_CRC 0;
BA_ "GenSigTimeoutTime_EPS" SG_ 97 GTS_CRC 0;
BA_ "GenSigTimeoutTime_EVCU2" SG_ 97 GTS_CRC 0;
BA_ "GenSigTimeoutTime_MPAD" SG_ 97 GTS_D 0;
BA_ "GenSigTimeoutTime_ADCAM" SG_ 97 GTS_D 0;
BA_ "GenSigTimeoutTime_EPS" SG_ 97 GTS_D 0;
BA_ "GenSigTimeoutTime_EVCU2" SG_ 97 GTS_D 0;
BA_ "GenSigTimeoutTime_MPAD" SG_ 97 GTS_SC 0;
BA_ "GenSigTimeoutTime_ADCAM" SG_ 97 GTS_SC 0;
BA_ "GenSigTimeoutTime_EPS" SG_ 97 GTS_SC 0;
BA_ "GenSigTimeoutTime_EVCU2" SG_ 97 GTS_SC 0;
BA_ "GenSigTimeoutTime_MPAD" SG_ 97 GTS_Type 0;
BA_ "GenSigTimeoutTime_ADCAM" SG_ 97 GTS_Type 0;
BA_ "GenSigSendType" SG_ 97 GTS_Type 1;
BA_ "GenSigTimeoutTime_EPS" SG_ 97 GTS_Type 0;
BA_ "GenSigTimeoutTime_EVCU2" SG_ 97 GTS_Type 0;
BA_ "GenSigTimeoutTime_MPAD" SG_ 97 OfsTimeNSec 0;
BA_ "GenSigTimeoutTime_ADCAM" SG_ 97 OfsTimeNSec 0;
BA_ "GenSigTimeoutTime_EPS" SG_ 97 OfsTimeNSec 0;
BA_ "GenSigTimeoutTime_EVCU2" SG_ 97 OfsTimeNSec 0;
BA_ "GenSigTimeoutTime_MPAD" SG_ 97 OfsTimeSec 0;
BA_ "GenSigTimeoutTime_ADCAM" SG_ 97 OfsTimeSec 0;
BA_ "GenSigTimeoutTime_EPS" SG_ 97 OfsTimeSec 0;
BA_ "GenSigTimeoutTime_EVCU2" SG_ 97 OfsTimeSec 0;
BA_ "GenSigTimeoutTime_MPAD" SG_ 97 SyncTime 0;
BA_ "GenSigTimeoutTime_ADCAM" SG_ 97 SyncTime 0;
BA_ "GenSigTimeoutTime_EPS" SG_ 97 SyncTime 0;
BA_ "GenSigTimeoutTime_EVCU2" SG_ 97 SyncTime 0;
BA_ "GenSigTimeoutTime_MPAD" SG_ 213 CRC_VIP_INFO_FD 0;
BA_ "GenSigTimeoutTime_CVADAS" SG_ 213 CRC_VIP_INFO_FD 0;
BA_ "GenSigTimeoutTime_BSM" SG_ 213 CRC_VIP_INFO_FD 0;
BA_ "GenSigTimeoutTime_BSM2" SG_ 213 CRC_VIP_INFO_FD 0;
BA_ "GenSigTimeoutTime_EPS" SG_ 213 CRC_VIP_INFO_FD 0;
BA_ "GenSigTimeoutTime_EVCU2" SG_ 213 CRC_VIP_INFO_FD 0;
BA_ "GenSigTimeoutTime_ORC" SG_ 213 CRC_VIP_INFO_FD 0;
BA_ "GenSigTimeoutTime_MPAD" SG_ 213 MessageCounter_VIP_INFO_FD 0;
BA_ "GenSigTimeoutTime_CVADAS" SG_ 213 MessageCounter_VIP_INFO_FD 0;
BA_ "GenSigTimeoutTime_BSM" SG_ 213 MessageCounter_VIP_INFO_FD 0;
BA_ "GenSigTimeoutTime_BSM2" SG_ 213 MessageCounter_VIP_INFO_FD 0;
BA_ "GenSigTimeoutTime_EPS" SG_ 213 MessageCounter_VIP_INFO_FD 0;
BA_ "GenSigTimeoutTime_EVCU2" SG_ 213 MessageCounter_VIP_INFO_FD 0;
BA_ "GenSigTimeoutTime_ORC" SG_ 213 MessageCounter_VIP_INFO_FD 0;
BA_ "GenSigTimeoutTime_MPAD" SG_ 213 ACCFSafe_D5 0;
BA_ "GenSigTimeoutTime_CVADAS" SG_ 213 ACCFSafe_D5 0;
BA_ "GenSigTimeoutTime_BSM" SG_ 213 ACCFSafe_D5 0;
BA_ "GenSigTimeoutTime_BSM2" SG_ 213 ACCFSafe_D5 0;
BA_ "GenSigTimeoutTime_EPS" SG_ 213 ACCFSafe_D5 0;
BA_ "GenSigTimeoutTime_EVCU2" SG_ 213 ACCFSafe_D5 0;
BA_ "GenSigTimeoutTime_ORC" SG_ 213 ACCFSafe_D5 0;
BA_ "GenSigTimeoutTime_MPAD" SG_ 213 AEB_Type_Brk_D5 0;
BA_ "GenSigTimeoutTime_CVADAS" SG_ 213 AEB_Type_Brk_D5 0;
BA_ "GenSigTimeoutTime_BSM" SG_ 213 AEB_Type_Brk_D5 0;
BA_ "GenSigTimeoutTime_BSM2" SG_ 213 AEB_Type_Brk_D5 0;
BA_ "GenSigTimeoutTime_EPS" SG_ 213 AEB_Type_Brk_D5 0;
BA_ "GenSigTimeoutTime_EVCU2" SG_ 213 AEB_Type_Brk_D5 0;
BA_ "GenSigTimeoutTime_ORC" SG_ 213 AEB_Type_Brk_D5 0;
BA_ "GenSigTimeoutTime_MPAD" SG_ 213 DASEngReqPos_D5 0;
BA_ "GenSigTimeoutTime_CVADAS" SG_ 213 DASEngReqPos_D5 0;
BA_ "GenSigTimeoutTime_BSM" SG_ 213 DASEngReqPos_D5 0;
BA_ "GenSigTimeoutTime_BSM2" SG_ 213 DASEngReqPos_D5 0;
BA_ "GenSigTimeoutTime_EPS" SG_ 213 DASEngReqPos_D5 0;
BA_ "GenSigTimeoutTime_EVCU2" SG_ 213 DASEngReqPos_D5 0;
BA_ "GenSigTimeoutTime_ORC" SG_ 213 DASEngReqPos_D5 0;
BA_ "GenSigTimeoutTime_MPAD" SG_ 213 LKA_LAT_CTRL_ResponseSts_D5 0;
BA_ "GenSigTimeoutTime_CVADAS" SG_ 213 LKA_LAT_CTRL_ResponseSts_D5 0;
BA_ "GenSigTimeoutTime_BSM" SG_ 213 LKA_LAT_CTRL_ResponseSts_D5 0;
BA_ "GenSigTimeoutTime_BSM2" SG_ 213 LKA_LAT_CTRL_ResponseSts_D5 0;
BA_ "GenSigTimeoutTime_EPS" SG_ 213 LKA_LAT_CTRL_ResponseSts_D5 0;
BA_ "GenSigTimeoutTime_EVCU2" SG_ 213 LKA_LAT_CTRL_ResponseSts_D5 0;
BA_ "GenSigTimeoutTime_ORC" SG_ 213 LKA_LAT_CTRL_ResponseSts_D5 0;
BA_ "GenSigTimeoutTime_MPAD" SG_ 213 RRCC_Cancel_Req_D5 0;
BA_ "GenSigTimeoutTime_CVADAS" SG_ 213 RRCC_Cancel_Req_D5 0;
BA_ "GenSigTimeoutTime_BSM" SG_ 213 RRCC_Cancel_Req_D5 0;
BA_ "GenSigTimeoutTime_BSM2" SG_ 213 RRCC_Cancel_Req_D5 0;
BA_ "GenSigTimeoutTime_EPS" SG_ 213 RRCC_Cancel_Req_D5 0;
BA_ "GenSigTimeoutTime_EVCU2" SG_ 213 RRCC_Cancel_Req_D5 0;
BA_ "GenSigTimeoutTime_ORC" SG_ 213 RRCC_Cancel_Req_D5 0;
BA_ "GenSigTimeoutTime_MPAD" SG_ 2654486701 CBV_bit0_RepeatMessageRequestBit_1E3840AD 0;
BA_ "GenSigTimeoutTime_ADCAM" SG_ 2654486701 CBV_bit0_RepeatMessageRequestBit_1E3840AD 0;
BA_ "GenSigTimeoutTime_CVADAS" SG_ 2654486701 CBV_bit0_RepeatMessageRequestBit_1E3840AD 0;
BA_ "GenSigTimeoutTime_BSM" SG_ 2654486701 CBV_bit0_RepeatMessageRequestBit_1E3840AD 0;
BA_ "GenSigTimeoutTime_BSM2" SG_ 2654486701 CBV_bit0_RepeatMessageRequestBit_1E3840AD 0;
BA_ "GenSigTimeoutTime_EPS" SG_ 2654486701 CBV_bit0_RepeatMessageRequestBit_1E3840AD 0;
BA_ "GenSigTimeoutTime_EVCU2" SG_ 2654486701 CBV_bit0_RepeatMessageRequestBit_1E3840AD 0;
BA_ "GenSigTimeoutTime_ORC" SG_ 2654486701 CBV_bit0_RepeatMessageRequestBit_1E3840AD 0;
BA_ "GenSigTimeoutTime_MPAD" SG_ 2654486701 CBV_bit3_NMCoordinatorBit_1E3840AD 0;
BA_ "GenSigTimeoutTime_ADCAM" SG_ 2654486701 CBV_bit3_NMCoordinatorBit_1E3840AD 0;
BA_ "GenSigTimeoutTime_CVADAS" SG_ 2654486701 CBV_bit3_NMCoordinatorBit_1E3840AD 0;
BA_ "GenSigTimeoutTime_BSM" SG_ 2654486701 CBV_bit3_NMCoordinatorBit_1E3840AD 0;
BA_ "GenSigTimeoutTime_BSM2" SG_ 2654486701 CBV_bit3_NMCoordinatorBit_1E3840AD 0;
BA_ "GenSigTimeoutTime_EPS" SG_ 2654486701 CBV_bit3_NMCoordinatorBit_1E3840AD 0;
BA_ "GenSigTimeoutTime_EVCU2" SG_ 2654486701 CBV_bit3_NMCoordinatorBit_1E3840AD 0;
BA_ "GenSigTimeoutTime_ORC" SG_ 2654486701 CBV_bit3_NMCoordinatorBit_1E3840AD 0;
BA_ "GenSigTimeoutTime_MPAD" SG_ 2654486701 CBV_bit4_ActiveWakeupBit_1E3840AD 0;
BA_ "GenSigTimeoutTime_ADCAM" SG_ 2654486701 CBV_bit4_ActiveWakeupBit_1E3840AD 0;
BA_ "GenSigTimeoutTime_CVADAS" SG_ 2654486701 CBV_bit4_ActiveWakeupBit_1E3840AD 0;
BA_ "GenSigTimeoutTime_BSM" SG_ 2654486701 CBV_bit4_ActiveWakeupBit_1E3840AD 0;
BA_ "GenSigTimeoutTime_BSM2" SG_ 2654486701 CBV_bit4_ActiveWakeupBit_1E3840AD 0;
BA_ "GenSigTimeoutTime_EPS" SG_ 2654486701 CBV_bit4_ActiveWakeupBit_1E3840AD 0;
BA_ "GenSigTimeoutTime_EVCU2" SG_ 2654486701 CBV_bit4_ActiveWakeupBit_1E3840AD 0;
BA_ "GenSigTimeoutTime_ORC" SG_ 2654486701 CBV_bit4_ActiveWakeupBit_1E3840AD 0;
BA_ "GenSigTimeoutTime_MPAD" SG_ 2654486701 CBV_bit6_PartialNtwInfBit_1E3840AD 0;
BA_ "GenSigTimeoutTime_ADCAM" SG_ 2654486701 CBV_bit6_PartialNtwInfBit_1E3840AD 0;
BA_ "GenSigTimeoutTime_CVADAS" SG_ 2654486701 CBV_bit6_PartialNtwInfBit_1E3840AD 0;
BA_ "GenSigTimeoutTime_BSM" SG_ 2654486701 CBV_bit6_PartialNtwInfBit_1E3840AD 0;
BA_ "GenSigTimeoutTime_BSM2" SG_ 2654486701 CBV_bit6_PartialNtwInfBit_1E3840AD 0;
BA_ "GenSigTimeoutTime_EPS" SG_ 2654486701 CBV_bit6_PartialNtwInfBit_1E3840AD 0;
BA_ "GenSigTimeoutTime_EVCU2" SG_ 2654486701 CBV_bit6_PartialNtwInfBit_1E3840AD 0;
BA_ "GenSigTimeoutTime_ORC" SG_ 2654486701 CBV_bit6_PartialNtwInfBit_1E3840AD 0;
BA_ "GenSigTimeoutTime_MPAD" SG_ 2654486701 CBV_bit1_1E3840AD 0;
BA_ "GenSigTimeoutTime_ADCAM" SG_ 2654486701 CBV_bit1_1E3840AD 0;
BA_ "GenSigTimeoutTime_CVADAS" SG_ 2654486701 CBV_bit1_1E3840AD 0;
BA_ "GenSigTimeoutTime_BSM" SG_ 2654486701 CBV_bit1_1E3840AD 0;
BA_ "GenSigTimeoutTime_BSM2" SG_ 2654486701 CBV_bit1_1E3840AD 0;
BA_ "GenSigTimeoutTime_EPS" SG_ 2654486701 CBV_bit1_1E3840AD 0;
BA_ "GenSigTimeoutTime_EVCU2" SG_ 2654486701 CBV_bit1_1E3840AD 0;
BA_ "GenSigTimeoutTime_ORC" SG_ 2654486701 CBV_bit1_1E3840AD 0;
BA_ "GenSigTimeoutTime_MPAD" SG_ 2654486701 CBV_bit2_1E3840AD 0;
BA_ "GenSigTimeoutTime_ADCAM" SG_ 2654486701 CBV_bit2_1E3840AD 0;
BA_ "GenSigTimeoutTime_CVADAS" SG_ 2654486701 CBV_bit2_1E3840AD 0;
BA_ "GenSigTimeoutTime_BSM" SG_ 2654486701 CBV_bit2_1E3840AD 0;
BA_ "GenSigTimeoutTime_BSM2" SG_ 2654486701 CBV_bit2_1E3840AD 0;
BA_ "GenSigTimeoutTime_EPS" SG_ 2654486701 CBV_bit2_1E3840AD 0;
BA_ "GenSigTimeoutTime_EVCU2" SG_ 2654486701 CBV_bit2_1E3840AD 0;
BA_ "GenSigTimeoutTime_ORC" SG_ 2654486701 CBV_bit2_1E3840AD 0;
BA_ "GenSigTimeoutTime_MPAD" SG_ 2654486701 CBV_bit5_1E3840AD 0;
BA_ "GenSigTimeoutTime_ADCAM" SG_ 2654486701 CBV_bit5_1E3840AD 0;
BA_ "GenSigTimeoutTime_CVADAS" SG_ 2654486701 CBV_bit5_1E3840AD 0;
BA_ "GenSigTimeoutTime_BSM" SG_ 2654486701 CBV_bit5_1E3840AD 0;
BA_ "GenSigTimeoutTime_BSM2" SG_ 2654486701 CBV_bit5_1E3840AD 0;
BA_ "GenSigTimeoutTime_EPS" SG_ 2654486701 CBV_bit5_1E3840AD 0;
BA_ "GenSigTimeoutTime_EVCU2" SG_ 2654486701 CBV_bit5_1E3840AD 0;
BA_ "GenSigTimeoutTime_ORC" SG_ 2654486701 CBV_bit5_1E3840AD 0;
BA_ "GenSigTimeoutTime_MPAD" SG_ 2654486701 CBV_bit7_1E3840AD 0;
BA_ "GenSigTimeoutTime_ADCAM" SG_ 2654486701 CBV_bit7_1E3840AD 0;
BA_ "GenSigTimeoutTime_CVADAS" SG_ 2654486701 CBV_bit7_1E3840AD 0;
BA_ "GenSigTimeoutTime_BSM" SG_ 2654486701 CBV_bit7_1E3840AD 0;
BA_ "GenSigTimeoutTime_BSM2" SG_ 2654486701 CBV_bit7_1E3840AD 0;
BA_ "GenSigTimeoutTime_EPS" SG_ 2654486701 CBV_bit7_1E3840AD 0;
BA_ "GenSigTimeoutTime_EVCU2" SG_ 2654486701 CBV_bit7_1E3840AD 0;
BA_ "GenSigTimeoutTime_ORC" SG_ 2654486701 CBV_bit7_1E3840AD 0;
BA_ "GenSigTimeoutTime_MPAD" SG_ 2654486701 SourceNodeIdentifier_1E3840AD 0;
BA_ "GenSigTimeoutTime_ADCAM" SG_ 2654486701 SourceNodeIdentifier_1E3840AD 0;
BA_ "GenSigTimeoutTime_CVADAS" SG_ 2654486701 SourceNodeIdentifier_1E3840AD 0;
BA_ "GenSigTimeoutTime_BSM" SG_ 2654486701 SourceNodeIdentifier_1E3840AD 0;
BA_ "GenSigTimeoutTime_BSM2" SG_ 2654486701 SourceNodeIdentifier_1E3840AD 0;
BA_ "GenSigTimeoutTime_EPS" SG_ 2654486701 SourceNodeIdentifier_1E3840AD 0;
BA_ "GenSigTimeoutTime_EVCU2" SG_ 2654486701 SourceNodeIdentifier_1E3840AD 0;
BA_ "GenSigTimeoutTime_ORC" SG_ 2654486701 SourceNodeIdentifier_1E3840AD 0;
BA_ "GenSigTimeoutTime_MPAD" SG_ 2654486689 CBV_bit0_RepeatMessageRequestBit_1E3840A1 0;
BA_ "GenSigTimeoutTime_BSM2" SG_ 2654486689 CBV_bit0_RepeatMessageRequestBit_1E3840A1 0;
BA_ "GenSigTimeoutTime_ADCAM" SG_ 2654486689 CBV_bit0_RepeatMessageRequestBit_1E3840A1 0;
BA_ "GenSigTimeoutTime_CVADAS" SG_ 2654486689 CBV_bit0_RepeatMessageRequestBit_1E3840A1 0;
BA_ "GenSigTimeoutTime_BSM" SG_ 2654486689 CBV_bit0_RepeatMessageRequestBit_1E3840A1 0;
BA_ "GenSigTimeoutTime_ECM" SG_ 2654486689 CBV_bit0_RepeatMessageRequestBit_1E3840A1 0;
BA_ "GenSigTimeoutTime_EPS" SG_ 2654486689 CBV_bit0_RepeatMessageRequestBit_1E3840A1 0;
BA_ "GenSigTimeoutTime_EVCU2" SG_ 2654486689 CBV_bit0_RepeatMessageRequestBit_1E3840A1 0;
BA_ "GenSigTimeoutTime_ORC" SG_ 2654486689 CBV_bit0_RepeatMessageRequestBit_1E3840A1 0;
BA_ "GenSigTimeoutTime_MPAD" SG_ 2654486689 CBV_bit3_NMCoordinatorBit_1E3840A1 0;
BA_ "GenSigTimeoutTime_BSM2" SG_ 2654486689 CBV_bit3_NMCoordinatorBit_1E3840A1 0;
BA_ "GenSigTimeoutTime_ADCAM" SG_ 2654486689 CBV_bit3_NMCoordinatorBit_1E3840A1 0;
BA_ "GenSigTimeoutTime_CVADAS" SG_ 2654486689 CBV_bit3_NMCoordinatorBit_1E3840A1 0;
BA_ "GenSigTimeoutTime_BSM" SG_ 2654486689 CBV_bit3_NMCoordinatorBit_1E3840A1 0;
BA_ "GenSigTimeoutTime_ECM" SG_ 2654486689 CBV_bit3_NMCoordinatorBit_1E3840A1 0;
BA_ "GenSigTimeoutTime_EPS" SG_ 2654486689 CBV_bit3_NMCoordinatorBit_1E3840A1 0;
BA_ "GenSigTimeoutTime_EVCU2" SG_ 2654486689 CBV_bit3_NMCoordinatorBit_1E3840A1 0;
BA_ "GenSigTimeoutTime_ORC" SG_ 2654486689 CBV_bit3_NMCoordinatorBit_1E3840A1 0;
BA_ "GenSigTimeoutTime_MPAD" SG_ 2654486689 CBV_bit4_ActiveWakeupBit_1E3840A1 0;
BA_ "GenSigTimeoutTime_BSM2" SG_ 2654486689 CBV_bit4_ActiveWakeupBit_1E3840A1 0;
BA_ "GenSigTimeoutTime_ADCAM" SG_ 2654486689 CBV_bit4_ActiveWakeupBit_1E3840A1 0;
BA_ "GenSigTimeoutTime_CVADAS" SG_ 2654486689 CBV_bit4_ActiveWakeupBit_1E3840A1 0;
BA_ "GenSigTimeoutTime_BSM" SG_ 2654486689 CBV_bit4_ActiveWakeupBit_1E3840A1 0;
BA_ "GenSigTimeoutTime_ECM" SG_ 2654486689 CBV_bit4_ActiveWakeupBit_1E3840A1 0;
BA_ "GenSigTimeoutTime_EPS" SG_ 2654486689 CBV_bit4_ActiveWakeupBit_1E3840A1 0;
BA_ "GenSigTimeoutTime_EVCU2" SG_ 2654486689 CBV_bit4_ActiveWakeupBit_1E3840A1 0;
BA_ "GenSigTimeoutTime_ORC" SG_ 2654486689 CBV_bit4_ActiveWakeupBit_1E3840A1 0;
BA_ "GenSigTimeoutTime_MPAD" SG_ 2654486689 CBV_bit6_PartialNtwInfBit_1E3840A1 0;
BA_ "GenSigTimeoutTime_BSM2" SG_ 2654486689 CBV_bit6_PartialNtwInfBit_1E3840A1 0;
BA_ "GenSigTimeoutTime_ADCAM" SG_ 2654486689 CBV_bit6_PartialNtwInfBit_1E3840A1 0;
BA_ "GenSigTimeoutTime_CVADAS" SG_ 2654486689 CBV_bit6_PartialNtwInfBit_1E3840A1 0;
BA_ "GenSigTimeoutTime_BSM" SG_ 2654486689 CBV_bit6_PartialNtwInfBit_1E3840A1 0;
BA_ "GenSigTimeoutTime_ECM" SG_ 2654486689 CBV_bit6_PartialNtwInfBit_1E3840A1 0;
BA_ "GenSigTimeoutTime_EPS" SG_ 2654486689 CBV_bit6_PartialNtwInfBit_1E3840A1 0;
BA_ "GenSigTimeoutTime_EVCU2" SG_ 2654486689 CBV_bit6_PartialNtwInfBit_1E3840A1 0;
BA_ "GenSigTimeoutTime_ORC" SG_ 2654486689 CBV_bit6_PartialNtwInfBit_1E3840A1 0;
BA_ "GenSigTimeoutTime_MPAD" SG_ 2654486689 CBV_bit1_1E3840A1 0;
BA_ "GenSigTimeoutTime_BSM2" SG_ 2654486689 CBV_bit1_1E3840A1 0;
BA_ "GenSigTimeoutTime_ADCAM" SG_ 2654486689 CBV_bit1_1E3840A1 0;
BA_ "GenSigTimeoutTime_CVADAS" SG_ 2654486689 CBV_bit1_1E3840A1 0;
BA_ "GenSigTimeoutTime_BSM" SG_ 2654486689 CBV_bit1_1E3840A1 0;
BA_ "GenSigTimeoutTime_ECM" SG_ 2654486689 CBV_bit1_1E3840A1 0;
BA_ "GenSigTimeoutTime_EPS" SG_ 2654486689 CBV_bit1_1E3840A1 0;
BA_ "GenSigTimeoutTime_EVCU2" SG_ 2654486689 CBV_bit1_1E3840A1 0;
BA_ "GenSigTimeoutTime_ORC" SG_ 2654486689 CBV_bit1_1E3840A1 0;
BA_ "GenSigTimeoutTime_MPAD" SG_ 2654486689 CBV_bit2_1E3840A1 0;
BA_ "GenSigTimeoutTime_BSM2" SG_ 2654486689 CBV_bit2_1E3840A1 0;
BA_ "GenSigTimeoutTime_ADCAM" SG_ 2654486689 CBV_bit2_1E3840A1 0;
BA_ "GenSigTimeoutTime_CVADAS" SG_ 2654486689 CBV_bit2_1E3840A1 0;
BA_ "GenSigTimeoutTime_BSM" SG_ 2654486689 CBV_bit2_1E3840A1 0;
BA_ "GenSigTimeoutTime_ECM" SG_ 2654486689 CBV_bit2_1E3840A1 0;
BA_ "GenSigTimeoutTime_EPS" SG_ 2654486689 CBV_bit2_1E3840A1 0;
BA_ "GenSigTimeoutTime_EVCU2" SG_ 2654486689 CBV_bit2_1E3840A1 0;
BA_ "GenSigTimeoutTime_ORC" SG_ 2654486689 CBV_bit2_1E3840A1 0;
BA_ "GenSigTimeoutTime_MPAD" SG_ 2654486689 CBV_bit5_1E3840A1 0;
BA_ "GenSigTimeoutTime_BSM2" SG_ 2654486689 CBV_bit5_1E3840A1 0;
BA_ "GenSigTimeoutTime_ADCAM" SG_ 2654486689 CBV_bit5_1E3840A1 0;
BA_ "GenSigTimeoutTime_CVADAS" SG_ 2654486689 CBV_bit5_1E3840A1 0;
BA_ "GenSigTimeoutTime_BSM" SG_ 2654486689 CBV_bit5_1E3840A1 0;
BA_ "GenSigTimeoutTime_ECM" SG_ 2654486689 CBV_bit5_1E3840A1 0;
BA_ "GenSigTimeoutTime_EPS" SG_ 2654486689 CBV_bit5_1E3840A1 0;
BA_ "GenSigTimeoutTime_EVCU2" SG_ 2654486689 CBV_bit5_1E3840A1 0;
BA_ "GenSigTimeoutTime_ORC" SG_ 2654486689 CBV_bit5_1E3840A1 0;
BA_ "GenSigTimeoutTime_MPAD" SG_ 2654486689 CBV_bit7_1E3840A1 0;
BA_ "GenSigTimeoutTime_BSM2" SG_ 2654486689 CBV_bit7_1E3840A1 0;
BA_ "GenSigTimeoutTime_ADCAM" SG_ 2654486689 CBV_bit7_1E3840A1 0;
BA_ "GenSigTimeoutTime_CVADAS" SG_ 2654486689 CBV_bit7_1E3840A1 0;
BA_ "GenSigTimeoutTime_BSM" SG_ 2654486689 CBV_bit7_1E3840A1 0;
BA_ "GenSigTimeoutTime_ECM" SG_ 2654486689 CBV_bit7_1E3840A1 0;
BA_ "GenSigTimeoutTime_EPS" SG_ 2654486689 CBV_bit7_1E3840A1 0;
BA_ "GenSigTimeoutTime_EVCU2" SG_ 2654486689 CBV_bit7_1E3840A1 0;
BA_ "GenSigTimeoutTime_ORC" SG_ 2654486689 CBV_bit7_1E3840A1 0;
BA_ "GenSigTimeoutTime_MPAD" SG_ 2654486689 SourceNodeIdentifier_1E3840A1 0;
BA_ "GenSigTimeoutTime_BSM2" SG_ 2654486689 SourceNodeIdentifier_1E3840A1 0;
BA_ "GenSigTimeoutTime_ADCAM" SG_ 2654486689 SourceNodeIdentifier_1E3840A1 0;
BA_ "GenSigTimeoutTime_CVADAS" SG_ 2654486689 SourceNodeIdentifier_1E3840A1 0;
BA_ "GenSigTimeoutTime_BSM" SG_ 2654486689 SourceNodeIdentifier_1E3840A1 0;
BA_ "GenSigTimeoutTime_ECM" SG_ 2654486689 SourceNodeIdentifier_1E3840A1 0;
BA_ "GenSigTimeoutTime_EPS" SG_ 2654486689 SourceNodeIdentifier_1E3840A1 0;
BA_ "GenSigTimeoutTime_EVCU2" SG_ 2654486689 SourceNodeIdentifier_1E3840A1 0;
BA_ "GenSigTimeoutTime_ORC" SG_ 2654486689 SourceNodeIdentifier_1E3840A1 0;
BA_ "GenSigTimeoutTime_MPAD" SG_ 204 Rear_Axle_Regen_Capacity 0;
BA_ "GenSigTimeoutTime_ADCAM" SG_ 204 Rear_Axle_Regen_Capacity 0;
BA_ "GenSigTimeoutTime_CVADAS" SG_ 204 Rear_Axle_Regen_Capacity 0;
BA_ "GenSigTimeoutTime_MPAD" SG_ 204 Rear_AxleTorque_Max 0;
BA_ "GenSigTimeoutTime_ADCAM" SG_ 204 Rear_AxleTorque_Max 0;
BA_ "GenSigTimeoutTime_CVADAS" SG_ 204 Rear_AxleTorque_Max 0;
BA_ "GenSigTimeoutTime_MPAD" SG_ 204 Rear_AxleTorque_Min 0;
BA_ "GenSigTimeoutTime_ADCAM" SG_ 204 Rear_AxleTorque_Min 0;
BA_ "GenSigTimeoutTime_CVADAS" SG_ 204 Rear_AxleTorque_Min 0;
BA_ "GenSigTimeoutTime_MPAD" SG_ 204 MessageCounter_AXLE_TORQUE_FD_1 0;
BA_ "GenSigTimeoutTime_ADCAM" SG_ 204 MessageCounter_AXLE_TORQUE_FD_1 0;
BA_ "GenSigTimeoutTime_CVADAS" SG_ 204 MessageCounter_AXLE_TORQUE_FD_1 0;
BA_ "GenSigTimeoutTime_MPAD" SG_ 204 CRC_AXLE_TORQUE_FD_1 0;
BA_ "GenSigTimeoutTime_ADCAM" SG_ 204 CRC_AXLE_TORQUE_FD_1 0;
BA_ "GenSigTimeoutTime_CVADAS" SG_ 204 CRC_AXLE_TORQUE_FD_1 0;
BA_ "GenSigTimeoutTime_MPAD" SG_ 204 Front_Axle_Est_Regen_Torq 0;
BA_ "GenSigTimeoutTime_ADCAM" SG_ 204 Front_Axle_Est_Regen_Torq 0;
BA_ "GenSigTimeoutTime_CVADAS" SG_ 204 Front_Axle_Est_Regen_Torq 0;
BA_ "GenSigTimeoutTime_MPAD" SG_ 204 Front_Axle_Regen_Capacity 0;
BA_ "GenSigTimeoutTime_ADCAM" SG_ 204 Front_Axle_Regen_Capacity 0;
BA_ "GenSigTimeoutTime_CVADAS" SG_ 204 Front_Axle_Regen_Capacity 0;
BA_ "GenSigTimeoutTime_MPAD" SG_ 204 Rear_Axle_Est_Regen_Torq 0;
BA_ "GenSigTimeoutTime_ADCAM" SG_ 204 Rear_Axle_Est_Regen_Torq 0;
BA_ "GenSigTimeoutTime_CVADAS" SG_ 204 Rear_Axle_Est_Regen_Torq 0;
BA_ "GenSigTimeoutTime_CVADAS" SG_ 204 Total_AxleTorque_Min 0;
BA_ "GenSigTimeoutTime_CVADAS" SG_ 204 Total_AxleTorque_Max 0;
BA_ "GenSigTimeoutTime_CVADAS" SG_ 204 Axle_TorqueStatic_D_TTC 0;
BA_ "GenSigTimeoutTime_EVCU2" SG_ 204 Axle_TorqueStatic_D_TTC 0;
BA_ "GenSigTimeoutTime_CVADAS" SG_ 204 Axle_Torque_DrvReqMod 0;
BA_ "GenSigTimeoutTime_MPAD" SG_ 204 Front_AxleTorque_Min 0;
BA_ "GenSigTimeoutTime_ADCAM" SG_ 204 Front_AxleTorque_Min 0;
BA_ "GenSigTimeoutTime_CVADAS" SG_ 204 Front_AxleTorque_Min 0;
BA_ "GenSigTimeoutTime_MPAD" SG_ 204 Front_AxleTorque_Max 0;
BA_ "GenSigTimeoutTime_ADCAM" SG_ 204 Front_AxleTorque_Max 0;
BA_ "GenSigTimeoutTime_CVADAS" SG_ 204 Front_AxleTorque_Max 0;
BA_ "GenSigTimeoutTime_BSM2" SG_ 204 Rear_Axle_Regen_Capacity 0;
BA_ "GenSigTimeoutTime_CADM" SG_ 204 Rear_Axle_Regen_Capacity 0;
BA_ "GenSigTimeoutTime_CVPAM" SG_ 204 Rear_Axle_Regen_Capacity 0;
BA_ "GenSigTimeoutTime_ECM" SG_ 204 Rear_Axle_Regen_Capacity 0;
BA_ "GenSigTimeoutTime_EPS" SG_ 204 Rear_Axle_Regen_Capacity 0;
BA_ "GenSigTimeoutTime_EVCU2" SG_ 204 Rear_Axle_Regen_Capacity 0;
BA_ "GenSigTimeoutTime_ORC" SG_ 204 Rear_Axle_Regen_Capacity 0;
BA_ "GenSigStartValue" SG_ 204 Rear_AxleTorque_Max 32767;
BA_ "GenSigTimeoutTime_BSM" SG_ 204 Rear_AxleTorque_Max 0;
BA_ "GenSigTimeoutTime_BSM2" SG_ 204 Rear_AxleTorque_Max 0;
BA_ "GenSigTimeoutTime_CADM" SG_ 204 Rear_AxleTorque_Max 0;
BA_ "GenSigTimeoutTime_CVPAM" SG_ 204 Rear_AxleTorque_Max 0;
BA_ "GenSigTimeoutTime_ECM" SG_ 204 Rear_AxleTorque_Max 0;
BA_ "GenSigTimeoutTime_EPS" SG_ 204 Rear_AxleTorque_Max 0;
BA_ "GenSigTimeoutTime_EVCU2" SG_ 204 Rear_AxleTorque_Max 0;
BA_ "GenSigTimeoutTime_ORC" SG_ 204 Rear_AxleTorque_Max 0;
BA_ "GenSigStartValue" SG_ 204 Rear_AxleTorque_Min 32767;
BA_ "GenSigTimeoutTime_BSM" SG_ 204 Rear_AxleTorque_Min 0;
BA_ "GenSigTimeoutTime_BSM2" SG_ 204 Rear_AxleTorque_Min 0;
BA_ "GenSigTimeoutTime_CADM" SG_ 204 Rear_AxleTorque_Min 0;
BA_ "GenSigTimeoutTime_CVPAM" SG_ 204 Rear_AxleTorque_Min 0;
BA_ "GenSigTimeoutTime_ECM" SG_ 204 Rear_AxleTorque_Min 0;
BA_ "GenSigTimeoutTime_EPS" SG_ 204 Rear_AxleTorque_Min 0;
BA_ "GenSigTimeoutTime_EVCU2" SG_ 204 Rear_AxleTorque_Min 0;
BA_ "GenSigTimeoutTime_ORC" SG_ 204 Rear_AxleTorque_Min 0;
BA_ "GenSigTimeoutTime_BSM" SG_ 204 MessageCounter_AXLE_TORQUE_FD_1 0;
BA_ "GenSigTimeoutTime_BSM2" SG_ 204 MessageCounter_AXLE_TORQUE_FD_1 0;
BA_ "GenSigTimeoutTime_CADM" SG_ 204 MessageCounter_AXLE_TORQUE_FD_1 0;
BA_ "GenSigTimeoutTime_CVPAM" SG_ 204 MessageCounter_AXLE_TORQUE_FD_1 0;
BA_ "GenSigTimeoutTime_ECM" SG_ 204 MessageCounter_AXLE_TORQUE_FD_1 0;
BA_ "GenSigTimeoutTime_EPS" SG_ 204 MessageCounter_AXLE_TORQUE_FD_1 0;
BA_ "GenSigTimeoutTime_EVCU2" SG_ 204 MessageCounter_AXLE_TORQUE_FD_1 0;
BA_ "GenSigTimeoutTime_ORC" SG_ 204 MessageCounter_AXLE_TORQUE_FD_1 0;
BA_ "GenSigTimeoutTime_BSM" SG_ 204 CRC_AXLE_TORQUE_FD_1 0;
BA_ "GenSigTimeoutTime_BSM2" SG_ 204 CRC_AXLE_TORQUE_FD_1 0;
BA_ "GenSigTimeoutTime_CADM" SG_ 204 CRC_AXLE_TORQUE_FD_1 0;
BA_ "GenSigTimeoutTime_CVPAM" SG_ 204 CRC_AXLE_TORQUE_FD_1 0;
BA_ "GenSigTimeoutTime_ECM" SG_ 204 CRC_AXLE_TORQUE_FD_1 0;
BA_ "GenSigTimeoutTime_EPS" SG_ 204 CRC_AXLE_TORQUE_FD_1 0;
BA_ "GenSigTimeoutTime_EVCU2" SG_ 204 CRC_AXLE_TORQUE_FD_1 0;
BA_ "GenSigTimeoutTime_ORC" SG_ 204 CRC_AXLE_TORQUE_FD_1 0;
BA_ "GenSigTimeoutTime_BSM2" SG_ 204 Front_Axle_Est_Regen_Torq 0;
BA_ "GenSigTimeoutTime_CADM" SG_ 204 Front_Axle_Est_Regen_Torq 0;
BA_ "GenSigTimeoutTime_CVPAM" SG_ 204 Front_Axle_Est_Regen_Torq 0;
BA_ "GenSigTimeoutTime_ECM" SG_ 204 Front_Axle_Est_Regen_Torq 0;
BA_ "GenSigTimeoutTime_EPS" SG_ 204 Front_Axle_Est_Regen_Torq 0;
BA_ "GenSigTimeoutTime_EVCU2" SG_ 204 Front_Axle_Est_Regen_Torq 0;
BA_ "GenSigTimeoutTime_ORC" SG_ 204 Front_Axle_Est_Regen_Torq 0;
BA_ "GenSigTimeoutTime_BSM2" SG_ 204 Front_Axle_Regen_Capacity 0;
BA_ "GenSigTimeoutTime_CADM" SG_ 204 Front_Axle_Regen_Capacity 0;
BA_ "GenSigTimeoutTime_CVPAM" SG_ 204 Front_Axle_Regen_Capacity 0;
BA_ "GenSigTimeoutTime_ECM" SG_ 204 Front_Axle_Regen_Capacity 0;
BA_ "GenSigTimeoutTime_EPS" SG_ 204 Front_Axle_Regen_Capacity 0;
BA_ "GenSigTimeoutTime_EVCU2" SG_ 204 Front_Axle_Regen_Capacity 0;
BA_ "GenSigTimeoutTime_ORC" SG_ 204 Front_Axle_Regen_Capacity 0;
BA_ "GenSigTimeoutTime_BSM2" SG_ 204 Rear_Axle_Est_Regen_Torq 0;
BA_ "GenSigTimeoutTime_CADM" SG_ 204 Rear_Axle_Est_Regen_Torq 0;
BA_ "GenSigTimeoutTime_CVPAM" SG_ 204 Rear_Axle_Est_Regen_Torq 0;
BA_ "GenSigTimeoutTime_ECM" SG_ 204 Rear_Axle_Est_Regen_Torq 0;
BA_ "GenSigTimeoutTime_EPS" SG_ 204 Rear_Axle_Est_Regen_Torq 0;
BA_ "GenSigTimeoutTime_EVCU2" SG_ 204 Rear_Axle_Est_Regen_Torq 0;
BA_ "GenSigTimeoutTime_ORC" SG_ 204 Rear_Axle_Est_Regen_Torq 0;
BA_ "GenSigStartValue" SG_ 204 Total_AxleTorque_Min 32767;
BA_ "GenSigTimeoutTime_BSM" SG_ 204 Total_AxleTorque_Min 0;
BA_ "GenSigTimeoutTime_BSM2" SG_ 204 Total_AxleTorque_Min 0;
BA_ "GenSigTimeoutTime_CVPAM" SG_ 204 Total_AxleTorque_Min 0;
BA_ "GenSigTimeoutTime_ECM" SG_ 204 Total_AxleTorque_Min 0;
BA_ "GenSigTimeoutTime_EPS" SG_ 204 Total_AxleTorque_Min 0;
BA_ "GenSigTimeoutTime_EVCU2" SG_ 204 Total_AxleTorque_Min 0;
BA_ "GenSigTimeoutTime_ORC" SG_ 204 Total_AxleTorque_Min 0;
BA_ "GenSigStartValue" SG_ 204 Total_AxleTorque_Max 32767;
BA_ "GenSigTimeoutTime_BSM" SG_ 204 Total_AxleTorque_Max 0;
BA_ "GenSigTimeoutTime_BSM2" SG_ 204 Total_AxleTorque_Max 0;
BA_ "GenSigTimeoutTime_CVPAM" SG_ 204 Total_AxleTorque_Max 0;
BA_ "GenSigTimeoutTime_ECM" SG_ 204 Total_AxleTorque_Max 0;
BA_ "GenSigTimeoutTime_EPS" SG_ 204 Total_AxleTorque_Max 0;
BA_ "GenSigTimeoutTime_EVCU2" SG_ 204 Total_AxleTorque_Max 0;
BA_ "GenSigTimeoutTime_ORC" SG_ 204 Total_AxleTorque_Max 0;
BA_ "GenSigStartValue" SG_ 204 Axle_TorqueStatic_D_TTC 32767;
BA_ "GenSigTimeoutTime_BSM" SG_ 204 Axle_TorqueStatic_D_TTC 0;
BA_ "GenSigTimeoutTime_BSM2" SG_ 204 Axle_TorqueStatic_D_TTC 0;
BA_ "GenSigTimeoutTime_CVPAM" SG_ 204 Axle_TorqueStatic_D_TTC 0;
BA_ "GenSigTimeoutTime_ECM" SG_ 204 Axle_TorqueStatic_D_TTC 0;
BA_ "GenSigTimeoutTime_EPS" SG_ 204 Axle_TorqueStatic_D_TTC 0;
BA_ "GenSigTimeoutTime_ORC" SG_ 204 Axle_TorqueStatic_D_TTC 0;
BA_ "GenSigStartValue" SG_ 204 Axle_Torque_DrvReqMod 32768;
BA_ "GenSigTimeoutTime_BSM" SG_ 204 Axle_Torque_DrvReqMod 0;
BA_ "GenSigTimeoutTime_BSM2" SG_ 204 Axle_Torque_DrvReqMod 0;
BA_ "GenSigTimeoutTime_CVPAM" SG_ 204 Axle_Torque_DrvReqMod 0;
BA_ "GenSigTimeoutTime_ECM" SG_ 204 Axle_Torque_DrvReqMod 0;
BA_ "GenSigTimeoutTime_EPS" SG_ 204 Axle_Torque_DrvReqMod 0;
BA_ "GenSigTimeoutTime_EVCU2" SG_ 204 Axle_Torque_DrvReqMod 0;
BA_ "GenSigTimeoutTime_ORC" SG_ 204 Axle_Torque_DrvReqMod 0;
BA_ "GenSigStartValue" SG_ 204 Front_AxleTorque_Min 32767;
BA_ "GenSigTimeoutTime_BSM" SG_ 204 Front_AxleTorque_Min 0;
BA_ "GenSigTimeoutTime_BSM2" SG_ 204 Front_AxleTorque_Min 0;
BA_ "GenSigTimeoutTime_CADM" SG_ 204 Front_AxleTorque_Min 0;
BA_ "GenSigTimeoutTime_CVPAM" SG_ 204 Front_AxleTorque_Min 0;
BA_ "GenSigTimeoutTime_ECM" SG_ 204 Front_AxleTorque_Min 0;
BA_ "GenSigTimeoutTime_EPS" SG_ 204 Front_AxleTorque_Min 0;
BA_ "GenSigTimeoutTime_EVCU2" SG_ 204 Front_AxleTorque_Min 0;
BA_ "GenSigTimeoutTime_ORC" SG_ 204 Front_AxleTorque_Min 0;
BA_ "GenSigStartValue" SG_ 204 Front_AxleTorque_Max 32767;
BA_ "GenSigTimeoutTime_BSM" SG_ 204 Front_AxleTorque_Max 0;
BA_ "GenSigTimeoutTime_BSM2" SG_ 204 Front_AxleTorque_Max 0;
BA_ "GenSigTimeoutTime_CADM" SG_ 204 Front_AxleTorque_Max 0;
BA_ "GenSigTimeoutTime_CVPAM" SG_ 204 Front_AxleTorque_Max 0;
BA_ "GenSigTimeoutTime_ECM" SG_ 204 Front_AxleTorque_Max 0;
BA_ "GenSigTimeoutTime_EPS" SG_ 204 Front_AxleTorque_Max 0;
BA_ "GenSigTimeoutTime_EVCU2" SG_ 204 Front_AxleTorque_Max 0;
BA_ "GenSigTimeoutTime_ORC" SG_ 204 Front_AxleTorque_Max 0;
BA_ "GenSigTimeoutTime_MPAD" SG_ 2654486554 CBV_bit0_RepeatMessageRequestBit_1E38401A 0;
BA_ "GenSigTimeoutTime_ADCAM" SG_ 2654486554 CBV_bit0_RepeatMessageRequestBit_1E38401A 0;
BA_ "GenSigTimeoutTime_CVADAS" SG_ 2654486554 CBV_bit0_RepeatMessageRequestBit_1E38401A 0;
BA_ "GenSigTimeoutTime_MPAD" SG_ 2654486554 CBV_bit1_1E38401A 0;
BA_ "GenSigTimeoutTime_ADCAM" SG_ 2654486554 CBV_bit1_1E38401A 0;
BA_ "GenSigTimeoutTime_CVADAS" SG_ 2654486554 CBV_bit1_1E38401A 0;
BA_ "GenSigTimeoutTime_MPAD" SG_ 2654486554 CBV_bit2_1E38401A 0;
BA_ "GenSigTimeoutTime_ADCAM" SG_ 2654486554 CBV_bit2_1E38401A 0;
BA_ "GenSigTimeoutTime_CVADAS" SG_ 2654486554 CBV_bit2_1E38401A 0;
BA_ "GenSigTimeoutTime_MPAD" SG_ 2654486554 CBV_bit3_NMCoordinatorBit_1E38401A 0;
BA_ "GenSigTimeoutTime_ADCAM" SG_ 2654486554 CBV_bit3_NMCoordinatorBit_1E38401A 0;
BA_ "GenSigTimeoutTime_CVADAS" SG_ 2654486554 CBV_bit3_NMCoordinatorBit_1E38401A 0;
BA_ "GenSigTimeoutTime_MPAD" SG_ 2654486554 CBV_bit4_ActiveWakeupBit_1E38401A 0;
BA_ "GenSigTimeoutTime_ADCAM" SG_ 2654486554 CBV_bit4_ActiveWakeupBit_1E38401A 0;
BA_ "GenSigTimeoutTime_CVADAS" SG_ 2654486554 CBV_bit4_ActiveWakeupBit_1E38401A 0;
BA_ "GenSigTimeoutTime_MPAD" SG_ 2654486554 CBV_bit5_1E38401A 0;
BA_ "GenSigTimeoutTime_ADCAM" SG_ 2654486554 CBV_bit5_1E38401A 0;
BA_ "GenSigTimeoutTime_CVADAS" SG_ 2654486554 CBV_bit5_1E38401A 0;
BA_ "GenSigTimeoutTime_MPAD" SG_ 2654486554 CBV_bit6_PartialNtwInfBit_1E38401A 0;
BA_ "GenSigTimeoutTime_ADCAM" SG_ 2654486554 CBV_bit6_PartialNtwInfBit_1E38401A 0;
BA_ "GenSigTimeoutTime_CVADAS" SG_ 2654486554 CBV_bit6_PartialNtwInfBit_1E38401A 0;
BA_ "GenSigTimeoutTime_MPAD" SG_ 2654486554 CBV_bit7_1E38401A 0;
BA_ "GenSigTimeoutTime_ADCAM" SG_ 2654486554 CBV_bit7_1E38401A 0;
BA_ "GenSigTimeoutTime_CVADAS" SG_ 2654486554 CBV_bit7_1E38401A 0;
BA_ "GenSigTimeoutTime_MPAD" SG_ 2654486554 SourceNodeIdentifier_1E38401A 0;
BA_ "GenSigTimeoutTime_ADCAM" SG_ 2654486554 SourceNodeIdentifier_1E38401A 0;
BA_ "GenSigTimeoutTime_CVADAS" SG_ 2654486554 SourceNodeIdentifier_1E38401A 0;
BA_ "GenSigTimeoutTime_BSM" SG_ 2654486554 CBV_bit0_RepeatMessageRequestBit_1E38401A 0;
BA_ "GenSigTimeoutTime_BSM2" SG_ 2654486554 CBV_bit0_RepeatMessageRequestBit_1E38401A 0;
BA_ "GenSigTimeoutTime_CADM" SG_ 2654486554 CBV_bit0_RepeatMessageRequestBit_1E38401A 0;
BA_ "GenSigTimeoutTime_CVPAM" SG_ 2654486554 CBV_bit0_RepeatMessageRequestBit_1E38401A 0;
BA_ "GenSigTimeoutTime_ECM" SG_ 2654486554 CBV_bit0_RepeatMessageRequestBit_1E38401A 0;
BA_ "GenSigTimeoutTime_EPS" SG_ 2654486554 CBV_bit0_RepeatMessageRequestBit_1E38401A 0;
BA_ "GenSigTimeoutTime_EVCU2" SG_ 2654486554 CBV_bit0_RepeatMessageRequestBit_1E38401A 0;
BA_ "GenSigTimeoutTime_ORC" SG_ 2654486554 CBV_bit0_RepeatMessageRequestBit_1E38401A 0;
BA_ "GenSigTimeoutTime_BSM" SG_ 2654486554 CBV_bit1_1E38401A 0;
BA_ "GenSigTimeoutTime_BSM2" SG_ 2654486554 CBV_bit1_1E38401A 0;
BA_ "GenSigTimeoutTime_CADM" SG_ 2654486554 CBV_bit1_1E38401A 0;
BA_ "GenSigTimeoutTime_CVPAM" SG_ 2654486554 CBV_bit1_1E38401A 0;
BA_ "GenSigTimeoutTime_ECM" SG_ 2654486554 CBV_bit1_1E38401A 0;
BA_ "GenSigTimeoutTime_EPS" SG_ 2654486554 CBV_bit1_1E38401A 0;
BA_ "GenSigTimeoutTime_EVCU2" SG_ 2654486554 CBV_bit1_1E38401A 0;
BA_ "GenSigTimeoutTime_ORC" SG_ 2654486554 CBV_bit1_1E38401A 0;
BA_ "GenSigTimeoutTime_BSM" SG_ 2654486554 CBV_bit2_1E38401A 0;
BA_ "GenSigTimeoutTime_BSM2" SG_ 2654486554 CBV_bit2_1E38401A 0;
BA_ "GenSigTimeoutTime_CADM" SG_ 2654486554 CBV_bit2_1E38401A 0;
BA_ "GenSigTimeoutTime_CVPAM" SG_ 2654486554 CBV_bit2_1E38401A 0;
BA_ "GenSigTimeoutTime_ECM" SG_ 2654486554 CBV_bit2_1E38401A 0;
BA_ "GenSigTimeoutTime_EPS" SG_ 2654486554 CBV_bit2_1E38401A 0;
BA_ "GenSigTimeoutTime_EVCU2" SG_ 2654486554 CBV_bit2_1E38401A 0;
BA_ "GenSigTimeoutTime_ORC" SG_ 2654486554 CBV_bit2_1E38401A 0;
BA_ "GenSigTimeoutTime_BSM" SG_ 2654486554 CBV_bit3_NMCoordinatorBit_1E38401A 0;
BA_ "GenSigTimeoutTime_BSM2" SG_ 2654486554 CBV_bit3_NMCoordinatorBit_1E38401A 0;
BA_ "GenSigTimeoutTime_CADM" SG_ 2654486554 CBV_bit3_NMCoordinatorBit_1E38401A 0;
BA_ "GenSigTimeoutTime_CVPAM" SG_ 2654486554 CBV_bit3_NMCoordinatorBit_1E38401A 0;
BA_ "GenSigTimeoutTime_ECM" SG_ 2654486554 CBV_bit3_NMCoordinatorBit_1E38401A 0;
BA_ "GenSigTimeoutTime_EPS" SG_ 2654486554 CBV_bit3_NMCoordinatorBit_1E38401A 0;
BA_ "GenSigTimeoutTime_EVCU2" SG_ 2654486554 CBV_bit3_NMCoordinatorBit_1E38401A 0;
BA_ "GenSigTimeoutTime_ORC" SG_ 2654486554 CBV_bit3_NMCoordinatorBit_1E38401A 0;
BA_ "GenSigTimeoutTime_BSM" SG_ 2654486554 CBV_bit4_ActiveWakeupBit_1E38401A 0;
BA_ "GenSigTimeoutTime_BSM2" SG_ 2654486554 CBV_bit4_ActiveWakeupBit_1E38401A 0;
BA_ "GenSigTimeoutTime_CADM" SG_ 2654486554 CBV_bit4_ActiveWakeupBit_1E38401A 0;
BA_ "GenSigTimeoutTime_CVPAM" SG_ 2654486554 CBV_bit4_ActiveWakeupBit_1E38401A 0;
BA_ "GenSigTimeoutTime_ECM" SG_ 2654486554 CBV_bit4_ActiveWakeupBit_1E38401A 0;
BA_ "GenSigTimeoutTime_EPS" SG_ 2654486554 CBV_bit4_ActiveWakeupBit_1E38401A 0;
BA_ "GenSigTimeoutTime_EVCU2" SG_ 2654486554 CBV_bit4_ActiveWakeupBit_1E38401A 0;
BA_ "GenSigTimeoutTime_ORC" SG_ 2654486554 CBV_bit4_ActiveWakeupBit_1E38401A 0;
BA_ "GenSigTimeoutTime_BSM" SG_ 2654486554 CBV_bit5_1E38401A 0;
BA_ "GenSigTimeoutTime_BSM2" SG_ 2654486554 CBV_bit5_1E38401A 0;
BA_ "GenSigTimeoutTime_CADM" SG_ 2654486554 CBV_bit5_1E38401A 0;
BA_ "GenSigTimeoutTime_CVPAM" SG_ 2654486554 CBV_bit5_1E38401A 0;
BA_ "GenSigTimeoutTime_ECM" SG_ 2654486554 CBV_bit5_1E38401A 0;
BA_ "GenSigTimeoutTime_EPS" SG_ 2654486554 CBV_bit5_1E38401A 0;
BA_ "GenSigTimeoutTime_EVCU2" SG_ 2654486554 CBV_bit5_1E38401A 0;
BA_ "GenSigTimeoutTime_ORC" SG_ 2654486554 CBV_bit5_1E38401A 0;
BA_ "GenSigTimeoutTime_BSM" SG_ 2654486554 CBV_bit6_PartialNtwInfBit_1E38401A 0;
BA_ "GenSigTimeoutTime_BSM2" SG_ 2654486554 CBV_bit6_PartialNtwInfBit_1E38401A 0;
BA_ "GenSigTimeoutTime_CADM" SG_ 2654486554 CBV_bit6_PartialNtwInfBit_1E38401A 0;
BA_ "GenSigTimeoutTime_CVPAM" SG_ 2654486554 CBV_bit6_PartialNtwInfBit_1E38401A 0;
BA_ "GenSigTimeoutTime_ECM" SG_ 2654486554 CBV_bit6_PartialNtwInfBit_1E38401A 0;
BA_ "GenSigTimeoutTime_EPS" SG_ 2654486554 CBV_bit6_PartialNtwInfBit_1E38401A 0;
BA_ "GenSigTimeoutTime_EVCU2" SG_ 2654486554 CBV_bit6_PartialNtwInfBit_1E38401A 0;
BA_ "GenSigTimeoutTime_ORC" SG_ 2654486554 CBV_bit6_PartialNtwInfBit_1E38401A 0;
BA_ "GenSigTimeoutTime_BSM" SG_ 2654486554 CBV_bit7_1E38401A 0;
BA_ "GenSigTimeoutTime_BSM2" SG_ 2654486554 CBV_bit7_1E38401A 0;
BA_ "GenSigTimeoutTime_CADM" SG_ 2654486554 CBV_bit7_1E38401A 0;
BA_ "GenSigTimeoutTime_CVPAM" SG_ 2654486554 CBV_bit7_1E38401A 0;
BA_ "GenSigTimeoutTime_ECM" SG_ 2654486554 CBV_bit7_1E38401A 0;
BA_ "GenSigTimeoutTime_EPS" SG_ 2654486554 CBV_bit7_1E38401A 0;
BA_ "GenSigTimeoutTime_EVCU2" SG_ 2654486554 CBV_bit7_1E38401A 0;
BA_ "GenSigTimeoutTime_ORC" SG_ 2654486554 CBV_bit7_1E38401A 0;
BA_ "GenSigTimeoutTime_BSM" SG_ 2654486554 SourceNodeIdentifier_1E38401A 0;
BA_ "GenSigTimeoutTime_BSM2" SG_ 2654486554 SourceNodeIdentifier_1E38401A 0;
BA_ "GenSigTimeoutTime_CADM" SG_ 2654486554 SourceNodeIdentifier_1E38401A 0;
BA_ "GenSigTimeoutTime_CVPAM" SG_ 2654486554 SourceNodeIdentifier_1E38401A 0;
BA_ "GenSigTimeoutTime_ECM" SG_ 2654486554 SourceNodeIdentifier_1E38401A 0;
BA_ "GenSigTimeoutTime_EPS" SG_ 2654486554 SourceNodeIdentifier_1E38401A 0;
BA_ "GenSigTimeoutTime_EVCU2" SG_ 2654486554 SourceNodeIdentifier_1E38401A 0;
BA_ "GenSigTimeoutTime_ORC" SG_ 2654486554 SourceNodeIdentifier_1E38401A 0;
BA_ "GenSigTimeoutTime_ADCAM" SG_ 205 CRC_BRAKE_FD_6 0;
BA_ "GenSigTimeoutTime_CVADAS" SG_ 205 CRC_BRAKE_FD_6 0;
BA_ "GenSigTimeoutTime_ADCAM" SG_ 205 MessageCounter_BRAKE_FD_6 0;
BA_ "GenSigTimeoutTime_CVADAS" SG_ 205 MessageCounter_BRAKE_FD_6 0;
BA_ "GenSigTimeoutTime_MPAD" SG_ 205 FrontAxle_Min_Rq_BSM 0;
BA_ "GenSigTimeoutTime_ADCAM" SG_ 205 FrontAxle_Min_Rq_BSM 0;
BA_ "GenSigTimeoutTime_CVADAS" SG_ 205 FrontAxle_Min_Rq_BSM 0;
BA_ "GenSigTimeoutTime_MPAD" SG_ 205 FrontAxle_Max_Rq_BSM 0;
BA_ "GenSigTimeoutTime_ADCAM" SG_ 205 FrontAxle_Max_Rq_BSM 0;
BA_ "GenSigTimeoutTime_CVADAS" SG_ 205 FrontAxle_Max_Rq_BSM 0;
BA_ "GenSigTimeoutTime_MPAD" SG_ 205 TotalAxle_Min_Rq_BSM 0;
BA_ "GenSigTimeoutTime_ADCAM" SG_ 205 TotalAxle_Min_Rq_BSM 0;
BA_ "GenSigTimeoutTime_CVADAS" SG_ 205 TotalAxle_Min_Rq_BSM 0;
BA_ "GenSigTimeoutTime_ADCAM" SG_ 205 TotalAxle_Max_Rq_BSM 0;
BA_ "GenSigTimeoutTime_CVADAS" SG_ 205 TotalAxle_Max_Rq_BSM 0;
BA_ "GenSigTimeoutTime_MPAD" SG_ 205 RearAxle_Max_Rq_BSM 0;
BA_ "GenSigTimeoutTime_ADCAM" SG_ 205 RearAxle_Max_Rq_BSM 0;
BA_ "GenSigTimeoutTime_CVADAS" SG_ 205 RearAxle_Max_Rq_BSM 0;
BA_ "GenSigTimeoutTime_MPAD" SG_ 205 RearAxle_Min_Rq_BSM 0;
BA_ "GenSigTimeoutTime_ADCAM" SG_ 205 RearAxle_Min_Rq_BSM 0;
BA_ "GenSigTimeoutTime_CVADAS" SG_ 205 RearAxle_Min_Rq_BSM 0;
BA_ "GenSigTimeoutTime_MPAD" SG_ 205 RearAxle_Rq_BSM 0;
BA_ "GenSigTimeoutTime_ADCAM" SG_ 205 RearAxle_Rq_BSM 0;
BA_ "GenSigTimeoutTime_CVADAS" SG_ 205 RearAxle_Rq_BSM 0;
BA_ "GenSigTimeoutTime_MPAD" SG_ 205 DrvrIntd_TotalBrk_AxleTorq 0;
BA_ "GenSigTimeoutTime_ADCAM" SG_ 205 DrvrIntd_TotalBrk_AxleTorq 0;
BA_ "GenSigTimeoutTime_CVADAS" SG_ 205 DrvrIntd_TotalBrk_AxleTorq 0;
BA_ "GenSigTimeoutTime_MPAD" SG_ 205 DriverReq_AxleTrq_Enabled_BSM 0;
BA_ "GenSigTimeoutTime_ADCAM" SG_ 205 DriverReq_AxleTrq_Enabled_BSM 0;
BA_ "GenSigTimeoutTime_CVADAS" SG_ 205 DriverReq_AxleTrq_Enabled_BSM 0;
BA_ "GenSigTimeoutTime_MPAD" SG_ 205 Cmnd_TotBrkFrict_AxleTorq 0;
BA_ "GenSigTimeoutTime_ADCAM" SG_ 205 Cmnd_TotBrkFrict_AxleTorq 0;
BA_ "GenSigTimeoutTime_CVADAS" SG_ 205 Cmnd_TotBrkFrict_AxleTorq 0;
BA_ "GenSigTimeoutTime_MPAD" SG_ 205 TotalAxle_Rq_BSM 0;
BA_ "GenSigTimeoutTime_ADCAM" SG_ 205 TotalAxle_Rq_BSM 0;
BA_ "GenSigTimeoutTime_CVADAS" SG_ 205 TotalAxle_Rq_BSM 0;
BA_ "GenSigTimeoutTime_MPAD" SG_ 205 DriverRequested_AxleTrq_BSM 0;
BA_ "GenSigTimeoutTime_ADCAM" SG_ 205 DriverRequested_AxleTrq_BSM 0;
BA_ "GenSigTimeoutTime_CVADAS" SG_ 205 DriverRequested_AxleTrq_BSM 0;
BA_ "GenSigTimeoutTime_MPAD" SG_ 205 FrontAxle_Rq_BSM 0;
BA_ "GenSigTimeoutTime_ADCAM" SG_ 205 FrontAxle_Rq_BSM 0;
BA_ "GenSigTimeoutTime_CVADAS" SG_ 205 FrontAxle_Rq_BSM 0;
BA_ "GenSigTimeoutTime_BSM" SG_ 205 CRC_BRAKE_FD_6 0;
BA_ "GenSigTimeoutTime_BSM2" SG_ 205 CRC_BRAKE_FD_6 0;
BA_ "GenSigTimeoutTime_CADM" SG_ 205 CRC_BRAKE_FD_6 0;
BA_ "GenSigTimeoutTime_CVPAM" SG_ 205 CRC_BRAKE_FD_6 0;
BA_ "GenSigTimeoutTime_EPS" SG_ 205 CRC_BRAKE_FD_6 0;
BA_ "GenSigTimeoutTime_ORC" SG_ 205 CRC_BRAKE_FD_6 0;
BA_ "GenSigTimeoutTime_BSM" SG_ 205 MessageCounter_BRAKE_FD_6 0;
BA_ "GenSigTimeoutTime_BSM2" SG_ 205 MessageCounter_BRAKE_FD_6 0;
BA_ "GenSigTimeoutTime_CADM" SG_ 205 MessageCounter_BRAKE_FD_6 0;
BA_ "GenSigTimeoutTime_CVPAM" SG_ 205 MessageCounter_BRAKE_FD_6 0;
BA_ "GenSigTimeoutTime_EPS" SG_ 205 MessageCounter_BRAKE_FD_6 0;
BA_ "GenSigTimeoutTime_ORC" SG_ 205 MessageCounter_BRAKE_FD_6 0;
BA_ "GenSigTimeoutTime_BSM" SG_ 205 FrontAxle_Min_Rq_BSM 0;
BA_ "GenSigTimeoutTime_BSM2" SG_ 205 FrontAxle_Min_Rq_BSM 0;
BA_ "GenSigTimeoutTime_CADM" SG_ 205 FrontAxle_Min_Rq_BSM 0;
BA_ "GenSigTimeoutTime_CVPAM" SG_ 205 FrontAxle_Min_Rq_BSM 0;
BA_ "GenSigTimeoutTime_ECM" SG_ 205 FrontAxle_Min_Rq_BSM 0;
BA_ "GenSigTimeoutTime_EPS" SG_ 205 FrontAxle_Min_Rq_BSM 0;
BA_ "GenSigTimeoutTime_ORC" SG_ 205 FrontAxle_Min_Rq_BSM 0;
BA_ "GenSigTimeoutTime_BSM" SG_ 205 FrontAxle_Max_Rq_BSM 0;
BA_ "GenSigTimeoutTime_BSM2" SG_ 205 FrontAxle_Max_Rq_BSM 0;
BA_ "GenSigTimeoutTime_CADM" SG_ 205 FrontAxle_Max_Rq_BSM 0;
BA_ "GenSigTimeoutTime_CVPAM" SG_ 205 FrontAxle_Max_Rq_BSM 0;
BA_ "GenSigTimeoutTime_ECM" SG_ 205 FrontAxle_Max_Rq_BSM 0;
BA_ "GenSigTimeoutTime_EPS" SG_ 205 FrontAxle_Max_Rq_BSM 0;
BA_ "GenSigTimeoutTime_ORC" SG_ 205 FrontAxle_Max_Rq_BSM 0;
BA_ "GenSigTimeoutTime_BSM" SG_ 205 TotalAxle_Min_Rq_BSM 0;
BA_ "GenSigTimeoutTime_BSM2" SG_ 205 TotalAxle_Min_Rq_BSM 0;
BA_ "GenSigTimeoutTime_CADM" SG_ 205 TotalAxle_Min_Rq_BSM 0;
BA_ "GenSigTimeoutTime_CVPAM" SG_ 205 TotalAxle_Min_Rq_BSM 0;
BA_ "GenSigTimeoutTime_EPS" SG_ 205 TotalAxle_Min_Rq_BSM 0;
BA_ "GenSigTimeoutTime_EVCU2" SG_ 205 TotalAxle_Min_Rq_BSM 0;
BA_ "GenSigTimeoutTime_ORC" SG_ 205 TotalAxle_Min_Rq_BSM 0;
BA_ "GenSigTimeoutTime_BSM" SG_ 205 TotalAxle_Max_Rq_BSM 0;
BA_ "GenSigTimeoutTime_BSM2" SG_ 205 TotalAxle_Max_Rq_BSM 0;
BA_ "GenSigTimeoutTime_CADM" SG_ 205 TotalAxle_Max_Rq_BSM 0;
BA_ "GenSigTimeoutTime_CVPAM" SG_ 205 TotalAxle_Max_Rq_BSM 0;
BA_ "GenSigTimeoutTime_EPS" SG_ 205 TotalAxle_Max_Rq_BSM 0;
BA_ "GenSigTimeoutTime_EVCU2" SG_ 205 TotalAxle_Max_Rq_BSM 0;
BA_ "GenSigTimeoutTime_ORC" SG_ 205 TotalAxle_Max_Rq_BSM 0;
BA_ "GenSigTimeoutTime_BSM" SG_ 205 RearAxle_Max_Rq_BSM 0;
BA_ "GenSigTimeoutTime_BSM2" SG_ 205 RearAxle_Max_Rq_BSM 0;
BA_ "GenSigTimeoutTime_CADM" SG_ 205 RearAxle_Max_Rq_BSM 0;
BA_ "GenSigTimeoutTime_CVPAM" SG_ 205 RearAxle_Max_Rq_BSM 0;
BA_ "GenSigTimeoutTime_ECM" SG_ 205 RearAxle_Max_Rq_BSM 0;
BA_ "GenSigTimeoutTime_EPS" SG_ 205 RearAxle_Max_Rq_BSM 0;
BA_ "GenSigTimeoutTime_ORC" SG_ 205 RearAxle_Max_Rq_BSM 0;
BA_ "GenSigTimeoutTime_BSM" SG_ 205 RearAxle_Min_Rq_BSM 0;
BA_ "GenSigTimeoutTime_BSM2" SG_ 205 RearAxle_Min_Rq_BSM 0;
BA_ "GenSigTimeoutTime_CADM" SG_ 205 RearAxle_Min_Rq_BSM 0;
BA_ "GenSigTimeoutTime_CVPAM" SG_ 205 RearAxle_Min_Rq_BSM 0;
BA_ "GenSigTimeoutTime_ECM" SG_ 205 RearAxle_Min_Rq_BSM 0;
BA_ "GenSigTimeoutTime_EPS" SG_ 205 RearAxle_Min_Rq_BSM 0;
BA_ "GenSigTimeoutTime_ORC" SG_ 205 RearAxle_Min_Rq_BSM 0;
BA_ "GenSigStartValue" SG_ 205 RearAxle_Rq_BSM 32767;
BA_ "GenSigTimeoutTime_BSM" SG_ 205 RearAxle_Rq_BSM 0;
BA_ "GenSigTimeoutTime_BSM2" SG_ 205 RearAxle_Rq_BSM 0;
BA_ "GenSigTimeoutTime_CADM" SG_ 205 RearAxle_Rq_BSM 0;
BA_ "GenSigTimeoutTime_CVPAM" SG_ 205 RearAxle_Rq_BSM 0;
BA_ "GenSigTimeoutTime_ECM" SG_ 205 RearAxle_Rq_BSM 0;
BA_ "GenSigTimeoutTime_EPS" SG_ 205 RearAxle_Rq_BSM 0;
BA_ "GenSigTimeoutTime_ORC" SG_ 205 RearAxle_Rq_BSM 0;
BA_ "GenSigTimeoutTime_BSM" SG_ 205 DrvrIntd_TotalBrk_AxleTorq 0;
BA_ "GenSigTimeoutTime_BSM2" SG_ 205 DrvrIntd_TotalBrk_AxleTorq 0;
BA_ "GenSigTimeoutTime_CADM" SG_ 205 DrvrIntd_TotalBrk_AxleTorq 0;
BA_ "GenSigTimeoutTime_CVPAM" SG_ 205 DrvrIntd_TotalBrk_AxleTorq 0;
BA_ "GenSigTimeoutTime_ECM" SG_ 205 DrvrIntd_TotalBrk_AxleTorq 0;
BA_ "GenSigTimeoutTime_EPS" SG_ 205 DrvrIntd_TotalBrk_AxleTorq 0;
BA_ "GenSigTimeoutTime_ORC" SG_ 205 DrvrIntd_TotalBrk_AxleTorq 0;
BA_ "GenSigTimeoutTime_BSM" SG_ 205 DriverReq_AxleTrq_Enabled_BSM 0;
BA_ "GenSigTimeoutTime_BSM2" SG_ 205 DriverReq_AxleTrq_Enabled_BSM 0;
BA_ "GenSigTimeoutTime_CADM" SG_ 205 DriverReq_AxleTrq_Enabled_BSM 0;
BA_ "GenSigTimeoutTime_CVPAM" SG_ 205 DriverReq_AxleTrq_Enabled_BSM 0;
BA_ "GenSigTimeoutTime_EPS" SG_ 205 DriverReq_AxleTrq_Enabled_BSM 0;
BA_ "GenSigTimeoutTime_ORC" SG_ 205 DriverReq_AxleTrq_Enabled_BSM 0;
BA_ "GenSigTimeoutTime_BSM" SG_ 205 Cmnd_TotBrkFrict_AxleTorq 0;
BA_ "GenSigTimeoutTime_BSM2" SG_ 205 Cmnd_TotBrkFrict_AxleTorq 0;
BA_ "GenSigTimeoutTime_CADM" SG_ 205 Cmnd_TotBrkFrict_AxleTorq 0;
BA_ "GenSigTimeoutTime_CVPAM" SG_ 205 Cmnd_TotBrkFrict_AxleTorq 0;
BA_ "GenSigTimeoutTime_ECM" SG_ 205 Cmnd_TotBrkFrict_AxleTorq 0;
BA_ "GenSigTimeoutTime_EPS" SG_ 205 Cmnd_TotBrkFrict_AxleTorq 0;
BA_ "GenSigTimeoutTime_ORC" SG_ 205 Cmnd_TotBrkFrict_AxleTorq 0;
BA_ "GenSigStartValue" SG_ 205 TotalAxle_Rq_BSM 32767;
BA_ "GenSigTimeoutTime_BSM" SG_ 205 TotalAxle_Rq_BSM 0;
BA_ "GenSigTimeoutTime_BSM2" SG_ 205 TotalAxle_Rq_BSM 0;
BA_ "GenSigTimeoutTime_CADM" SG_ 205 TotalAxle_Rq_BSM 0;
BA_ "GenSigTimeoutTime_CVPAM" SG_ 205 TotalAxle_Rq_BSM 0;
BA_ "GenSigTimeoutTime_EPS" SG_ 205 TotalAxle_Rq_BSM 0;
BA_ "GenSigTimeoutTime_EVCU2" SG_ 205 TotalAxle_Rq_BSM 0;
BA_ "GenSigTimeoutTime_ORC" SG_ 205 TotalAxle_Rq_BSM 0;
BA_ "GenSigStartValue" SG_ 205 DriverRequested_AxleTrq_BSM 32767;
BA_ "GenSigTimeoutTime_BSM" SG_ 205 DriverRequested_AxleTrq_BSM 0;
BA_ "GenSigTimeoutTime_BSM2" SG_ 205 DriverRequested_AxleTrq_BSM 0;
BA_ "GenSigTimeoutTime_CADM" SG_ 205 DriverRequested_AxleTrq_BSM 0;
BA_ "GenSigTimeoutTime_EPS" SG_ 205 DriverRequested_AxleTrq_BSM 0;
BA_ "GenSigTimeoutTime_ORC" SG_ 205 DriverRequested_AxleTrq_BSM 0;
BA_ "GenSigStartValue" SG_ 205 FrontAxle_Rq_BSM 32767;
BA_ "GenSigTimeoutTime_BSM" SG_ 205 FrontAxle_Rq_BSM 0;
BA_ "GenSigTimeoutTime_BSM2" SG_ 205 FrontAxle_Rq_BSM 0;
BA_ "GenSigTimeoutTime_CADM" SG_ 205 FrontAxle_Rq_BSM 0;
BA_ "GenSigTimeoutTime_CVPAM" SG_ 205 FrontAxle_Rq_BSM 0;
BA_ "GenSigTimeoutTime_ECM" SG_ 205 FrontAxle_Rq_BSM 0;
BA_ "GenSigTimeoutTime_EPS" SG_ 205 FrontAxle_Rq_BSM 0;
BA_ "GenSigTimeoutTime_ORC" SG_ 205 FrontAxle_Rq_BSM 0;
BA_ "GenSigTimeoutTime_MPAD" SG_ 1580 Motor1_RPM 0;
BA_ "GenSigTimeoutTime_ADCAM" SG_ 1580 Motor1_RPM 0;
BA_ "GenSigTimeoutTime_CVADAS" SG_ 1580 Motor1_RPM 0;
BA_ "GenSigTimeoutTime_MPAD" SG_ 1580 Motor2_RPM 0;
BA_ "GenSigTimeoutTime_ADCAM" SG_ 1580 Motor2_RPM 0;
BA_ "GenSigTimeoutTime_CVADAS" SG_ 1580 Motor2_RPM 0;
BA_ "GenSigStartValue" SG_ 1580 Motor1_RPM 32768;
BA_ "GenSigTimeoutTime_BSM" SG_ 1580 Motor1_RPM 0;
BA_ "GenSigTimeoutTime_BSM2" SG_ 1580 Motor1_RPM 0;
BA_ "GenSigTimeoutTime_CADM" SG_ 1580 Motor1_RPM 0;
BA_ "GenSigTimeoutTime_CVPAM" SG_ 1580 Motor1_RPM 0;
BA_ "GenSigTimeoutTime_ECM" SG_ 1580 Motor1_RPM 0;
BA_ "GenSigTimeoutTime_EPS" SG_ 1580 Motor1_RPM 0;
BA_ "GenSigTimeoutTime_EVCU2" SG_ 1580 Motor1_RPM 0;
BA_ "GenSigTimeoutTime_ORC" SG_ 1580 Motor1_RPM 0;
BA_ "GenSigStartValue" SG_ 1580 Motor2_RPM 32768;
BA_ "GenSigTimeoutTime_BSM" SG_ 1580 Motor2_RPM 0;
BA_ "GenSigTimeoutTime_BSM2" SG_ 1580 Motor2_RPM 0;
BA_ "GenSigTimeoutTime_CADM" SG_ 1580 Motor2_RPM 0;
BA_ "GenSigTimeoutTime_CVPAM" SG_ 1580 Motor2_RPM 0;
BA_ "GenSigTimeoutTime_ECM" SG_ 1580 Motor2_RPM 0;
BA_ "GenSigTimeoutTime_EPS" SG_ 1580 Motor2_RPM 0;
BA_ "GenSigTimeoutTime_EVCU2" SG_ 1580 Motor2_RPM 0;
BA_ "GenSigTimeoutTime_ORC" SG_ 1580 Motor2_RPM 0;
BA_ "GenSigTimeoutTime_BSM" SG_ 263 EVCU2_THA_Resp 0;
BA_ "GenSigTimeoutTime_BSM2" SG_ 263 EVCU2_THA_Resp 0;
BA_ "GenSigTimeoutTime_CADM" SG_ 263 EVCU2_THA_Resp 0;
BA_ "GenSigTimeoutTime_ECM" SG_ 263 EVCU2_THA_Resp 0;
BA_ "GenSigTimeoutTime_EPS" SG_ 263 EVCU2_THA_Resp 0;
BA_ "GenSigTimeoutTime_EVCU2" SG_ 263 EVCU2_THA_Resp 0;
BA_ "GenSigTimeoutTime_ORC" SG_ 263 EVCU2_THA_Resp 0;
BA_ "GenSigTimeoutTime_MPAD" SG_ 263 ISASts_PT 0;
BA_ "GenSigTimeoutTime_ADCAM" SG_ 263 ISASts_PT 0;
BA_ "GenSigTimeoutTime_CVADAS" SG_ 263 ISASts_PT 0;
BA_ "GenSigTimeoutTime_BSM" SG_ 263 ISASts_PT 0;
BA_ "GenSigTimeoutTime_BSM2" SG_ 263 ISASts_PT 0;
BA_ "GenSigTimeoutTime_ECM" SG_ 263 ISASts_PT 0;
BA_ "GenSigTimeoutTime_EPS" SG_ 263 ISASts_PT 0;
BA_ "GenSigTimeoutTime_EVCU2" SG_ 263 ISASts_PT 0;
BA_ "GenSigTimeoutTime_ORC" SG_ 263 ISASts_PT 0;
BA_ "GenSigTimeoutTime_MPAD" SG_ 263 SpeedLimitSts_PT 0;
BA_ "GenSigTimeoutTime_ADCAM" SG_ 263 SpeedLimitSts_PT 0;
BA_ "GenSigTimeoutTime_CVADAS" SG_ 263 SpeedLimitSts_PT 0;
BA_ "GenSigTimeoutTime_BSM" SG_ 263 SpeedLimitSts_PT 0;
BA_ "GenSigTimeoutTime_BSM2" SG_ 263 SpeedLimitSts_PT 0;
BA_ "GenSigTimeoutTime_ECM" SG_ 263 SpeedLimitSts_PT 0;
BA_ "GenSigTimeoutTime_EPS" SG_ 263 SpeedLimitSts_PT 0;
BA_ "GenSigTimeoutTime_EVCU2" SG_ 263 SpeedLimitSts_PT 0;
BA_ "GenSigTimeoutTime_ORC" SG_ 263 SpeedLimitSts_PT 0;
BA_ "GenSigTimeoutTime_ADCAM" SG_ 263 PdlPosActual_PT 0;
BA_ "GenSigTimeoutTime_CVADAS" SG_ 263 PdlPosActual_PT 0;
BA_ "GenSigTimeoutTime_BSM" SG_ 263 PdlPosActual_PT 0;
BA_ "GenSigTimeoutTime_MPAD" SG_ 263 ShiftLeverPosition_PT 0;
BA_ "GenSigTimeoutTime_CVADAS" SG_ 263 ShiftLeverPosition_PT 0;
BA_ "GenSigTimeoutTime_MPAD" SG_ 263 TargetGear_PT 0;
BA_ "GenSigTimeoutTime_ADCAM" SG_ 263 TargetGear_PT 0;
BA_ "GenSigTimeoutTime_CVADAS" SG_ 263 TargetGear_PT 0;
BA_ "GenSigTimeoutTime_ADCAM" SG_ 263 PowertrainPrplsnActv_PT 0;
BA_ "GenSigTimeoutTime_CVADAS" SG_ 263 PowertrainPrplsnActv_PT 0;
BA_ "GenSigTimeoutTime_MPAD" SG_ 263 GearEngagedForDisplay_PT 0;
BA_ "GenSigTimeoutTime_ADCAM" SG_ 263 GearEngagedForDisplay_PT 0;
BA_ "GenSigTimeoutTime_CVADAS" SG_ 263 GearEngagedForDisplay_PT 0;
BA_ "GenSigTimeoutTime_MPAD" SG_ 263 GearEngaged_PT 0;
BA_ "GenSigTimeoutTime_ADCAM" SG_ 263 GearEngaged_PT 0;
BA_ "GenSigTimeoutTime_CVADAS" SG_ 263 GearEngaged_PT 0;
BA_ "GenSigTimeoutTime_EPS" SG_ 263 GearEngaged_PT 0;
BA_ "GenSigTimeoutTime_MPAD" SG_ 263 DriveReady_PT 0;
BA_ "GenSigTimeoutTime_ADCAM" SG_ 263 DriveReady_PT 0;
BA_ "GenSigTimeoutTime_CVADAS" SG_ 263 DriveReady_PT 0;
BA_ "GenSigTimeoutTime_ADCAM" SG_ 263 MessageCounter_PT_SYSTEM_FD_1 0;
BA_ "GenSigTimeoutTime_CVADAS" SG_ 263 MessageCounter_PT_SYSTEM_FD_1 0;
BA_ "GenSigTimeoutTime_MPAD" SG_ 263 GasPedalPositionFailSts_PT 0;
BA_ "GenSigTimeoutTime_ADCAM" SG_ 263 GasPedalPositionFailSts_PT 0;
BA_ "GenSigTimeoutTime_CVADAS" SG_ 263 GasPedalPositionFailSts_PT 0;
BA_ "GenSigTimeoutTime_MPAD" SG_ 263 GasPedalPosition_PT 0;
BA_ "GenSigTimeoutTime_ADCAM" SG_ 263 GasPedalPosition_PT 0;
BA_ "GenSigTimeoutTime_CVADAS" SG_ 263 GasPedalPosition_PT 0;
BA_ "GenSigTimeoutTime_ADCAM" SG_ 263 CRC_PT_SYSTEM_FD_1 0;
BA_ "GenSigTimeoutTime_CVADAS" SG_ 263 CRC_PT_SYSTEM_FD_1 0;
BA_ "GenSigTimeoutTime_ECM" SG_ 263 PdlPosActual_PT 0;
BA_ "GenSigTimeoutTime_EPS" SG_ 263 PdlPosActual_PT 0;
BA_ "GenSigTimeoutTime_EVCU2" SG_ 263 PdlPosActual_PT 0;
BA_ "GenSigTimeoutTime_ORC" SG_ 263 PdlPosActual_PT 0;
BA_ "GenSigTimeoutTime_BSM" SG_ 263 ShiftLeverPosition_PT 0;
BA_ "GenSigTimeoutTime_BSM2" SG_ 263 ShiftLeverPosition_PT 0;
BA_ "GenSigTimeoutTime_CADM" SG_ 263 ShiftLeverPosition_PT 0;
BA_ "GenSigTimeoutTime_ECM" SG_ 263 ShiftLeverPosition_PT 0;
BA_ "GenSigTimeoutTime_EPS" SG_ 263 ShiftLeverPosition_PT 0;
BA_ "GenSigTimeoutTime_EVCU2" SG_ 263 ShiftLeverPosition_PT 0;
BA_ "GenSigTimeoutTime_ORC" SG_ 263 ShiftLeverPosition_PT 0;
BA_ "GenSigTimeoutTime_BSM" SG_ 263 TargetGear_PT 0;
BA_ "GenSigTimeoutTime_BSM2" SG_ 263 TargetGear_PT 0;
BA_ "GenSigTimeoutTime_CADM" SG_ 263 TargetGear_PT 0;
BA_ "GenSigTimeoutTime_CVPAM" SG_ 263 TargetGear_PT 0;
BA_ "GenSigTimeoutTime_ECM" SG_ 263 TargetGear_PT 0;
BA_ "GenSigTimeoutTime_EPS" SG_ 263 TargetGear_PT 0;
BA_ "GenSigTimeoutTime_EVCU2" SG_ 263 TargetGear_PT 0;
BA_ "GenSigTimeoutTime_ORC" SG_ 263 TargetGear_PT 0;
BA_ "GenSigTimeoutTime_BSM2" SG_ 263 PowertrainPrplsnActv_PT 0;
BA_ "GenSigTimeoutTime_CVPAM" SG_ 263 PowertrainPrplsnActv_PT 0;
BA_ "GenSigTimeoutTime_ECM" SG_ 263 PowertrainPrplsnActv_PT 0;
BA_ "GenSigTimeoutTime_EPS" SG_ 263 PowertrainPrplsnActv_PT 0;
BA_ "GenSigTimeoutTime_EVCU2" SG_ 263 PowertrainPrplsnActv_PT 0;
BA_ "GenSigTimeoutTime_ORC" SG_ 263 PowertrainPrplsnActv_PT 0;
BA_ "GenSigTimeoutTime_BSM" SG_ 263 GearEngagedForDisplay_PT 0;
BA_ "GenSigTimeoutTime_BSM2" SG_ 263 GearEngagedForDisplay_PT 0;
BA_ "GenSigTimeoutTime_CADM" SG_ 263 GearEngagedForDisplay_PT 0;
BA_ "GenSigTimeoutTime_CVPAM" SG_ 263 GearEngagedForDisplay_PT 0;
BA_ "GenSigTimeoutTime_ECM" SG_ 263 GearEngagedForDisplay_PT 0;
BA_ "GenSigTimeoutTime_EPS" SG_ 263 GearEngagedForDisplay_PT 0;
BA_ "GenSigTimeoutTime_EVCU2" SG_ 263 GearEngagedForDisplay_PT 0;
BA_ "GenSigTimeoutTime_ORC" SG_ 263 GearEngagedForDisplay_PT 0;
BA_ "GenSigTimeoutTime_BSM" SG_ 263 GearEngaged_PT 0;
BA_ "GenSigTimeoutTime_BSM2" SG_ 263 GearEngaged_PT 0;
BA_ "GenSigTimeoutTime_CADM" SG_ 263 GearEngaged_PT 0;
BA_ "GenSigTimeoutTime_CVPAM" SG_ 263 GearEngaged_PT 0;
BA_ "GenSigTimeoutTime_ECM" SG_ 263 GearEngaged_PT 0;
BA_ "GenSigTimeoutTime_EVCU2" SG_ 263 GearEngaged_PT 0;
BA_ "GenSigTimeoutTime_ORC" SG_ 263 GearEngaged_PT 0;
BA_ "GenSigTimeoutTime_BSM" SG_ 263 DriveReady_PT 0;
BA_ "GenSigTimeoutTime_BSM2" SG_ 263 DriveReady_PT 0;
BA_ "GenSigTimeoutTime_CADM" SG_ 263 DriveReady_PT 0;
BA_ "GenSigTimeoutTime_CVPAM" SG_ 263 DriveReady_PT 0;
BA_ "GenSigTimeoutTime_ECM" SG_ 263 DriveReady_PT 0;
BA_ "GenSigTimeoutTime_EPS" SG_ 263 DriveReady_PT 0;
BA_ "GenSigTimeoutTime_EVCU2" SG_ 263 DriveReady_PT 0;
BA_ "GenSigTimeoutTime_ORC" SG_ 263 DriveReady_PT 0;
BA_ "GenSigTimeoutTime_BSM" SG_ 263 MessageCounter_PT_SYSTEM_FD_1 0;
BA_ "GenSigTimeoutTime_BSM2" SG_ 263 MessageCounter_PT_SYSTEM_FD_1 0;
BA_ "GenSigTimeoutTime_CADM" SG_ 263 MessageCounter_PT_SYSTEM_FD_1 0;
BA_ "GenSigTimeoutTime_CVPAM" SG_ 263 MessageCounter_PT_SYSTEM_FD_1 0;
BA_ "GenSigTimeoutTime_EPS" SG_ 263 MessageCounter_PT_SYSTEM_FD_1 0;
BA_ "GenSigTimeoutTime_EVCU2" SG_ 263 MessageCounter_PT_SYSTEM_FD_1 0;
BA_ "GenSigTimeoutTime_ORC" SG_ 263 MessageCounter_PT_SYSTEM_FD_1 0;
BA_ "GenSigTimeoutTime_BSM" SG_ 263 GasPedalPositionFailSts_PT 0;
BA_ "GenSigTimeoutTime_BSM2" SG_ 263 GasPedalPositionFailSts_PT 0;
BA_ "GenSigTimeoutTime_CVPAM" SG_ 263 GasPedalPositionFailSts_PT 0;
BA_ "GenSigTimeoutTime_ECM" SG_ 263 GasPedalPositionFailSts_PT 0;
BA_ "GenSigTimeoutTime_EPS" SG_ 263 GasPedalPositionFailSts_PT 0;
BA_ "GenSigTimeoutTime_EVCU2" SG_ 263 GasPedalPositionFailSts_PT 0;
BA_ "GenSigTimeoutTime_ORC" SG_ 263 GasPedalPositionFailSts_PT 0;
BA_ "GenSigTimeoutTime_BSM2" SG_ 263 GasPedalPosition_PT 0;
BA_ "GenSigTimeoutTime_CADM" SG_ 263 GasPedalPosition_PT 0;
BA_ "GenSigTimeoutTime_CVPAM" SG_ 263 GasPedalPosition_PT 0;
BA_ "GenSigTimeoutTime_ECM" SG_ 263 GasPedalPosition_PT 0;
BA_ "GenSigTimeoutTime_EPS" SG_ 263 GasPedalPosition_PT 0;
BA_ "GenSigTimeoutTime_EVCU2" SG_ 263 GasPedalPosition_PT 0;
BA_ "GenSigTimeoutTime_ORC" SG_ 263 GasPedalPosition_PT 0;
BA_ "GenSigTimeoutTime_BSM" SG_ 263 CRC_PT_SYSTEM_FD_1 0;
BA_ "GenSigTimeoutTime_BSM2" SG_ 263 CRC_PT_SYSTEM_FD_1 0;
BA_ "GenSigTimeoutTime_CADM" SG_ 263 CRC_PT_SYSTEM_FD_1 0;
BA_ "GenSigTimeoutTime_CVPAM" SG_ 263 CRC_PT_SYSTEM_FD_1 0;
BA_ "GenSigTimeoutTime_EPS" SG_ 263 CRC_PT_SYSTEM_FD_1 0;
BA_ "GenSigTimeoutTime_EVCU2" SG_ 263 CRC_PT_SYSTEM_FD_1 0;
BA_ "GenSigTimeoutTime_ORC" SG_ 263 CRC_PT_SYSTEM_FD_1 0;
BA_ "GenSigTimeoutTime_MPAD" SG_ 2654486592 CBV_bit0_RepeatMessageRequestBit_1E384040 0;
BA_ "GenSigTimeoutTime_ADCAM" SG_ 2654486592 CBV_bit0_RepeatMessageRequestBit_1E384040 0;
BA_ "GenSigTimeoutTime_CVADAS" SG_ 2654486592 CBV_bit0_RepeatMessageRequestBit_1E384040 0;
BA_ "GenSigTimeoutTime_MPAD" SG_ 2654486592 CBV_bit1_1E384040 0;
BA_ "GenSigTimeoutTime_ADCAM" SG_ 2654486592 CBV_bit1_1E384040 0;
BA_ "GenSigTimeoutTime_CVADAS" SG_ 2654486592 CBV_bit1_1E384040 0;
BA_ "GenSigTimeoutTime_MPAD" SG_ 2654486592 CBV_bit2_1E384040 0;
BA_ "GenSigTimeoutTime_ADCAM" SG_ 2654486592 CBV_bit2_1E384040 0;
BA_ "GenSigTimeoutTime_CVADAS" SG_ 2654486592 CBV_bit2_1E384040 0;
BA_ "GenSigTimeoutTime_MPAD" SG_ 2654486592 CBV_bit3_NMCoordinatorBit_1E384040 0;
BA_ "GenSigTimeoutTime_ADCAM" SG_ 2654486592 CBV_bit3_NMCoordinatorBit_1E384040 0;
BA_ "GenSigTimeoutTime_CVADAS" SG_ 2654486592 CBV_bit3_NMCoordinatorBit_1E384040 0;
BA_ "GenSigTimeoutTime_MPAD" SG_ 2654486592 CBV_bit4_ActiveWakeupBit_1E384040 0;
BA_ "GenSigTimeoutTime_ADCAM" SG_ 2654486592 CBV_bit4_ActiveWakeupBit_1E384040 0;
BA_ "GenSigTimeoutTime_CVADAS" SG_ 2654486592 CBV_bit4_ActiveWakeupBit_1E384040 0;
BA_ "GenSigTimeoutTime_MPAD" SG_ 2654486592 CBV_bit5_1E384040 0;
BA_ "GenSigTimeoutTime_ADCAM" SG_ 2654486592 CBV_bit5_1E384040 0;
BA_ "GenSigTimeoutTime_CVADAS" SG_ 2654486592 CBV_bit5_1E384040 0;
BA_ "GenSigTimeoutTime_MPAD" SG_ 2654486592 CBV_bit6_PartialNtwInfBit_1E384040 0;
BA_ "GenSigTimeoutTime_ADCAM" SG_ 2654486592 CBV_bit6_PartialNtwInfBit_1E384040 0;
BA_ "GenSigTimeoutTime_CVADAS" SG_ 2654486592 CBV_bit6_PartialNtwInfBit_1E384040 0;
BA_ "GenSigTimeoutTime_MPAD" SG_ 2654486592 CBV_bit7_1E384040 0;
BA_ "GenSigTimeoutTime_ADCAM" SG_ 2654486592 CBV_bit7_1E384040 0;
BA_ "GenSigTimeoutTime_CVADAS" SG_ 2654486592 CBV_bit7_1E384040 0;
BA_ "GenSigTimeoutTime_MPAD" SG_ 2654486592 SourceNodeIdentifier_1E384040 0;
BA_ "GenSigTimeoutTime_ADCAM" SG_ 2654486592 SourceNodeIdentifier_1E384040 0;
BA_ "GenSigTimeoutTime_CVADAS" SG_ 2654486592 SourceNodeIdentifier_1E384040 0;
BA_ "GenSigTimeoutTime_BSM" SG_ 2654486592 CBV_bit0_RepeatMessageRequestBit_1E384040 0;
BA_ "GenSigTimeoutTime_BSM2" SG_ 2654486592 CBV_bit0_RepeatMessageRequestBit_1E384040 0;
BA_ "GenSigTimeoutTime_CADM" SG_ 2654486592 CBV_bit0_RepeatMessageRequestBit_1E384040 0;
BA_ "GenSigTimeoutTime_CVPAM" SG_ 2654486592 CBV_bit0_RepeatMessageRequestBit_1E384040 0;
BA_ "GenSigTimeoutTime_ECM" SG_ 2654486592 CBV_bit0_RepeatMessageRequestBit_1E384040 0;
BA_ "GenSigTimeoutTime_EPS" SG_ 2654486592 CBV_bit0_RepeatMessageRequestBit_1E384040 0;
BA_ "GenSigTimeoutTime_EVCU2" SG_ 2654486592 CBV_bit0_RepeatMessageRequestBit_1E384040 0;
BA_ "GenSigTimeoutTime_ORC" SG_ 2654486592 CBV_bit0_RepeatMessageRequestBit_1E384040 0;
BA_ "GenSigTimeoutTime_BSM" SG_ 2654486592 CBV_bit1_1E384040 0;
BA_ "GenSigTimeoutTime_BSM2" SG_ 2654486592 CBV_bit1_1E384040 0;
BA_ "GenSigTimeoutTime_CADM" SG_ 2654486592 CBV_bit1_1E384040 0;
BA_ "GenSigTimeoutTime_CVPAM" SG_ 2654486592 CBV_bit1_1E384040 0;
BA_ "GenSigTimeoutTime_ECM" SG_ 2654486592 CBV_bit1_1E384040 0;
BA_ "GenSigTimeoutTime_EPS" SG_ 2654486592 CBV_bit1_1E384040 0;
BA_ "GenSigTimeoutTime_EVCU2" SG_ 2654486592 CBV_bit1_1E384040 0;
BA_ "GenSigTimeoutTime_ORC" SG_ 2654486592 CBV_bit1_1E384040 0;
BA_ "GenSigTimeoutTime_BSM" SG_ 2654486592 CBV_bit2_1E384040 0;
BA_ "GenSigTimeoutTime_BSM2" SG_ 2654486592 CBV_bit2_1E384040 0;
BA_ "GenSigTimeoutTime_CADM" SG_ 2654486592 CBV_bit2_1E384040 0;
BA_ "GenSigTimeoutTime_CVPAM" SG_ 2654486592 CBV_bit2_1E384040 0;
BA_ "GenSigTimeoutTime_ECM" SG_ 2654486592 CBV_bit2_1E384040 0;
BA_ "GenSigTimeoutTime_EPS" SG_ 2654486592 CBV_bit2_1E384040 0;
BA_ "GenSigTimeoutTime_EVCU2" SG_ 2654486592 CBV_bit2_1E384040 0;
BA_ "GenSigTimeoutTime_ORC" SG_ 2654486592 CBV_bit2_1E384040 0;
BA_ "GenSigTimeoutTime_BSM" SG_ 2654486592 CBV_bit3_NMCoordinatorBit_1E384040 0;
BA_ "GenSigTimeoutTime_BSM2" SG_ 2654486592 CBV_bit3_NMCoordinatorBit_1E384040 0;
BA_ "GenSigTimeoutTime_CADM" SG_ 2654486592 CBV_bit3_NMCoordinatorBit_1E384040 0;
BA_ "GenSigTimeoutTime_CVPAM" SG_ 2654486592 CBV_bit3_NMCoordinatorBit_1E384040 0;
BA_ "GenSigTimeoutTime_ECM" SG_ 2654486592 CBV_bit3_NMCoordinatorBit_1E384040 0;
BA_ "GenSigTimeoutTime_EPS" SG_ 2654486592 CBV_bit3_NMCoordinatorBit_1E384040 0;
BA_ "GenSigTimeoutTime_EVCU2" SG_ 2654486592 CBV_bit3_NMCoordinatorBit_1E384040 0;
BA_ "GenSigTimeoutTime_ORC" SG_ 2654486592 CBV_bit3_NMCoordinatorBit_1E384040 0;
BA_ "GenSigTimeoutTime_BSM" SG_ 2654486592 CBV_bit4_ActiveWakeupBit_1E384040 0;
BA_ "GenSigTimeoutTime_BSM2" SG_ 2654486592 CBV_bit4_ActiveWakeupBit_1E384040 0;
BA_ "GenSigTimeoutTime_CADM" SG_ 2654486592 CBV_bit4_ActiveWakeupBit_1E384040 0;
BA_ "GenSigTimeoutTime_CVPAM" SG_ 2654486592 CBV_bit4_ActiveWakeupBit_1E384040 0;
BA_ "GenSigTimeoutTime_ECM" SG_ 2654486592 CBV_bit4_ActiveWakeupBit_1E384040 0;
BA_ "GenSigTimeoutTime_EPS" SG_ 2654486592 CBV_bit4_ActiveWakeupBit_1E384040 0;
BA_ "GenSigTimeoutTime_EVCU2" SG_ 2654486592 CBV_bit4_ActiveWakeupBit_1E384040 0;
BA_ "GenSigTimeoutTime_ORC" SG_ 2654486592 CBV_bit4_ActiveWakeupBit_1E384040 0;
BA_ "GenSigTimeoutTime_BSM" SG_ 2654486592 CBV_bit5_1E384040 0;
BA_ "GenSigTimeoutTime_BSM2" SG_ 2654486592 CBV_bit5_1E384040 0;
BA_ "GenSigTimeoutTime_CADM" SG_ 2654486592 CBV_bit5_1E384040 0;
BA_ "GenSigTimeoutTime_CVPAM" SG_ 2654486592 CBV_bit5_1E384040 0;
BA_ "GenSigTimeoutTime_ECM" SG_ 2654486592 CBV_bit5_1E384040 0;
BA_ "GenSigTimeoutTime_EPS" SG_ 2654486592 CBV_bit5_1E384040 0;
BA_ "GenSigTimeoutTime_EVCU2" SG_ 2654486592 CBV_bit5_1E384040 0;
BA_ "GenSigTimeoutTime_ORC" SG_ 2654486592 CBV_bit5_1E384040 0;
BA_ "GenSigTimeoutTime_BSM" SG_ 2654486592 CBV_bit6_PartialNtwInfBit_1E384040 0;
BA_ "GenSigTimeoutTime_BSM2" SG_ 2654486592 CBV_bit6_PartialNtwInfBit_1E384040 0;
BA_ "GenSigTimeoutTime_CADM" SG_ 2654486592 CBV_bit6_PartialNtwInfBit_1E384040 0;
BA_ "GenSigTimeoutTime_CVPAM" SG_ 2654486592 CBV_bit6_PartialNtwInfBit_1E384040 0;
BA_ "GenSigTimeoutTime_ECM" SG_ 2654486592 CBV_bit6_PartialNtwInfBit_1E384040 0;
BA_ "GenSigTimeoutTime_EPS" SG_ 2654486592 CBV_bit6_PartialNtwInfBit_1E384040 0;
BA_ "GenSigTimeoutTime_EVCU2" SG_ 2654486592 CBV_bit6_PartialNtwInfBit_1E384040 0;
BA_ "GenSigTimeoutTime_ORC" SG_ 2654486592 CBV_bit6_PartialNtwInfBit_1E384040 0;
BA_ "GenSigTimeoutTime_BSM" SG_ 2654486592 CBV_bit7_1E384040 0;
BA_ "GenSigTimeoutTime_BSM2" SG_ 2654486592 CBV_bit7_1E384040 0;
BA_ "GenSigTimeoutTime_CADM" SG_ 2654486592 CBV_bit7_1E384040 0;
BA_ "GenSigTimeoutTime_CVPAM" SG_ 2654486592 CBV_bit7_1E384040 0;
BA_ "GenSigTimeoutTime_ECM" SG_ 2654486592 CBV_bit7_1E384040 0;
BA_ "GenSigTimeoutTime_EPS" SG_ 2654486592 CBV_bit7_1E384040 0;
BA_ "GenSigTimeoutTime_EVCU2" SG_ 2654486592 CBV_bit7_1E384040 0;
BA_ "GenSigTimeoutTime_ORC" SG_ 2654486592 CBV_bit7_1E384040 0;
BA_ "GenSigTimeoutTime_BSM" SG_ 2654486592 SourceNodeIdentifier_1E384040 0;
BA_ "GenSigTimeoutTime_BSM2" SG_ 2654486592 SourceNodeIdentifier_1E384040 0;
BA_ "GenSigTimeoutTime_CADM" SG_ 2654486592 SourceNodeIdentifier_1E384040 0;
BA_ "GenSigTimeoutTime_CVPAM" SG_ 2654486592 SourceNodeIdentifier_1E384040 0;
BA_ "GenSigTimeoutTime_ECM" SG_ 2654486592 SourceNodeIdentifier_1E384040 0;
BA_ "GenSigTimeoutTime_EPS" SG_ 2654486592 SourceNodeIdentifier_1E384040 0;
BA_ "GenSigTimeoutTime_EVCU2" SG_ 2654486592 SourceNodeIdentifier_1E384040 0;
BA_ "GenSigTimeoutTime_ORC" SG_ 2654486592 SourceNodeIdentifier_1E384040 0;
BA_ "GenSigTimeoutTime_MPAD" SG_ 292 BPCM_HV_SOC 0;
BA_ "GenSigTimeoutTime_ADCAM" SG_ 292 BPCM_HV_SOC 0;
BA_ "GenSigTimeoutTime_CVADAS" SG_ 292 BPCM_HV_SOC 0;
BA_ "GenSigTimeoutTime_MPAD" SG_ 292 BPCM_HV_InternalVoltage 0;
BA_ "GenSigTimeoutTime_ADCAM" SG_ 292 BPCM_HV_InternalVoltage 0;
BA_ "GenSigTimeoutTime_CVADAS" SG_ 292 BPCM_HV_InternalVoltage 0;
BA_ "GenSigTimeoutTime_MPAD" SG_ 292 BPCM_HV_Trac_Main_Contac_Sts 0;
BA_ "GenSigTimeoutTime_ADCAM" SG_ 292 BPCM_HV_Trac_Main_Contac_Sts 0;
BA_ "GenSigTimeoutTime_CVADAS" SG_ 292 BPCM_HV_Trac_Main_Contac_Sts 0;
BA_ "GenSigTimeoutTime_MPAD" SG_ 292 BPCM_HV_Trac_Bus_Sts 0;
BA_ "GenSigTimeoutTime_ADCAM" SG_ 292 BPCM_HV_Trac_Bus_Sts 0;
BA_ "GenSigTimeoutTime_CVADAS" SG_ 292 BPCM_HV_Trac_Bus_Sts 0;
BA_ "GenSigTimeoutTime_BSM2" SG_ 292 BPCM_HV_SOC 0;
BA_ "GenSigTimeoutTime_CADM" SG_ 292 BPCM_HV_SOC 0;
BA_ "GenSigTimeoutTime_CVPAM" SG_ 292 BPCM_HV_SOC 0;
BA_ "GenSigTimeoutTime_ECM" SG_ 292 BPCM_HV_SOC 0;
BA_ "GenSigTimeoutTime_EPS" SG_ 292 BPCM_HV_SOC 0;
BA_ "GenSigTimeoutTime_EVCU2" SG_ 292 BPCM_HV_SOC 0;
BA_ "GenSigTimeoutTime_ORC" SG_ 292 BPCM_HV_SOC 0;
BA_ "GenSigTimeoutTime_BSM" SG_ 292 BPCM_HV_InternalVoltage 0;
BA_ "GenSigTimeoutTime_BSM2" SG_ 292 BPCM_HV_InternalVoltage 0;
BA_ "GenSigTimeoutTime_CADM" SG_ 292 BPCM_HV_InternalVoltage 0;
BA_ "GenSigTimeoutTime_CVPAM" SG_ 292 BPCM_HV_InternalVoltage 0;
BA_ "GenSigTimeoutTime_ECM" SG_ 292 BPCM_HV_InternalVoltage 0;
BA_ "GenSigTimeoutTime_EPS" SG_ 292 BPCM_HV_InternalVoltage 0;
BA_ "GenSigTimeoutTime_EVCU2" SG_ 292 BPCM_HV_InternalVoltage 0;
BA_ "GenSigTimeoutTime_ORC" SG_ 292 BPCM_HV_InternalVoltage 0;
BA_ "GenSigTimeoutTime_BSM" SG_ 292 BPCM_HV_Trac_Main_Contac_Sts 0;
BA_ "GenSigTimeoutTime_BSM2" SG_ 292 BPCM_HV_Trac_Main_Contac_Sts 0;
BA_ "GenSigTimeoutTime_CADM" SG_ 292 BPCM_HV_Trac_Main_Contac_Sts 0;
BA_ "GenSigTimeoutTime_CVPAM" SG_ 292 BPCM_HV_Trac_Main_Contac_Sts 0;
BA_ "GenSigTimeoutTime_ECM" SG_ 292 BPCM_HV_Trac_Main_Contac_Sts 0;
BA_ "GenSigTimeoutTime_EPS" SG_ 292 BPCM_HV_Trac_Main_Contac_Sts 0;
BA_ "GenSigTimeoutTime_EVCU2" SG_ 292 BPCM_HV_Trac_Main_Contac_Sts 0;
BA_ "GenSigTimeoutTime_ORC" SG_ 292 BPCM_HV_Trac_Main_Contac_Sts 0;
BA_ "GenSigTimeoutTime_BSM" SG_ 292 BPCM_HV_Trac_Bus_Sts 0;
BA_ "GenSigTimeoutTime_BSM2" SG_ 292 BPCM_HV_Trac_Bus_Sts 0;
BA_ "GenSigTimeoutTime_CADM" SG_ 292 BPCM_HV_Trac_Bus_Sts 0;
BA_ "GenSigTimeoutTime_CVPAM" SG_ 292 BPCM_HV_Trac_Bus_Sts 0;
BA_ "GenSigTimeoutTime_ECM" SG_ 292 BPCM_HV_Trac_Bus_Sts 0;
BA_ "GenSigTimeoutTime_EPS" SG_ 292 BPCM_HV_Trac_Bus_Sts 0;
BA_ "GenSigTimeoutTime_EVCU2" SG_ 292 BPCM_HV_Trac_Bus_Sts 0;
BA_ "GenSigTimeoutTime_ORC" SG_ 292 BPCM_HV_Trac_Bus_Sts 0;
BA_ "GenSigTimeoutTime_ADCAM" SG_ 299 CRC_ADAS_FD_INFO3 0;
BA_ "GenSigTimeoutTime_CVADAS" SG_ 299 CRC_ADAS_FD_INFO3 0;
BA_ "GenSigTimeoutTime_ADCAM" SG_ 299 MessageCounter_ADAS_FD_INFO3 0;
BA_ "GenSigTimeoutTime_CVADAS" SG_ 299 MessageCounter_ADAS_FD_INFO3 0;
BA_ "GenSigTimeoutTime_MPAD" SG_ 299 ACC_Axle_Torque 0;
BA_ "GenSigTimeoutTime_ADCAM" SG_ 299 ACC_Axle_Torque 0;
BA_ "GenSigTimeoutTime_CVADAS" SG_ 299 ACC_Axle_Torque 0;
BA_ "GenSigTimeoutTime_MPAD" SG_ 299 ACC_Axle_Torque_Enabled 0;
BA_ "GenSigTimeoutTime_ADCAM" SG_ 299 ACC_Axle_Torque_Enabled 0;
BA_ "GenSigTimeoutTime_CVADAS" SG_ 299 ACC_Axle_Torque_Enabled 0;
BA_ "GenSigTimeoutTime_BSM2" SG_ 299 CRC_ADAS_FD_INFO3 0;
BA_ "GenSigTimeoutTime_CADM" SG_ 299 CRC_ADAS_FD_INFO3 0;
BA_ "GenSigTimeoutTime_CVPAM" SG_ 299 CRC_ADAS_FD_INFO3 0;
BA_ "GenSigTimeoutTime_ECM" SG_ 299 CRC_ADAS_FD_INFO3 0;
BA_ "GenSigTimeoutTime_EPS" SG_ 299 CRC_ADAS_FD_INFO3 0;
BA_ "GenSigTimeoutTime_EVCU2" SG_ 299 CRC_ADAS_FD_INFO3 0;
BA_ "GenSigTimeoutTime_ORC" SG_ 299 CRC_ADAS_FD_INFO3 0;
BA_ "GenSigTimeoutTime_BSM2" SG_ 299 MessageCounter_ADAS_FD_INFO3 0;
BA_ "GenSigTimeoutTime_CADM" SG_ 299 MessageCounter_ADAS_FD_INFO3 0;
BA_ "GenSigTimeoutTime_CVPAM" SG_ 299 MessageCounter_ADAS_FD_INFO3 0;
BA_ "GenSigTimeoutTime_ECM" SG_ 299 MessageCounter_ADAS_FD_INFO3 0;
BA_ "GenSigTimeoutTime_EPS" SG_ 299 MessageCounter_ADAS_FD_INFO3 0;
BA_ "GenSigTimeoutTime_EVCU2" SG_ 299 MessageCounter_ADAS_FD_INFO3 0;
BA_ "GenSigTimeoutTime_ORC" SG_ 299 MessageCounter_ADAS_FD_INFO3 0;
BA_ "GenSigStartValue" SG_ 299 ACC_Axle_Torque 32768;
BA_ "GenSigTimeoutTime_BSM2" SG_ 299 ACC_Axle_Torque 0;
BA_ "GenSigTimeoutTime_CADM" SG_ 299 ACC_Axle_Torque 0;
BA_ "GenSigTimeoutTime_CVPAM" SG_ 299 ACC_Axle_Torque 0;
BA_ "GenSigTimeoutTime_ECM" SG_ 299 ACC_Axle_Torque 0;
BA_ "GenSigTimeoutTime_EPS" SG_ 299 ACC_Axle_Torque 0;
BA_ "GenSigTimeoutTime_EVCU2" SG_ 299 ACC_Axle_Torque 0;
BA_ "GenSigTimeoutTime_ORC" SG_ 299 ACC_Axle_Torque 0;
BA_ "GenSigTimeoutTime_BSM2" SG_ 299 ACC_Axle_Torque_Enabled 0;
BA_ "GenSigTimeoutTime_CADM" SG_ 299 ACC_Axle_Torque_Enabled 0;
BA_ "GenSigTimeoutTime_CVPAM" SG_ 299 ACC_Axle_Torque_Enabled 0;
BA_ "GenSigTimeoutTime_ECM" SG_ 299 ACC_Axle_Torque_Enabled 0;
BA_ "GenSigTimeoutTime_EPS" SG_ 299 ACC_Axle_Torque_Enabled 0;
BA_ "GenSigTimeoutTime_EVCU2" SG_ 299 ACC_Axle_Torque_Enabled 0;
BA_ "GenSigTimeoutTime_ORC" SG_ 299 ACC_Axle_Torque_Enabled 0;
BA_ "GenSigTimeoutTime_CVADAS" SG_ 1472 THA_EPB_Req 0;
BA_ "GenSigSendType" SG_ 1472 THA_EPB_Req 4;
BA_ "GenSigTimeoutTime_BSM2" SG_ 1472 THA_EPB_Req 0;
BA_ "GenSigTimeoutTime_CADM" SG_ 1472 THA_EPB_Req 0;
BA_ "GenSigTimeoutTime_ECM" SG_ 1472 THA_EPB_Req 0;
BA_ "GenSigTimeoutTime_EPS" SG_ 1472 THA_EPB_Req 0;
BA_ "GenSigTimeoutTime_EVCU2" SG_ 1472 THA_EPB_Req 0;
BA_ "GenSigTimeoutTime_ORC" SG_ 1472 THA_EPB_Req 0;
BA_ "GenSigTimeoutTime_CVADAS" SG_ 1472 THA_SteeringTorqueReq 0;
BA_ "GenSigSendType" SG_ 1472 THA_SteeringTorqueReq 4;
BA_ "GenSigTimeoutTime_BSM" SG_ 1472 THA_SteeringTorqueReq 0;
BA_ "GenSigTimeoutTime_BSM2" SG_ 1472 THA_SteeringTorqueReq 0;
BA_ "GenSigTimeoutTime_CADM" SG_ 1472 THA_SteeringTorqueReq 0;
BA_ "GenSigTimeoutTime_ECM" SG_ 1472 THA_SteeringTorqueReq 0;
BA_ "GenSigTimeoutTime_EVCU2" SG_ 1472 THA_SteeringTorqueReq 0;
BA_ "GenSigTimeoutTime_ORC" SG_ 1472 THA_SteeringTorqueReq 0;
BA_ "GenSigTimeoutTime_CVADAS" SG_ 1472 THA_Speed_Limit 0;
BA_ "GenSigSendType" SG_ 1472 THA_Speed_Limit 4;
BA_ "GenSigTimeoutTime_BSM2" SG_ 1472 THA_Speed_Limit 0;
BA_ "GenSigTimeoutTime_CADM" SG_ 1472 THA_Speed_Limit 0;
BA_ "GenSigTimeoutTime_ORC" SG_ 1472 THA_Speed_Limit 0;
BA_ "GenSigTimeoutTime_CVADAS" SG_ 1472 THA_SteeringDamping 0;
BA_ "GenSigStartValue" SG_ 1472 THA_SteeringDamping 100;
BA_ "GenSigSendType" SG_ 1472 THA_SteeringDamping 3;
BA_ "GenSigTimeoutTime_BSM" SG_ 1472 THA_SteeringDamping 0;
BA_ "GenSigTimeoutTime_BSM2" SG_ 1472 THA_SteeringDamping 0;
BA_ "GenSigTimeoutTime_CADM" SG_ 1472 THA_SteeringDamping 0;
BA_ "GenSigTimeoutTime_ECM" SG_ 1472 THA_SteeringDamping 0;
BA_ "GenSigTimeoutTime_EVCU2" SG_ 1472 THA_SteeringDamping 0;
BA_ "GenSigTimeoutTime_ORC" SG_ 1472 THA_SteeringDamping 0;
BA_ "GenSigTimeoutTime_CVADAS" SG_ 1472 THA_SteeringTorqueInfo 0;
BA_ "GenSigStartValue" SG_ 1472 THA_SteeringTorqueInfo 1024;
BA_ "GenSigSendType" SG_ 1472 THA_SteeringTorqueInfo 3;
BA_ "GenSigTimeoutTime_BSM" SG_ 1472 THA_SteeringTorqueInfo 0;
BA_ "GenSigTimeoutTime_BSM2" SG_ 1472 THA_SteeringTorqueInfo 0;
BA_ "GenSigTimeoutTime_CADM" SG_ 1472 THA_SteeringTorqueInfo 0;
BA_ "GenSigTimeoutTime_ECM" SG_ 1472 THA_SteeringTorqueInfo 0;
BA_ "GenSigTimeoutTime_EVCU2" SG_ 1472 THA_SteeringTorqueInfo 0;
BA_ "GenSigTimeoutTime_ORC" SG_ 1472 THA_SteeringTorqueInfo 0;
BA_ "GenSigTimeoutTime_CVADAS" SG_ 1472 THA_STAT 0;
BA_ "GenSigSendType" SG_ 1472 THA_STAT 4;
BA_ "GenSigTimeoutTime_BSM2" SG_ 1472 THA_STAT 0;
BA_ "GenSigTimeoutTime_CADM" SG_ 1472 THA_STAT 0;
BA_ "GenSigTimeoutTime_ORC" SG_ 1472 THA_STAT 0;
BA_ "GenSigTimeoutTime_CVADAS" SG_ 1472 THA_SpeedLimit_Req 0;
BA_ "GenSigSendType" SG_ 1472 THA_SpeedLimit_Req 4;
BA_ "GenSigTimeoutTime_BSM2" SG_ 1472 THA_SpeedLimit_Req 0;
BA_ "GenSigTimeoutTime_CADM" SG_ 1472 THA_SpeedLimit_Req 0;
BA_ "GenSigTimeoutTime_EPS" SG_ 1472 THA_SpeedLimit_Req 0;
BA_ "GenSigTimeoutTime_ORC" SG_ 1472 THA_SpeedLimit_Req 0;
BA_ "GenSigTimeoutTime_CVADAS" SG_ 1472 TRSC_SteeringDamping 0;
BA_ "GenSigTimeoutTime_CVADAS" SG_ 1472 TRSC_SteeringTorqueInfo 0;
BA_ "GenSigTimeoutTime_CVADAS" SG_ 1472 TRSC_SteeringTorqueReq 0;
BA_ "GenSigTimeoutTime_CVADAS" SG_ 1472 TRSC_VehicleStop_Req 0;
BA_ "GenSigTimeoutTime_CVADAS" SG_ 1472 TRSC_STAT 0;
BA_ "GenSigTimeoutTime_CVADAS" SG_ 1472 TRSC_SpeedLimit_Req 0;
BA_ "GenSigTimeoutTime_CVADAS" SG_ 1472 MessageCounter_TRSCM1 0;
BA_ "GenSigTimeoutTime_CVADAS" SG_ 1472 CRC_TRSCM1 0;
BA_ "GenSigStartValue" SG_ 1472 TRSC_SteeringDamping 100;
BA_ "GenSigTimeoutTime_BSM" SG_ 1472 TRSC_SteeringDamping 0;
BA_ "GenSigTimeoutTime_BSM2" SG_ 1472 TRSC_SteeringDamping 0;
BA_ "GenSigTimeoutTime_CADM" SG_ 1472 TRSC_SteeringDamping 0;
BA_ "GenSigTimeoutTime_CVPAM" SG_ 1472 TRSC_SteeringDamping 0;
BA_ "GenSigTimeoutTime_ECM" SG_ 1472 TRSC_SteeringDamping 0;
BA_ "GenSigTimeoutTime_EVCU2" SG_ 1472 TRSC_SteeringDamping 0;
BA_ "GenSigTimeoutTime_ORC" SG_ 1472 TRSC_SteeringDamping 0;
BA_ "GenSigStartValue" SG_ 1472 TRSC_SteeringTorqueInfo 1024;
BA_ "GenSigSendType" SG_ 1472 TRSC_SteeringTorqueInfo 3;
BA_ "GenSigTimeoutTime_BSM" SG_ 1472 TRSC_SteeringTorqueInfo 0;
BA_ "GenSigTimeoutTime_BSM2" SG_ 1472 TRSC_SteeringTorqueInfo 0;
BA_ "GenSigTimeoutTime_CADM" SG_ 1472 TRSC_SteeringTorqueInfo 0;
BA_ "GenSigTimeoutTime_CVPAM" SG_ 1472 TRSC_SteeringTorqueInfo 0;
BA_ "GenSigTimeoutTime_ECM" SG_ 1472 TRSC_SteeringTorqueInfo 0;
BA_ "GenSigTimeoutTime_EVCU2" SG_ 1472 TRSC_SteeringTorqueInfo 0;
BA_ "GenSigTimeoutTime_ORC" SG_ 1472 TRSC_SteeringTorqueInfo 0;
BA_ "GenSigSendType" SG_ 1472 TRSC_SteeringTorqueReq 3;
BA_ "GenSigTimeoutTime_BSM" SG_ 1472 TRSC_SteeringTorqueReq 0;
BA_ "GenSigTimeoutTime_BSM2" SG_ 1472 TRSC_SteeringTorqueReq 0;
BA_ "GenSigTimeoutTime_CADM" SG_ 1472 TRSC_SteeringTorqueReq 0;
BA_ "GenSigTimeoutTime_CVPAM" SG_ 1472 TRSC_SteeringTorqueReq 0;
BA_ "GenSigTimeoutTime_ECM" SG_ 1472 TRSC_SteeringTorqueReq 0;
BA_ "GenSigTimeoutTime_EVCU2" SG_ 1472 TRSC_SteeringTorqueReq 0;
BA_ "GenSigTimeoutTime_ORC" SG_ 1472 TRSC_SteeringTorqueReq 0;
BA_ "GenSigStartValue" SG_ 1472 TRSC_VehicleStop_Req 3;
BA_ "GenSigSendType" SG_ 1472 TRSC_VehicleStop_Req 3;
BA_ "GenSigTimeoutTime_BSM2" SG_ 1472 TRSC_VehicleStop_Req 0;
BA_ "GenSigTimeoutTime_CADM" SG_ 1472 TRSC_VehicleStop_Req 0;
BA_ "GenSigTimeoutTime_CVPAM" SG_ 1472 TRSC_VehicleStop_Req 0;
BA_ "GenSigTimeoutTime_ECM" SG_ 1472 TRSC_VehicleStop_Req 0;
BA_ "GenSigTimeoutTime_EPS" SG_ 1472 TRSC_VehicleStop_Req 0;
BA_ "GenSigTimeoutTime_EVCU2" SG_ 1472 TRSC_VehicleStop_Req 0;
BA_ "GenSigTimeoutTime_ORC" SG_ 1472 TRSC_VehicleStop_Req 0;
BA_ "GenSigStartValue" SG_ 1472 TRSC_STAT 1;
BA_ "GenSigSendType" SG_ 1472 TRSC_STAT 3;
BA_ "GenSigTimeoutTime_BSM2" SG_ 1472 TRSC_STAT 0;
BA_ "GenSigTimeoutTime_CADM" SG_ 1472 TRSC_STAT 0;
BA_ "GenSigTimeoutTime_CVPAM" SG_ 1472 TRSC_STAT 0;
BA_ "GenSigTimeoutTime_EVCU2" SG_ 1472 TRSC_STAT 0;
BA_ "GenSigTimeoutTime_ORC" SG_ 1472 TRSC_STAT 0;
BA_ "GenSigSendType" SG_ 1472 TRSC_SpeedLimit_Req 3;
BA_ "GenSigTimeoutTime_BSM2" SG_ 1472 TRSC_SpeedLimit_Req 0;
BA_ "GenSigTimeoutTime_CADM" SG_ 1472 TRSC_SpeedLimit_Req 0;
BA_ "GenSigTimeoutTime_CVPAM" SG_ 1472 TRSC_SpeedLimit_Req 0;
BA_ "GenSigTimeoutTime_EPS" SG_ 1472 TRSC_SpeedLimit_Req 0;
BA_ "GenSigTimeoutTime_EVCU2" SG_ 1472 TRSC_SpeedLimit_Req 0;
BA_ "GenSigTimeoutTime_ORC" SG_ 1472 TRSC_SpeedLimit_Req 0;
BA_ "GenSigTimeoutTime_BSM2" SG_ 1472 MessageCounter_TRSCM1 0;
BA_ "GenSigTimeoutTime_CADM" SG_ 1472 MessageCounter_TRSCM1 0;
BA_ "GenSigTimeoutTime_CVPAM" SG_ 1472 MessageCounter_TRSCM1 0;
BA_ "GenSigTimeoutTime_EVCU2" SG_ 1472 MessageCounter_TRSCM1 0;
BA_ "GenSigTimeoutTime_ORC" SG_ 1472 MessageCounter_TRSCM1 0;
BA_ "GenSigTimeoutTime_BSM2" SG_ 1472 CRC_TRSCM1 0;
BA_ "GenSigTimeoutTime_CADM" SG_ 1472 CRC_TRSCM1 0;
BA_ "GenSigTimeoutTime_CVPAM" SG_ 1472 CRC_TRSCM1 0;
BA_ "GenSigTimeoutTime_EVCU2" SG_ 1472 CRC_TRSCM1 0;
BA_ "GenSigTimeoutTime_ORC" SG_ 1472 CRC_TRSCM1 0;
VAL_ 209 Object_Dist_VIP 255 "SNA";
VAL_ 209 ACC_DsrSpeedKPH_VIP 255 "SNA";
VAL_ 1472 TRSC_SteeringDamping 255 "SNA";
VAL_ 616 Set_Speed_MPH_VIP 255 "SNA";
VAL_ 616 Set_Speed_KPH_VIP 255 "SNA";
VAL_ 263 GasPedalPosition_PT 255 "SNA";
VAL_ 263 PdlPosActual_PT 255 "SNA";
VAL_ 292 BPCM_HV_SOC 1023 "SNA";
VAL_ 205 RearAxle_Min_Rq_BSM 0 "Not_Active" 1 "Active";
VAL_ 205 RearAxle_Max_Rq_BSM 0 "Not_Active" 1 "Active";
VAL_ 263 PowertrainPrplsnActv_PT 0 "Not_Active" 1 "Active";
VAL_ 263 ISASts_PT 0 "Not_Active" 1 "Active";
VAL_ 205 TotalAxle_Max_Rq_BSM 0 "Not_Active" 1 "Active";
VAL_ 205 TotalAxle_Min_Rq_BSM 0 "Not_Active" 1 "Active";
VAL_ 205 FrontAxle_Max_Rq_BSM 0 "Not_Active" 1 "Active";
VAL_ 205 FrontAxle_Min_Rq_BSM 0 "Not_Active" 1 "Active";
VAL_ 209 LC_Jerk_VIP 0 "Not_Active" 1 "Active";
VAL_ 209 CIPV_Fused_VIP 0 "Not_Active" 1 "Active";
VAL_ 209 Brake_Jerk_Req_VIP 0 "Not_Active" 1 "Active";
VAL_ 616 LKA_FailSts_VIP 0 "Fail_Not_Present" 1 "Fail_Present";
VAL_ 616 LKA_Blind_VIP 0 "Fail_Not_Present" 1 "Fail_Present";
VAL_ 616 DDD_FailSts_VIP 0 "Fail_Not_Present" 1 "Fail_Present";
VAL_ 616 AEB_Blind_VIP 0 "Fail_Not_Present" 1 "Fail_Present";
VAL_ 616 AEB_Limited_VIP 0 "Fail_Not_Present" 1 "Fail_Present";
VAL_ 616 AEB_Limit_Fail_VIP 0 "Fail_Not_Present" 1 "Fail_Present";
VAL_ 616 AEB_FailSts_VIP 0 "Fail_Not_Present" 1 "Fail_Present";
VAL_ 209 DDD_SystemSts_VIP 0 "OFF" 1 "ON";
VAL_ 209 PEB_SystemSts_VIP 0 "OFF" 1 "ON";
VAL_ 616 BSS_CFG_STATSts_VIP 0 "Not_enabled" 1 "Enabled_for_LED" 2 "Enabled_for_LED_and_Chime" 3 "SNA";
VAL_ 616 RR_Chime_RqSts_VIP 0 "No_rght_rear_chime_on_req" 1 "Right_rear_chime_on_req";
VAL_ 616 LR_Chime_RqSts_VIP 0 "No_left_rear_chime_on_req" 1 "Left_rear_chime_on_req";
VAL_ 204 Front_AxleTorque_Max 65535 "SNA";
VAL_ 204 Front_AxleTorque_Min 65535 "SNA";
VAL_ 204 Axle_Torque_DrvReqMod 65535 "SNA";
VAL_ 204 Axle_TorqueStatic_D_TTC 65535 "SNA";
VAL_ 204 Total_AxleTorque_Max 65535 "SNA";
VAL_ 204 Total_AxleTorque_Min 65535 "SNA";
VAL_ 210 ACC_Axle_Torque_VIP 65535 "SNA";
VAL_ 299 ACC_Axle_Torque 65535 "SNA";
VAL_ 204 Rear_AxleTorque_Min 65535 "SNA";
VAL_ 204 Rear_AxleTorque_Max 65535 "SNA";
VAL_ 205 RearAxle_Rq_BSM 65535 "SNA";
VAL_ 205 FrontAxle_Rq_BSM 65535 "SNA";
VAL_ 205 DriverRequested_AxleTrq_BSM 65535 "SNA";
VAL_ 205 TotalAxle_Rq_BSM 65535 "SNA";
VAL_ 263 GasPedalPositionFailSts_PT 0 "Fail_not_present" 1 "Fail_present";
VAL_ 292 BPCM_HV_InternalVoltage 16383 "SNA";
VAL_ 204 Rear_Axle_Regen_Capacity 16383 "SNA";
VAL_ 204 Rear_Axle_Est_Regen_Torq 16383 "SNA";
VAL_ 204 Front_Axle_Est_Regen_Torq 16383 "SNA";
VAL_ 204 Front_Axle_Regen_Capacity 16383 "SNA";
VAL_ 209 Intervention_VIP 4095 "SNA";
VAL_ 616 FCW_Setting_Avail_VIP 0 "Available" 1 "Not_Available";
VAL_ 616 PEB_Setting_Avail_VIP 0 "Available" 1 "Not_Available";
VAL_ 209 DDD_Setting_Avail_VIP 0 "Available" 1 "Not_Available";
VAL_ 209 ACC_Engine_Torque_Enabled_VIP 0 "Not_Enabled" 1 "Enabled";
VAL_ 299 ACC_Axle_Torque_Enabled 0 "Not_Enabled" 1 "Enabled";
VAL_ 263 GearEngaged_PT 0 "Neutral" 1 "ForwardGear_1" 2 "ForwardGear_2" 3 "ForwardGear_3" 4 "ForwardGear_4" 5 "ForwardGear_5" 6 "ForwardGear_6" 7 "ForwardGear_7" 8 "ForwardGear_8" 9 "ForwardGear_9" 13 "Parking" 14 "ReverseGear" 15 "SNA";
VAL_ 263 TargetGear_PT 0 "Neutral" 1 "ForwardGear_1" 2 "ForwardGear_2" 3 "ForwardGear_3" 4 "ForwardGear_4" 5 "ForwardGear_5" 6 "ForwardGear_6" 7 "ForwardGear_7" 8 "ForwardGear_8" 9 "ForwardGear_9" 13 "Parking" 14 "ReverseGear" 15 "SNA";
VAL_ 263 SpeedLimitSts_PT 0 "Standby" 1 "Activated" 2 "Not_Actuable" 3 "Override" 4 "Overspeed" 5 "Deactivated" 6 "Off" 7 "SNA";
VAL_ 209 Prefill_Req_VIP 0 "No_Prefill_Requested" 1 "Prefill_Requested";
VAL_ 209 GrMax_Rq_ACC_VIP 0 "Passive" 1 "G1" 2 "G2" 3 "G3" 4 "G4" 5 "G5" 6 "G6" 7 "G7" 8 "G8" 9 "G9" 10 "G10" 11 "G11" 12 "G12" 13 "G13" 14 "G14" 15 "G15";
VAL_ 213 DASEngReqPos_D5 0 "Not_Allowed" 1 "Allowed";
VAL_ 205 DrvrIntd_TotalBrk_AxleTorq 32767 "SNA";
VAL_ 205 Cmnd_TotBrkFrict_AxleTorq 32767 "SNA";
VAL_ 616 BSS_SRV_RQSts_VIP 0 "No_Service_Request" 1 "Service_Request";
VAL_ 616 BSS_Blind_RQSts_VIP 0 "No_Sensor_Blocked_Request" 1 "Sensor_Blocked_Request";
VAL_ 1472 TRSC_SteeringTorqueReq 0 "False" 1 "True" 3 "SNA";
VAL_ 1472 THA_SteeringTorqueReq 0 "False" 1 "True" 3 "SNA";
VAL_ 1472 TRSC_VehicleStop_Req 0 "False" 1 "True" 3 "SNA";
VAL_ 2654486689 CBV_bit4_ActiveWakeupBit_1E3840A1 0 "PassiveWakeup" 1 "ActiveWakeup";
VAL_ 2654486701 CBV_bit4_ActiveWakeupBit_1E3840AD 0 "PassiveWakeup" 1 "ActiveWakeup";
VAL_ 2654486554 CBV_bit4_ActiveWakeupBit_1E38401A 0 "PassiveWakeup" 1 "ActiveWakeup";
VAL_ 2654486592 CBV_bit4_ActiveWakeupBit_1E384040 0 "PassiveWakeup" 1 "ActiveWakeup";
VAL_ 2654486554 CBV_bit6_PartialNtwInfBit_1E38401A 0 "NM PDU contains no Partial Network request information" 1 "NM PDU contains Partial Network request information";
VAL_ 2654486554 CBV_bit3_NMCoordinatorBit_1E38401A 0 "Start of synchronized shutdown is not requested by main coordinator" 1 "Start of synchronized shutdown is requested by main coordinator";
VAL_ 2654486554 CBV_bit0_RepeatMessageRequestBit_1E38401A 0 "Repeat Message State not requested" 1 "Repeat Message State requested";
VAL_ 616 ICA_Blind_VIP 0 "Blinded" 1 "Not_Blinded";
VAL_ 616 DDD_DispPopupSts_VIP 0 "No_Code" 1 "Drowsniness_Detected" 2 "DDD_Perm_Fail" 3 "SNA";
VAL_ 209 SteeringVibration_Type_VIP 0 "TYPE_0" 1 "TYPE_1" 2 "TYPE_2" 3 "TYPE_3" 4 "TYPE_4" 5 "TYPE_5" 6 "TYPE_6" 7 "TYPE_7" 8 "TYPE_8" 9 "TYPE_9" 10 "TYPE_10" 11 "TYPE_11" 15 "SNA";
VAL_ 209 SteeringVibration_Rq_VIP 0 "NOT_REQUESTED" 1 "REQUESTED";
VAL_ 209 LKA_LAT_CTRL_RequestSts_VIP 0 "Idle" 1 "Faulted" 2 "LKA_Request";
VAL_ 209 AEB_Systemsts_VIP 0 "FCW_Off" 1 "FCW_On_Only_Warning" 2 "FCW_On_Full";
VAL_ 209 AEB_Sensitivity_Setting_VIP 0 "NEAR" 1 "MEDIUM" 2 "FAR";
VAL_ 616 BlindSpotRightWarn_VIP 0 "No_Req" 1 "Solid" 2 "Flashing";
VAL_ 616 BlindSpotLeftWarn_VIP 0 "No_Req" 1 "Solid" 2 "Flashing";
VAL_ 213 LKA_LAT_CTRL_ResponseSts_D5 0 "IDLE" 1 "Permanent_Not_Avail" 2 "Temporarily_Not_Avail" 3 "LKA_Open";
VAL_ 1472 TRSC_SpeedLimit_Req 0 "Not_Limiting" 1 "SPD_4" 2 "SPD_5" 3 "SPD_6" 4 "SPD_7" 5 "SPD_8" 6 "SPD_9" 7 "SPD_10" 15 "SNA";
VAL_ 292 BPCM_HV_Trac_Main_Contac_Sts 0 "Open" 1 "Closed" 3 "Error_Stuck_Open" 4 "Error_Stuck_Closed" 7 "SNA";
VAL_ 209 ACC_Systemsts_VIP 0 "OFF" 1 "ACC_Enabled" 2 "ACC_Engaged" 3 "ACC_Engaged_BrakeOnly" 4 "ACC_Cancel" 5 "NCC_Enabled" 6 "NCC_Engaged" 7 "NCC_Cancel" 8 "HAS_BSoC" 9 "RRCC_Enabled_No_Set_Speed" 10 "RRCC_Enabled_With_Set_Speed" 11 "RRCC_Engaged" 15 "SNA";
VAL_ 213 AEB_Type_Brk_D5 0 "NONE" 1 "ACC" 2 "CMS" 3 "CMS_XTD" 4 "ABA" 5 "LSCM" 6 "PEB" 7 "ICA_L" 8 "ICA_R" 9 "HAS_MRM" 10 "RRCC" 15 "SNA";
VAL_ 209 AEB_Type_VIP 0 "NONE" 1 "ACC" 2 "CMS" 3 "CMS_XTD" 4 "ABA" 5 "LSCM" 6 "PEB" 7 "ICA_L" 8 "ICA_R" 9 "HAS_MRM" 10 "RRCC" 15 "SNA";
VAL_ 616 AEB_DispPopupSts_VIP 0 "No_Code" 1 "Pre_Intervention_Warning" 4 "Braking_Complete" 5 "AEB_Unavailble_ESC_Off" 6 "AEB_Unavailble_4WD_Low" 7 "Active_Braking_Enabled" 8 "Active_Braking_Disabled" 9 "AEB_User_Disabled" 10 "AEB_Radar_Blind" 11 "Pre_Intervention_Warning_VRU_L" 12 "AEB_Fail" 13 "Pre_Intervention_Warning_VRU_R" 14 "AEB_Cam_Blind" 15 "Not_used3" 16 "AEB_LIMITED_Fail" 17 "PEB_Off" 18 "PEB_On" 19 "PEB_Radar_Blind" 20 "PEB_Fail" 21 "PEB_Cam_Blind" 22 "FCW_Limited_PEB_Off_Camera_Blinded" 23 "FCW_Limited_PEB_Off_Camera_Fail" 24 "Pre_Intervention_Warning_ICA_L" 25 "Pre_Intervention_Warning_ICA_R" 26 "AEB_Limit_Corner_Blind" 27 "AEB_Unavail_Corsa" 28 "AEB_Unavail_Off_Road" 29 "AEB_Cancel_ESC_Off" 30 "AEB_Cancel_Off_Road" 31 "AEB_Unavail_HDC";
VAL_ 213 RRCC_Cancel_Req_D5 0 "No_request" 1 "Requests temporary off" 2 "Request continuous off" 3 "SNA";
VAL_ 292 BPCM_HV_Trac_Bus_Sts 0 "Open" 1 "Closed" 2 "Precharging" 3 "Precharging_Failed" 4 "Precharging_Inhibited" 7 "SNA";
VAL_ 205 DriverReq_AxleTrq_Enabled_BSM 0 "No_Req" 1 "ACC_NCC" 2 "SSC" 3 "PPPA" 4 "RRCC" 15 "SNA";
VAL_ 1472 THA_EPB_Req 0 "No_Request" 1 "EPB_Requested" 3 "SNA";
VAL_ 1472 THA_Speed_Limit 0 "No_Request" 1 "kph_1" 2 "kph_2" 3 "kph_3" 4 "kph_4" 5 "kph_5" 6 "kph_6" 7 "kph_7" 8 "kph_8" 9 "kph_9" 10 "kph_10" 31 "SNA";
VAL_ 1472 THA_SpeedLimit_Req 0 "No_Request" 1 "Requested" 3 "SNA";
VAL_ 1472 THA_STAT 0 "Initial" 1 "Idle" 2 "Enabled" 3 "Engaged" 4 "Complete" 5 "Faulted " 7 "SNA";
VAL_ 263 EVCU2_THA_Resp 0 "Off" 1 "Active" 3 "SNA";
VAL_ 263 DriveReady_PT 0 "Default" 1 "Veh_Allwd_Shift_Out_Of_P_Or_N";
VAL_ 263 GearEngagedForDisplay_PT 0 "Initialize" 1 "Gear_1st" 2 "Gear_2nd" 3 "Gear_3rd" 4 "Gear_4th" 5 "Gear_5th" 6 "Gear_6th" 7 "Gear_7th" 8 "Gear_8th" 9 "Gear_9th" 12 "Park" 13 "Neutral" 14 "Reverse" 15 "Drive" 16 "Low" 17 "Manual" 18 "Sport_Mode" 31 "SNA";
VAL_ 1472 TRSC_STAT 0 "Standby" 1 "Calibrating" 2 "PreActive" 3 "Active" 4 "OFF" 7 "SNA";
VAL_ 263 ShiftLeverPosition_PT 0 "No_Selection_Active_Or_Available" 1 "Park" 2 "Reverse" 3 "Neutral" 4 "Drive" 5 "Low" 6 "TIP_Autostick" 7 "Plus" 8 "Minus" 9 "Sport" 15 "SNA";
VAL_ 2654486701 CBV_bit6_PartialNtwInfBit_1E3840AD 0 "Partial_Network_info_contained" 1 "No_Partial_Network_info_contained";
VAL_ 2654486689 CBV_bit6_PartialNtwInfBit_1E3840A1 0 "Partial_Network_info_contained" 1 "No_Partial_Network_info_contained";
VAL_ 2654486689 CBV_bit3_NMCoordinatorBit_1E3840A1 0 "Synch_shutdown_not_requested" 1 "Synch_shutdown_requested";
VAL_ 2654486701 CBV_bit3_NMCoordinatorBit_1E3840AD 0 "Synch_shutdown_not_requested" 1 "Synch_shutdown_requested";
VAL_ 2654486701 CBV_bit0_RepeatMessageRequestBit_1E3840AD 0 "Repeat_Msg_State_not_requested" 1 "Repeat_Msg_State_requested";
VAL_ 2654486689 CBV_bit0_RepeatMessageRequestBit_1E3840A1 0 "Repeat_Msg_State_not_requested" 1 "Repeat_Msg_State_requested";
VAL_ 97 GTS_Type 16 "SYNC" 24 "FUP" 32 "SYNC_CRC" 40 "FUP_CRC" 48 "OFS" 56 "OFNS" 64 "OFS_CRC" 72 "OFNS_CRC" 84 "OFS_FD" 100 "OFS_FD_CRC";
VAL_ 616 BSS_TrailerSts_VIP 0 "NONE" 1 "TRAILER_AUTO" 2 "TRAILER_MAX" 3 "TRAILER_0_3" 4 "TRAILER_3_6" 5 "TRAILER_6_9" 6 "MAX" 7 "SNA";
VAL_ 616 BSS_DispPopoupSts_VIP 0 "No_Req" 1 "BSS_Trailer_On" 7 "SNA";
VAL_ 730 Line_4_Type 0 "None" 1 "Solid" 2 "Dashed" 3 "Double" 4 "Road_edge" 5 "Botts_Dotts" 6 "Barrier";
VAL_ 730 Line_1_Type 0 "None" 1 "Solid" 2 "Dashed" 3 "Double" 4 "Road_edge" 5 "Botts_Dotts" 6 "Barrier";
VAL_ 730 Line_2_Type 0 "None" 1 "Solid" 2 "Dashed" 3 "Double" 4 "Road_edge" 5 "Botts_Dotts" 6 "Barrier";
VAL_ 730 Health_Lane_Detection 0 "Faulted" 1 "Blocked" 2 "Unknown" 3 "Healthy";
VAL_ 730 Health_Front_Object_Detection 0 "Faulted" 1 "Blocked" 2 "Unknown" 3 "Healthy";
VAL_ 730 FOD_Confidence 0 "Not_Detected" 1 "Detected_Low_Confidence" 2 "Detected_Medium_Confidence" 3 "Detected_High_Confidence";
VAL_ 730 Camera_Status 0 "None_Active" 1 "Left_Right_Front" 2 "Left_Right" 3 "Left_Front" 4 "Right_Front" 5 "Front" 6 "Left" 7 "Right";
VAL_ 730 Line_3_Type 0 "None" 1 "Solid" 2 "Dashed" 3 "Double" 4 "Road_edge" 5 "Botts_Dotts" 6 "Barrier";
SIG_GROUP_ 204 AXLE_TORQUE_FD_1_Pkt 1 : Front_AxleTorque_Max Front_AxleTorque_Min Axle_Torque_DrvReqMod Axle_TorqueStatic_D_TTC Total_AxleTorque_Max Total_AxleTorque_Min Front_Axle_Est_Regen_Torq CRC_AXLE_TORQUE_FD_1 MessageCounter_AXLE_TORQUE_FD_1 Rear_AxleTorque_Min Rear_AxleTorque_Max Rear_Axle_Regen_Capacity Rear_Axle_Est_Regen_Torq Front_Axle_Regen_Capacity;
SIG_GROUP_ 205 BRAKE_FD_6_Pkt 1 : FrontAxle_Rq_BSM DriverRequested_AxleTrq_BSM TotalAxle_Rq_BSM Cmnd_TotBrkFrict_AxleTorq DriverReq_AxleTrq_Enabled_BSM DrvrIntd_TotalBrk_AxleTorq TotalAxle_Max_Rq_BSM TotalAxle_Min_Rq_BSM FrontAxle_Max_Rq_BSM FrontAxle_Min_Rq_BSM MessageCounter_BRAKE_FD_6 CRC_BRAKE_FD_6 RearAxle_Rq_BSM RearAxle_Min_Rq_BSM RearAxle_Max_Rq_BSM;
SIG_GROUP_ 1472 TRSCM_FD_1_Pkt 1 : CRC_TRSCM1 MessageCounter_TRSCM1 THA_EPB_Req THA_Speed_Limit THA_SpeedLimit_Req THA_STAT TRSC_SpeedLimit_Req TRSC_STAT TRSC_VehicleStop_Req TRSC_SteeringTorqueReq TRSC_SteeringTorqueInfo TRSC_SteeringDamping THA_SteeringTorqueReq THA_SteeringTorqueInfo THA_SteeringDamping;
SIG_GROUP_ 263 PT_SYSTEM_FD_1_Pkt 1 : CRC_PT_SYSTEM_FD_1 GasPedalPosition_PT GasPedalPositionFailSts_PT MessageCounter_PT_SYSTEM_FD_1 DriveReady_PT GearEngaged_PT GearEngagedForDisplay_PT PowertrainPrplsnActv_PT TargetGear_PT ShiftLeverPosition_PT PdlPosActual_PT SpeedLimitSts_PT ISASts_PT EVCU2_THA_Resp;
SIG_GROUP_ 299 ADAS_FD_INFO3_Pkt 1 : ACC_Axle_Torque_Enabled ACC_Axle_Torque MessageCounter_ADAS_FD_INFO3 CRC_ADAS_FD_INFO3;
SIG_GROUP_ 292 BATTERY_HV_STATUS1_Pkt 1 : BPCM_HV_Trac_Bus_Sts BPCM_HV_Trac_Main_Contac_Sts BPCM_HV_InternalVoltage BPCM_HV_SOC;
